VERSION ""

NS_ :

BS_:

BU_: PowertrainControlModule AtmosphericSensor SafetyRestraintSystem2 Aftertreatment_2_GasOutlet Aftertreatment_2_GasIntake DieselParticulateFilterControl Turbocharger SafetyRestraintSystem1 CabDisplay2 Aftertreatment_1_GasOutlet Aftertreatment_1_GasIntake OnBoardDataLogger OffBoardDiagnosticTool2 OffBoardDiagnosticTool1 FileServer ParkingBrakeController SeatController2 FanDriveController SteeringColumnUnit CommunicationUnitRadio CommunicationUnitSatellite CommunicationUnitCellular PropulsionBatteryCharger ChassisController2 ChassisController1 EngineValveControl AuxiliaryHeater2 AuxiliaryHeater1 ClutchUnit RampControl InformationSystem1 SuspensionSystemController2 OilSensor VehicleDynamicStability ExhaustEmissionController TransmissionDisplay2 TransmissionDisplay1 ClimateControl2 WaterPumpController RearAxleSteeringController LightingOperatorControl SeatController1 IgnitionController2 IgnitionController1 TirePressureController CabController2 CabController1 PneumaticSystemController SuspensionSystemController1 HydraulicPumpController EnduranceBrakingSystem RetarderExhaustEngine2 OnBoardDiagnosticUnit HeadwayController RetarderExhaustEngine1 CabDisplay1 ManagementComputer VirtualTerminal OffVehicleGateway PowerTakeOffFront HitchControl AuxiliaryValveControl BodyController TractorTrailerBridge1 StarterSystem ElectricalSystem VehicleSecurity VehicleNavigation AerodynamicControl ElectricalChargingSystem ClimateControl1 TripRecorder InstrumentCluster SuspensionDriveAxle2 SuspensionDriveAxle1 SuspensionSteerAxle SteeringController FuelSystem CruiseControl RetarderDriveline RetarderEngine BrakesDriveAxle2 BrakesDriveAxle1 BrakesSystemController BrakesSteerAxle AxleDrive2 AxleDrive1 AxleSteering PowerTakeOff ShiftConsoleSecondary ShiftConsolePrimary Transmission2 Transmission1 Engine2 Engine1

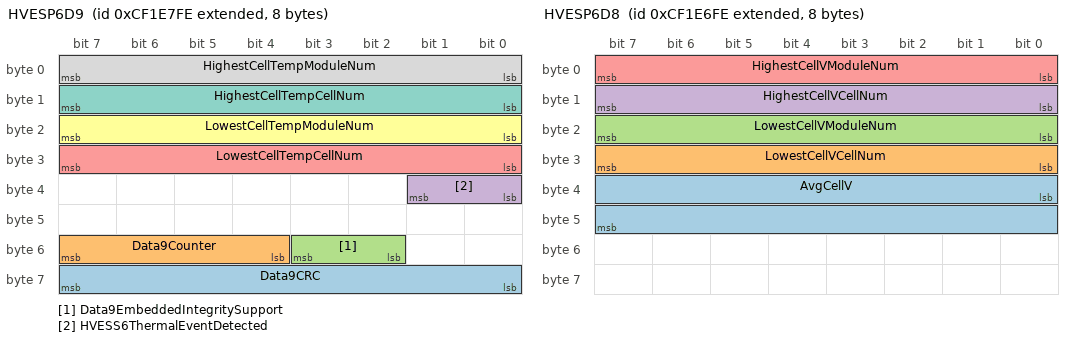
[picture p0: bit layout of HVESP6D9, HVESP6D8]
BO_ 2364663806 HVESP6D9: 8 Vector__XXX
 SG_ Data9CRC : 56|8@1+ (1,0) [0|255] "" Vector__XXX
 SG_ Data9Counter : 52|4@1+ (1,0) [0|15] "" Vector__XXX
 SG_ Data9EmbeddedIntegritySupport : 50|2@1+ (1,0) [0|3] "" Vector__XXX
 SG_ HVESS6ThermalEventDetected : 32|2@1+ (1,0) [0|3] "" Vector__XXX
 SG_ LowestCellTempCellNum : 24|8@1+ (1,0) [0|250] "" Vector__XXX
 SG_ LowestCellTempModuleNum : 16|8@1+ (1,0) [0|250] "" Vector__XXX
 SG_ HighestCellTempCellNum : 8|8@1+ (1,0) [0|250] "" Vector__XXX
 SG_ HighestCellTempModuleNum : 0|8@1+ (1,0) [0|250] "" Vector__XXX

BO_ 2364663550 HVESP6D8: 8 Vector__XXX
 SG_ AvgCellV : 32|16@1+ (0.001,0) [0|64.255] "V" Vector__XXX
 SG_ LowestCellVCellNum : 24|8@1+ (1,0) [0|250] "" Vector__XXX
 SG_ LowestCellVModuleNum : 16|8@1+ (1,0) [0|250] "" Vector__XXX
 SG_ HighestCellVCellNum : 8|8@1+ (1,0) [0|250] "" Vector__XXX
 SG_ HighestCellVModuleNum : 0|8@1+ (1,0) [0|250] "" Vector__XXX

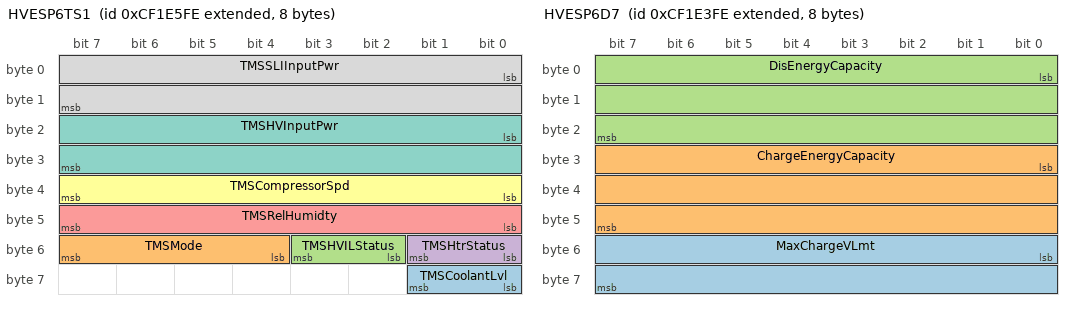
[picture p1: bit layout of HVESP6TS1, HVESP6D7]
BO_ 2364663294 HVESP6TS1: 8 Vector__XXX
 SG_ TMSCoolantLvl : 56|2@1+ (1,0) [0|3] "" Vector__XXX
 SG_ TMSMode : 52|4@1+ (1,0) [0|15] "" Vector__XXX
 SG_ TMSHVILStatus : 50|2@1+ (1,0) [0|3] "" Vector__XXX
 SG_ TMSHtrStatus : 48|2@1+ (1,0) [0|3] "" Vector__XXX
 SG_ TMSRelHumidty : 40|8@1+ (0.4,0) [0|100] "%" Vector__XXX
 SG_ TMSCompressorSpd : 32|8@1+ (32,0) [0|8000] "rpm" Vector__XXX
 SG_ TMSHVInputPwr : 16|16@1+ (0.5,0) [0|32127.5] "W" Vector__XXX
 SG_ TMSSLIInputPwr : 0|16@1+ (0.5,0) [0|32127.5] "W" Vector__XXX

BO_ 2364663038 HVESP6MS1: 8 Vector__XXX
 SG_ Module32OperationalStatus : 62|2@1+ (1,0) [0|3] "" Vector__XXX
 SG_ Module31OperationalStatus : 60|2@1+ (1,0) [0|3] "" Vector__XXX
 SG_ Module30OperationalStatus : 58|2@1+ (1,0) [0|3] "" Vector__XXX
 SG_ Module29OperationalStatus : 56|2@1+ (1,0) [0|3] "" Vector__XXX
 SG_ Module28OperationalStatus : 54|2@1+ (1,0) [0|3] "" Vector__XXX
 SG_ Module27OperationalStatus : 52|2@1+ (1,0) [0|3] "" Vector__XXX
 SG_ Module26OperationalStatus : 50|2@1+ (1,0) [0|3] "" Vector__XXX
 SG_ Module25OperationalStatus : 48|2@1+ (1,0) [0|3] "" Vector__XXX
 SG_ Module24OperationalStatus : 46|2@1+ (1,0) [0|3] "" Vector__XXX
 SG_ Module23OperationalStatus : 44|2@1+ (1,0) [0|3] "" Vector__XXX
 SG_ Module22OperationalStatus : 42|2@1+ (1,0) [0|3] "" Vector__XXX
 SG_ Module21OperationalStatus : 40|2@1+ (1,0) [0|3] "" Vector__XXX
 SG_ Module20OperationalStatus : 38|2@1+ (1,0) [0|3] "" Vector__XXX
 SG_ Module19OperationalStatus : 36|2@1+ (1,0) [0|3] "" Vector__XXX
 SG_ Module18OperationalStatus : 34|2@1+ (1,0) [0|3] "" Vector__XXX
 SG_ Module17OperationalStatus : 32|2@1+ (1,0) [0|3] "" Vector__XXX
 SG_ Module16OperationalStatus : 30|2@1+ (1,0) [0|3] "" Vector__XXX
 SG_ Module15OperationalStatus : 28|2@1+ (1,0) [0|3] "" Vector__XXX
 SG_ Module14OperationalStatus : 26|2@1+ (1,0) [0|3] "" Vector__XXX
 SG_ Module13OperationalStatus : 24|2@1+ (1,0) [0|3] "" Vector__XXX
 SG_ Module12OperationalStatus : 22|2@1+ (1,0) [0|3] "" Vector__XXX
 SG_ Module11OperationalStatus : 20|2@1+ (1,0) [0|3] "" Vector__XXX
 SG_ Module10OperationalStatus : 18|2@1+ (1,0) [0|3] "" Vector__XXX
 SG_ Module9OperationalStatus : 16|2@1+ (1,0) [0|3] "" Vector__XXX
 SG_ Module8OperationalStatus : 14|2@1+ (1,0) [0|3] "" Vector__XXX
 SG_ Module7OperationalStatus : 12|2@1+ (1,0) [0|3] "" Vector__XXX
 SG_ Module6OperationalStatus : 10|2@1+ (1,0) [0|3] "" Vector__XXX
 SG_ Module5OperationalStatus : 8|2@1+ (1,0) [0|3] "" Vector__XXX
 SG_ Module4OperationalStatus : 6|2@1+ (1,0) [0|3] "" Vector__XXX
 SG_ Module3OperationalStatus : 4|2@1+ (1,0) [0|3] "" Vector__XXX
 SG_ Module2OperationalStatus : 2|2@1+ (1,0) [0|3] "" Vector__XXX
 SG_ Module1OperationalStatus : 0|2@1+ (1,0) [0|3] "" Vector__XXX

BO_ 2364662782 HVESP6D7: 8 Vector__XXX
 SG_ MaxChargeVLmt : 48|16@1+ (0.05,0) [0|3212.75] "V" Vector__XXX
 SG_ ChargeEnergyCapacity : 24|24@1+ (0.001,0) [0|16449.535] "kWh" Vector__XXX
 SG_ DisEnergyCapacity : 0|24@1+ (0.001,0) [0|16449.535] "kWh" Vector__XXX

BO_ 2364662526 HVESP6S1: 8 Vector__XXX
 SG_ Status1CRC : 56|8@1+ (1,0) [0|255] "" Vector__XXX
 SG_ Status1Counter : 52|4@1+ (1,0) [0|15] "" Vector__XXX
 SG_ OperationalStatus : 44|4@1+ (1,0) [0|15] "" Vector__XXX
 SG_ HVBusConnectionStatus : 40|4@1+ (1,0) [0|15] "" Vector__XXX
 SG_ InternalChargerStatus : 32|2@1+ (1,0) [0|3] "" Vector__XXX
 SG_ CellBalancingActive : 30|2@1+ (1,0) [0|3] "" Vector__XXX
 SG_ CellBalanceStatus : 28|2@1+ (1,0) [0|3] "" Vector__XXX
 SG_ StOfChargeStatus : 24|4@1+ (1,0) [0|15] "" Vector__XXX
 SG_ InertiaSwStatus : 22|2@1+ (1,0) [0|3] "" Vector__XXX
 SG_ HVILStatus : 20|2@1+ (1,0) [0|3] "" Vector__XXX
 SG_ HVBusPassiveIsolTestStatus : 16|4@1+ (1,0) [0|15] "" Vector__XXX
 SG_ HVBusActiveIsolTestStatus : 12|4@1+ (1,0) [0|15] "" Vector__XXX
 SG_ CenterOfPackContactorSt : 10|2@1+ (1,0) [0|3] "" Vector__XXX
 SG_ HVBusPreChargeRelaySt : 8|2@1+ (1,0) [0|3] "" Vector__XXX
 SG_ HVBusDisconnectForewarning : 4|4@1+ (1,0) [0|15] "" Vector__XXX
 SG_ HVBusContactorSt11656 : 2|2@1+ (1,0) [0|3] "" Vector__XXX
 SG_ HVBusContactorSt : 0|2@1+ (1,0) [0|3] "" Vector__XXX

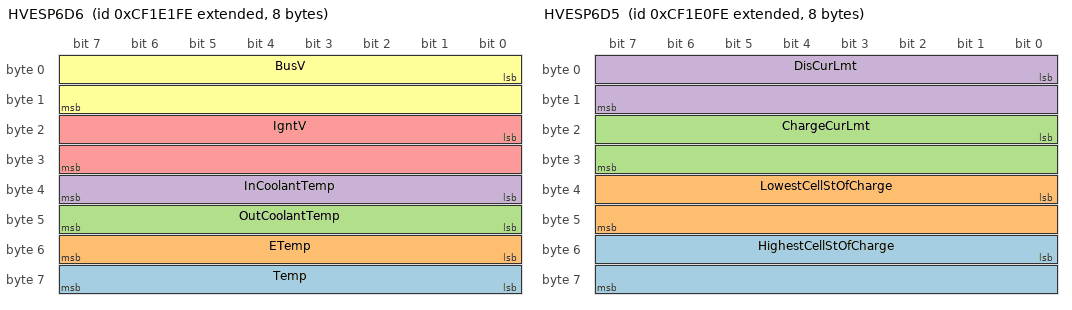
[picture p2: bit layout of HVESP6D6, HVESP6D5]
BO_ 2364662270 HVESP6D6: 8 Vector__XXX
 SG_ Temp : 56|8@1+ (1,-40) [-40|210] "°C" Vector__XXX
 SG_ ETemp : 48|8@1+ (1,-40) [-40|210] "°C" Vector__XXX
 SG_ OutCoolantTemp : 40|8@1+ (1,-40) [-40|210] "°C" Vector__XXX
 SG_ InCoolantTemp : 32|8@1+ (1,-40) [-40|210] "°C" Vector__XXX
 SG_ IgntV : 16|16@1+ (0.01,0) [0|642.55] "V" Vector__XXX
 SG_ BusV : 0|16@1+ (0.05,0) [0|3212.75] "V" Vector__XXX

BO_ 2364662014 HVESP6D5: 8 Vector__XXX
 SG_ HighestCellStOfCharge : 48|16@1+ (0.0015625,0) [0|100.3984375] "%" Vector__XXX
 SG_ LowestCellStOfCharge : 32|16@1+ (0.0015625,0) [0|100.3984375] "%" Vector__XXX
 SG_ ChargeCurLmt : 16|16@1+ (0.05,-1600) [0|1612.75] "A" Vector__XXX
 SG_ DisCurLmt : 0|16@1+ (0.05,-1600) [-1600|0] "A" Vector__XXX

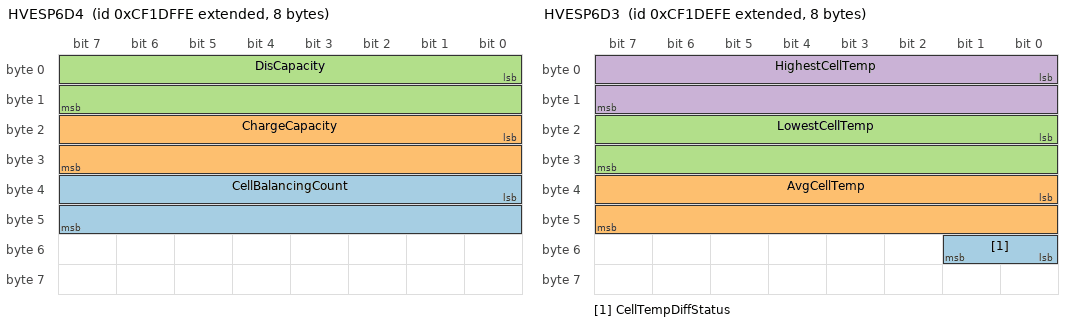
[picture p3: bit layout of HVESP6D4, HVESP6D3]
BO_ 2364661758 HVESP6D4: 8 Vector__XXX
 SG_ CellBalancingCount : 32|16@1+ (1,0) [0|64255] "" Vector__XXX
 SG_ ChargeCapacity : 16|16@1+ (0.01,0) [0|642.55] "Ah" Vector__XXX
 SG_ DisCapacity : 0|16@1+ (0.01,0) [0|642.55] "Ah" Vector__XXX

BO_ 2364661502 HVESP6D3: 8 Vector__XXX
 SG_ CellTempDiffStatus : 48|2@1+ (1,0) [0|3] "" Vector__XXX
 SG_ AvgCellTemp : 32|16@1+ (0.03125,-273) [-273|1734.96875] "°C" Vector__XXX
 SG_ LowestCellTemp : 16|16@1+ (0.03125,-273) [-273|1734.96875] "°C" Vector__XXX
 SG_ HighestCellTemp : 0|16@1+ (0.03125,-273) [-273|1734.96875] "°C" Vector__XXX

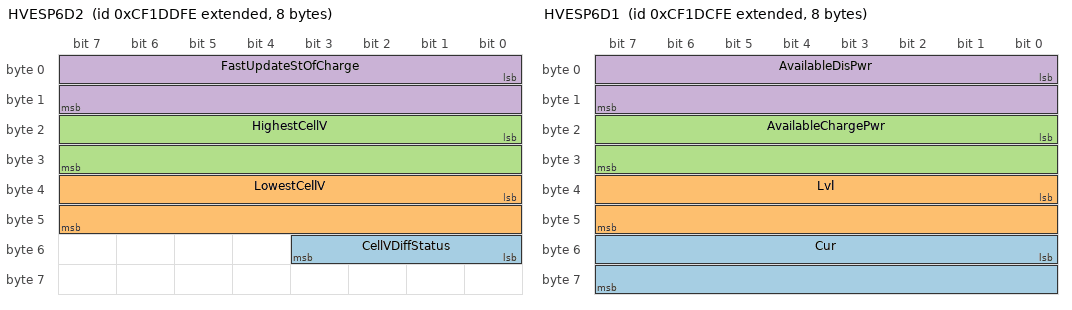
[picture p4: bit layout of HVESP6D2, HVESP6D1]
BO_ 2364661246 HVESP6D2: 8 Vector__XXX
 SG_ CellVDiffStatus : 48|4@1+ (1,0) [0|15] "" Vector__XXX
 SG_ LowestCellV : 32|16@1+ (0.001,0) [0|64.255] "V" Vector__XXX
 SG_ HighestCellV : 16|16@1+ (0.001,0) [0|64.255] "V" Vector__XXX
 SG_ FastUpdateStOfCharge : 0|16@1+ (0.0015625,0) [0|100.3984375] "%" Vector__XXX

BO_ 2364660990 HVESP6D1: 8 Vector__XXX
 SG_ Cur : 48|16@1+ (0.05,-1600) [-1600|1612.75] "A" Vector__XXX
 SG_ Lvl : 32|16@1+ (0.05,0) [0|3212.75] "V" Vector__XXX
 SG_ AvailableChargePwr : 16|16@1+ (0.05,0) [0|3212.75] "kW" Vector__XXX
 SG_ AvailableDisPwr : 0|16@1+ (0.05,0) [0|3212.75] "kW" Vector__XXX

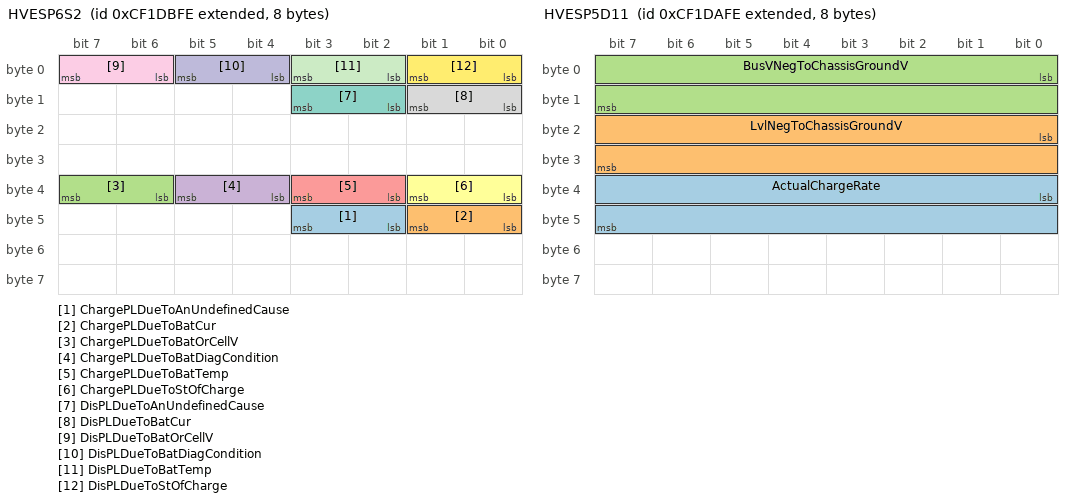
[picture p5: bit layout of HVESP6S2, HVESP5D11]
BO_ 2364660734 HVESP6S2: 8 Vector__XXX
 SG_ ChargePLDueToAnUndefinedCause : 42|2@1+ (1,0) [0|3] "" Vector__XXX
 SG_ ChargePLDueToBatCur : 40|2@1+ (1,0) [0|3] "" Vector__XXX
 SG_ ChargePLDueToBatOrCellV : 38|2@1+ (1,0) [0|3] "" Vector__XXX
 SG_ ChargePLDueToBatDiagCondition : 36|2@1+ (1,0) [0|3] "" Vector__XXX
 SG_ ChargePLDueToBatTemp : 34|2@1+ (1,0) [0|3] "" Vector__XXX
 SG_ ChargePLDueToStOfCharge : 32|2@1+ (1,0) [0|3] "" Vector__XXX
 SG_ DisPLDueToAnUndefinedCause : 10|2@1+ (1,0) [0|3] "" Vector__XXX
 SG_ DisPLDueToBatCur : 8|2@1+ (1,0) [0|3] "" Vector__XXX
 SG_ DisPLDueToBatOrCellV : 6|2@1+ (1,0) [0|3] "" Vector__XXX
 SG_ DisPLDueToBatDiagCondition : 4|2@1+ (1,0) [0|3] "" Vector__XXX
 SG_ DisPLDueToBatTemp : 2|2@1+ (1,0) [0|3] "" Vector__XXX
 SG_ DisPLDueToStOfCharge : 0|2@1+ (1,0) [0|3] "" Vector__XXX

BO_ 2364660478 HVESP5D11: 8 Vector__XXX
 SG_ ActualChargeRate : 32|16@1+ (0.05,0) [0|3212.75] "kW" Vector__XXX
 SG_ LvlNegToChassisGroundV : 16|16@1+ (0.05,0) [0|3212.75] "V" Vector__XXX
 SG_ BusVNegToChassisGroundV : 0|16@1+ (0.05,0) [0|3212.75] "V" Vector__XXX

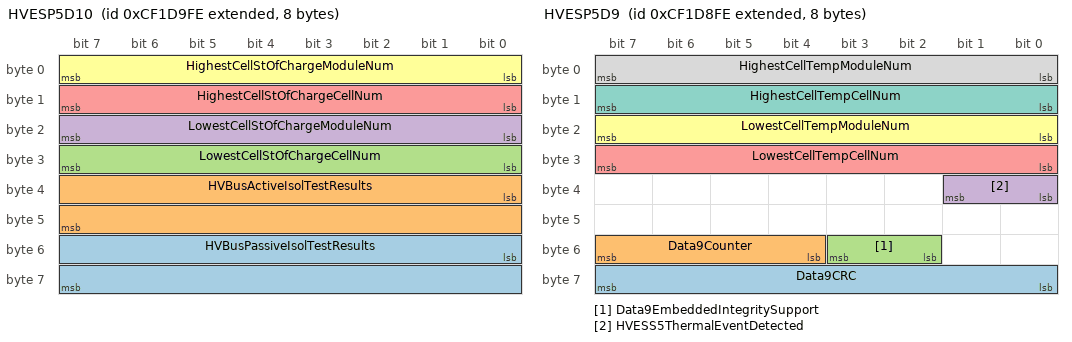
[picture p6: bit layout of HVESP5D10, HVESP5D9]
BO_ 2364660222 HVESP5D10: 8 Vector__XXX
 SG_ HVBusPassiveIsolTestResults : 48|16@1+ (0.1,0) [0|6425.5] "Ohm/V" Vector__XXX
 SG_ HVBusActiveIsolTestResults : 32|16@1+ (0.1,0) [0|6425.5] "Ohm/V" Vector__XXX
 SG_ LowestCellStOfChargeCellNum : 24|8@1+ (1,0) [0|250] "" Vector__XXX
 SG_ LowestCellStOfChargeModuleNum : 16|8@1+ (1,0) [0|250] "" Vector__XXX
 SG_ HighestCellStOfChargeCellNum : 8|8@1+ (1,0) [0|250] "" Vector__XXX
 SG_ HighestCellStOfChargeModuleNum : 0|8@1+ (1,0) [0|250] "" Vector__XXX

BO_ 2364659966 HVESP5D9: 8 Vector__XXX
 SG_ Data9CRC : 56|8@1+ (1,0) [0|255] "" Vector__XXX
 SG_ Data9Counter : 52|4@1+ (1,0) [0|15] "" Vector__XXX
 SG_ Data9EmbeddedIntegritySupport : 50|2@1+ (1,0) [0|3] "" Vector__XXX
 SG_ HVESS5ThermalEventDetected : 32|2@1+ (1,0) [0|3] "" Vector__XXX
 SG_ LowestCellTempCellNum : 24|8@1+ (1,0) [0|250] "" Vector__XXX
 SG_ LowestCellTempModuleNum : 16|8@1+ (1,0) [0|250] "" Vector__XXX
 SG_ HighestCellTempCellNum : 8|8@1+ (1,0) [0|250] "" Vector__XXX
 SG_ HighestCellTempModuleNum : 0|8@1+ (1,0) [0|250] "" Vector__XXX

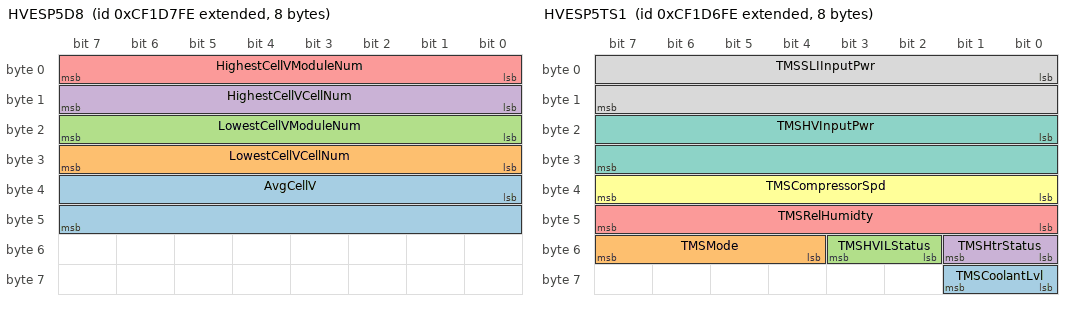
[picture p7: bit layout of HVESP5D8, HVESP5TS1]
BO_ 2364659710 HVESP5D8: 8 Vector__XXX
 SG_ AvgCellV : 32|16@1+ (0.001,0) [0|64.255] "V" Vector__XXX
 SG_ LowestCellVCellNum : 24|8@1+ (1,0) [0|250] "" Vector__XXX
 SG_ LowestCellVModuleNum : 16|8@1+ (1,0) [0|250] "" Vector__XXX
 SG_ HighestCellVCellNum : 8|8@1+ (1,0) [0|250] "" Vector__XXX
 SG_ HighestCellVModuleNum : 0|8@1+ (1,0) [0|250] "" Vector__XXX

BO_ 2364659454 HVESP5TS1: 8 Vector__XXX
 SG_ TMSCoolantLvl : 56|2@1+ (1,0) [0|3] "" Vector__XXX
 SG_ TMSMode : 52|4@1+ (1,0) [0|15] "" Vector__XXX
 SG_ TMSHVILStatus : 50|2@1+ (1,0) [0|3] "" Vector__XXX
 SG_ TMSHtrStatus : 48|2@1+ (1,0) [0|3] "" Vector__XXX
 SG_ TMSRelHumidty : 40|8@1+ (0.4,0) [0|100] "%" Vector__XXX
 SG_ TMSCompressorSpd : 32|8@1+ (32,0) [0|8000] "rpm" Vector__XXX
 SG_ TMSHVInputPwr : 16|16@1+ (0.5,0) [0|32127.5] "W" Vector__XXX
 SG_ TMSSLIInputPwr : 0|16@1+ (0.5,0) [0|32127.5] "W" Vector__XXX

BO_ 2364659198 HVESP5MS1: 8 Vector__XXX
 SG_ Module32OperationalStatus : 62|2@1+ (1,0) [0|3] "" Vector__XXX
 SG_ Module31OperationalStatus : 60|2@1+ (1,0) [0|3] "" Vector__XXX
 SG_ Module30OperationalStatus : 58|2@1+ (1,0) [0|3] "" Vector__XXX
 SG_ Module29OperationalStatus : 56|2@1+ (1,0) [0|3] "" Vector__XXX
 SG_ Module28OperationalStatus : 54|2@1+ (1,0) [0|3] "" Vector__XXX
 SG_ Module27OperationalStatus : 52|2@1+ (1,0) [0|3] "" Vector__XXX
 SG_ Module26OperationalStatus : 50|2@1+ (1,0) [0|3] "" Vector__XXX
 SG_ Module25OperationalStatus : 48|2@1+ (1,0) [0|3] "" Vector__XXX
 SG_ Module24OperationalStatus : 46|2@1+ (1,0) [0|3] "" Vector__XXX
 SG_ Module23OperationalStatus : 44|2@1+ (1,0) [0|3] "" Vector__XXX
 SG_ Module22OperationalStatus : 42|2@1+ (1,0) [0|3] "" Vector__XXX
 SG_ Module21OperationalStatus : 40|2@1+ (1,0) [0|3] "" Vector__XXX
 SG_ Module20OperationalStatus : 38|2@1+ (1,0) [0|3] "" Vector__XXX
 SG_ Module19OperationalStatus : 36|2@1+ (1,0) [0|3] "" Vector__XXX
 SG_ Module18OperationalStatus : 34|2@1+ (1,0) [0|3] "" Vector__XXX
 SG_ Module17OperationalStatus : 32|2@1+ (1,0) [0|3] "" Vector__XXX
 SG_ Module16OperationalStatus : 30|2@1+ (1,0) [0|3] "" Vector__XXX
 SG_ Module15OperationalStatus : 28|2@1+ (1,0) [0|3] "" Vector__XXX
 SG_ Module14OperationalStatus : 26|2@1+ (1,0) [0|3] "" Vector__XXX
 SG_ Module13OperationalStatus : 24|2@1+ (1,0) [0|3] "" Vector__XXX
 SG_ Module12OperationalStatus : 22|2@1+ (1,0) [0|3] "" Vector__XXX
 SG_ Module11OperationalStatus : 20|2@1+ (1,0) [0|3] "" Vector__XXX
 SG_ Module10OperationalStatus : 18|2@1+ (1,0) [0|3] "" Vector__XXX
 SG_ Module9OperationalStatus : 16|2@1+ (1,0) [0|3] "" Vector__XXX
 SG_ Module8OperationalStatus : 14|2@1+ (1,0) [0|3] "" Vector__XXX
 SG_ Module7OperationalStatus : 12|2@1+ (1,0) [0|3] "" Vector__XXX
 SG_ Module6OperationalStatus : 10|2@1+ (1,0) [0|3] "" Vector__XXX
 SG_ Module5OperationalStatus : 8|2@1+ (1,0) [0|3] "" Vector__XXX
 SG_ Module4OperationalStatus : 6|2@1+ (1,0) [0|3] "" Vector__XXX
 SG_ Module3OperationalStatus : 4|2@1+ (1,0) [0|3] "" Vector__XXX
 SG_ Module2OperationalStatus : 2|2@1+ (1,0) [0|3] "" Vector__XXX
 SG_ Module1OperationalStatus : 0|2@1+ (1,0) [0|3] "" Vector__XXX

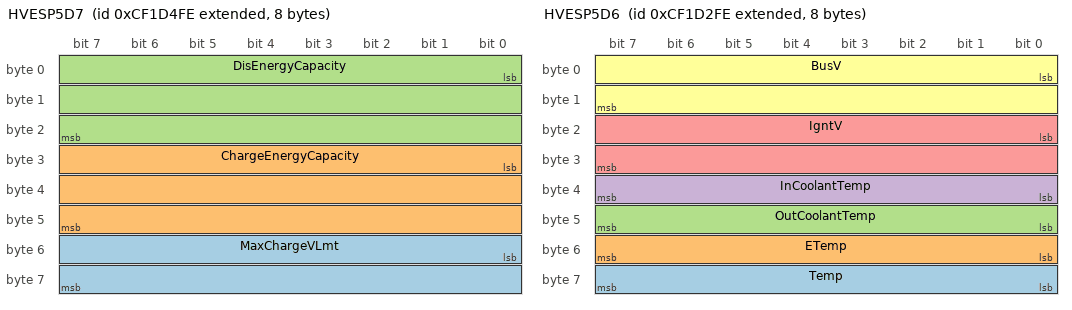
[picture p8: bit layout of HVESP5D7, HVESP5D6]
BO_ 2364658942 HVESP5D7: 8 Vector__XXX
 SG_ MaxChargeVLmt : 48|16@1+ (0.05,0) [0|3212.75] "V" Vector__XXX
 SG_ ChargeEnergyCapacity : 24|24@1+ (0.001,0) [0|16449.535] "kWh" Vector__XXX
 SG_ DisEnergyCapacity : 0|24@1+ (0.001,0) [0|16449.535] "kWh" Vector__XXX

BO_ 2364658686 HVESP5S1: 8 Vector__XXX
 SG_ Status1CRC : 56|8@1+ (1,0) [0|255] "" Vector__XXX
 SG_ Status1Counter : 52|4@1+ (1,0) [0|15] "" Vector__XXX
 SG_ OperationalStatus : 44|4@1+ (1,0) [0|15] "" Vector__XXX
 SG_ HVBusConnectionStatus : 40|4@1+ (1,0) [0|15] "" Vector__XXX
 SG_ InternalChargerStatus : 32|2@1+ (1,0) [0|3] "" Vector__XXX
 SG_ CellBalancingActive : 30|2@1+ (1,0) [0|3] "" Vector__XXX
 SG_ CellBalanceStatus : 28|2@1+ (1,0) [0|3] "" Vector__XXX
 SG_ StOfChargeStatus : 24|4@1+ (1,0) [0|15] "" Vector__XXX
 SG_ InertiaSwStatus : 22|2@1+ (1,0) [0|3] "" Vector__XXX
 SG_ HVILStatus : 20|2@1+ (1,0) [0|3] "" Vector__XXX
 SG_ HVBusPassiveIsolTestStatus : 16|4@1+ (1,0) [0|15] "" Vector__XXX
 SG_ HVBusActiveIsolTestStatus : 12|4@1+ (1,0) [0|15] "" Vector__XXX
 SG_ CenterOfPackContactorSt : 10|2@1+ (1,0) [0|3] "" Vector__XXX
 SG_ HVBusPreChargeRelaySt : 8|2@1+ (1,0) [0|3] "" Vector__XXX
 SG_ HVBusDisconnectForewarning : 4|4@1+ (1,0) [0|15] "" Vector__XXX
 SG_ HVBusContactorSt11540 : 2|2@1+ (1,0) [0|3] "" Vector__XXX
 SG_ HVBusContactorSt : 0|2@1+ (1,0) [0|3] "" Vector__XXX

BO_ 2364658430 HVESP5D6: 8 Vector__XXX
 SG_ Temp : 56|8@1+ (1,-40) [-40|210] "°C" Vector__XXX
 SG_ ETemp : 48|8@1+ (1,-40) [-40|210] "°C" Vector__XXX
 SG_ OutCoolantTemp : 40|8@1+ (1,-40) [-40|210] "°C" Vector__XXX
 SG_ InCoolantTemp : 32|8@1+ (1,-40) [-40|210] "°C" Vector__XXX
 SG_ IgntV : 16|16@1+ (0.01,0) [0|642.55] "V" Vector__XXX
 SG_ BusV : 0|16@1+ (0.05,0) [0|3212.75] "V" Vector__XXX

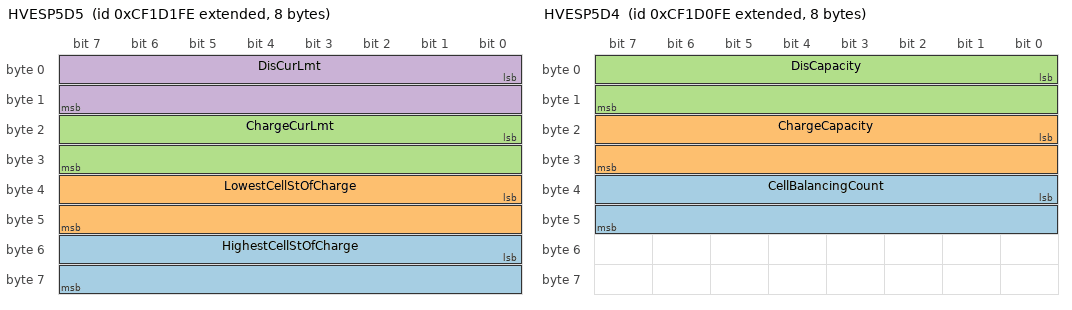
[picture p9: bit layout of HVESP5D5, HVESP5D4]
BO_ 2364658174 HVESP5D5: 8 Vector__XXX
 SG_ HighestCellStOfCharge : 48|16@1+ (0.0015625,0) [0|100.3984375] "%" Vector__XXX
 SG_ LowestCellStOfCharge : 32|16@1+ (0.0015625,0) [0|100.3984375] "%" Vector__XXX
 SG_ ChargeCurLmt : 16|16@1+ (0.05,-1600) [0|1612.75] "A" Vector__XXX
 SG_ DisCurLmt : 0|16@1+ (0.05,-1600) [-1600|0] "A" Vector__XXX

BO_ 2364657918 HVESP5D4: 8 Vector__XXX
 SG_ CellBalancingCount : 32|16@1+ (1,0) [0|64255] "" Vector__XXX
 SG_ ChargeCapacity : 16|16@1+ (0.01,0) [0|642.55] "Ah" Vector__XXX
 SG_ DisCapacity : 0|16@1+ (0.01,0) [0|642.55] "Ah" Vector__XXX

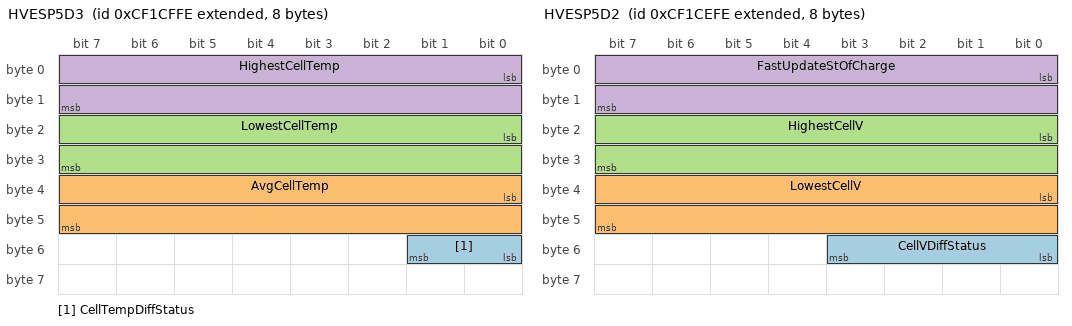
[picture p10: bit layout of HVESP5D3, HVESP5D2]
BO_ 2364657662 HVESP5D3: 8 Vector__XXX
 SG_ CellTempDiffStatus : 48|2@1+ (1,0) [0|3] "" Vector__XXX
 SG_ AvgCellTemp : 32|16@1+ (0.03125,-273) [-273|1734.96875] "°C" Vector__XXX
 SG_ LowestCellTemp : 16|16@1+ (0.03125,-273) [-273|1734.96875] "°C" Vector__XXX
 SG_ HighestCellTemp : 0|16@1+ (0.03125,-273) [-273|1734.96875] "°C" Vector__XXX

BO_ 2364657406 HVESP5D2: 8 Vector__XXX
 SG_ CellVDiffStatus : 48|4@1+ (1,0) [0|15] "" Vector__XXX
 SG_ LowestCellV : 32|16@1+ (0.001,0) [0|64.255] "V" Vector__XXX
 SG_ HighestCellV : 16|16@1+ (0.001,0) [0|64.255] "V" Vector__XXX
 SG_ FastUpdateStOfCharge : 0|16@1+ (0.0015625,0) [0|100.3984375] "%" Vector__XXX

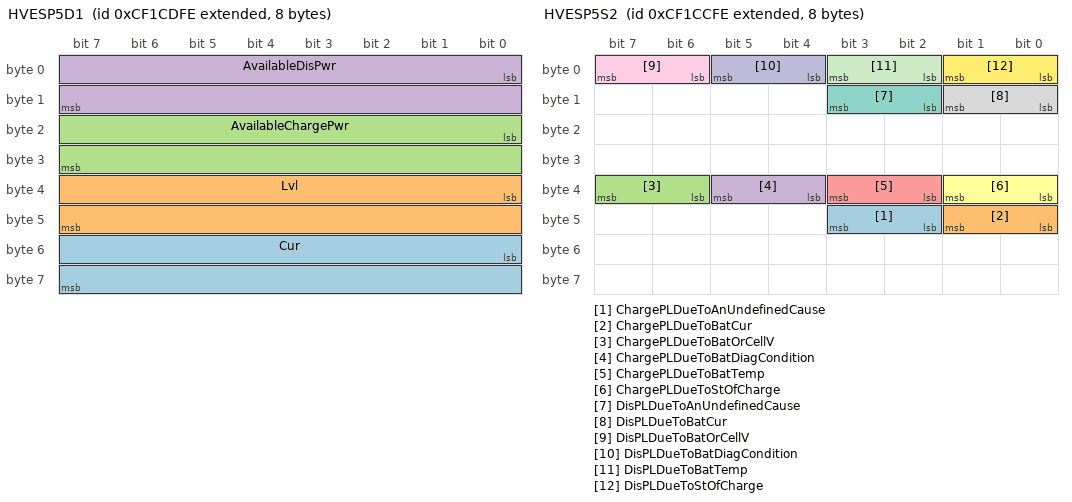
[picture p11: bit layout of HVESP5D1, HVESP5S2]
BO_ 2364657150 HVESP5D1: 8 Vector__XXX
 SG_ Cur : 48|16@1+ (0.05,-1600) [-1600|1612.75] "A" Vector__XXX
 SG_ Lvl : 32|16@1+ (0.05,0) [0|3212.75] "V" Vector__XXX
 SG_ AvailableChargePwr : 16|16@1+ (0.05,0) [0|3212.75] "kW" Vector__XXX
 SG_ AvailableDisPwr : 0|16@1+ (0.05,0) [0|3212.75] "kW" Vector__XXX

BO_ 2364656894 HVESP5S2: 8 Vector__XXX
 SG_ ChargePLDueToAnUndefinedCause : 42|2@1+ (1,0) [0|3] "" Vector__XXX
 SG_ ChargePLDueToBatCur : 40|2@1+ (1,0) [0|3] "" Vector__XXX
 SG_ ChargePLDueToBatOrCellV : 38|2@1+ (1,0) [0|3] "" Vector__XXX
 SG_ ChargePLDueToBatDiagCondition : 36|2@1+ (1,0) [0|3] "" Vector__XXX
 SG_ ChargePLDueToBatTemp : 34|2@1+ (1,0) [0|3] "" Vector__XXX
 SG_ ChargePLDueToStOfCharge : 32|2@1+ (1,0) [0|3] "" Vector__XXX
 SG_ DisPLDueToAnUndefinedCause : 10|2@1+ (1,0) [0|3] "" Vector__XXX
 SG_ DisPLDueToBatCur : 8|2@1+ (1,0) [0|3] "" Vector__XXX
 SG_ DisPLDueToBatOrCellV : 6|2@1+ (1,0) [0|3] "" Vector__XXX
 SG_ DisPLDueToBatDiagCondition : 4|2@1+ (1,0) [0|3] "" Vector__XXX
 SG_ DisPLDueToBatTemp : 2|2@1+ (1,0) [0|3] "" Vector__XXX
 SG_ DisPLDueToStOfCharge : 0|2@1+ (1,0) [0|3] "" Vector__XXX

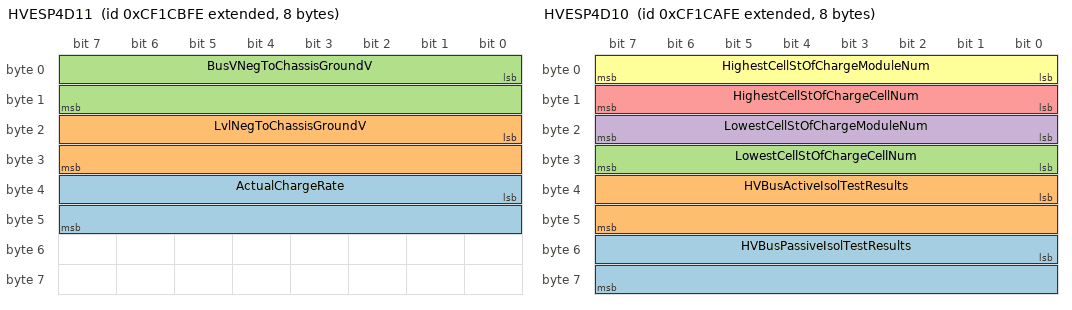
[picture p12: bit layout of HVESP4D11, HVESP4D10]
BO_ 2364656638 HVESP4D11: 8 Vector__XXX
 SG_ ActualChargeRate : 32|16@1+ (0.05,0) [0|3212.75] "kW" Vector__XXX
 SG_ LvlNegToChassisGroundV : 16|16@1+ (0.05,0) [0|3212.75] "V" Vector__XXX
 SG_ BusVNegToChassisGroundV : 0|16@1+ (0.05,0) [0|3212.75] "V" Vector__XXX

BO_ 2364656382 HVESP4D10: 8 Vector__XXX
 SG_ HVBusPassiveIsolTestResults : 48|16@1+ (0.1,0) [0|6425.5] "Ohm/V" Vector__XXX
 SG_ HVBusActiveIsolTestResults : 32|16@1+ (0.1,0) [0|6425.5] "Ohm/V" Vector__XXX
 SG_ LowestCellStOfChargeCellNum : 24|8@1+ (1,0) [0|250] "" Vector__XXX
 SG_ LowestCellStOfChargeModuleNum : 16|8@1+ (1,0) [0|250] "" Vector__XXX
 SG_ HighestCellStOfChargeCellNum : 8|8@1+ (1,0) [0|250] "" Vector__XXX
 SG_ HighestCellStOfChargeModuleNum : 0|8@1+ (1,0) [0|250] "" Vector__XXX

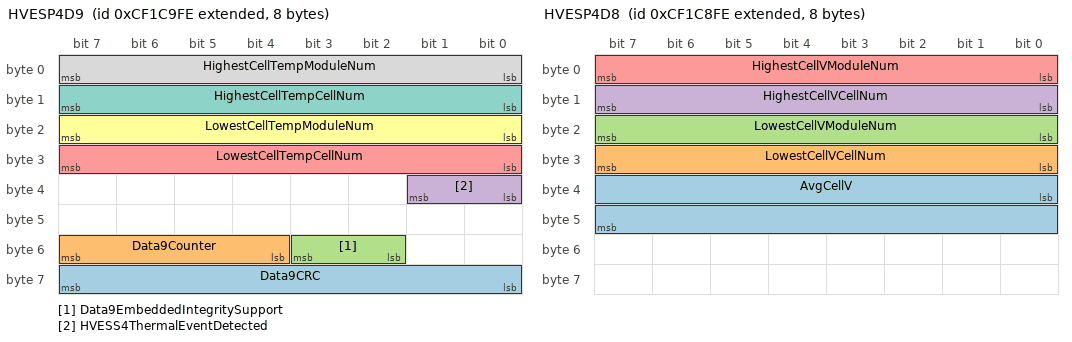
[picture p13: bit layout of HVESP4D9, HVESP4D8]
BO_ 2364656126 HVESP4D9: 8 Vector__XXX
 SG_ Data9CRC : 56|8@1+ (1,0) [0|255] "" Vector__XXX
 SG_ Data9Counter : 52|4@1+ (1,0) [0|15] "" Vector__XXX
 SG_ Data9EmbeddedIntegritySupport : 50|2@1+ (1,0) [0|3] "" Vector__XXX
 SG_ HVESS4ThermalEventDetected : 32|2@1+ (1,0) [0|3] "" Vector__XXX
 SG_ LowestCellTempCellNum : 24|8@1+ (1,0) [0|250] "" Vector__XXX
 SG_ LowestCellTempModuleNum : 16|8@1+ (1,0) [0|250] "" Vector__XXX
 SG_ HighestCellTempCellNum : 8|8@1+ (1,0) [0|250] "" Vector__XXX
 SG_ HighestCellTempModuleNum : 0|8@1+ (1,0) [0|250] "" Vector__XXX

BO_ 2364655870 HVESP4D8: 8 Vector__XXX
 SG_ AvgCellV : 32|16@1+ (0.001,0) [0|64.255] "V" Vector__XXX
 SG_ LowestCellVCellNum : 24|8@1+ (1,0) [0|250] "" Vector__XXX
 SG_ LowestCellVModuleNum : 16|8@1+ (1,0) [0|250] "" Vector__XXX
 SG_ HighestCellVCellNum : 8|8@1+ (1,0) [0|250] "" Vector__XXX
 SG_ HighestCellVModuleNum : 0|8@1+ (1,0) [0|250] "" Vector__XXX

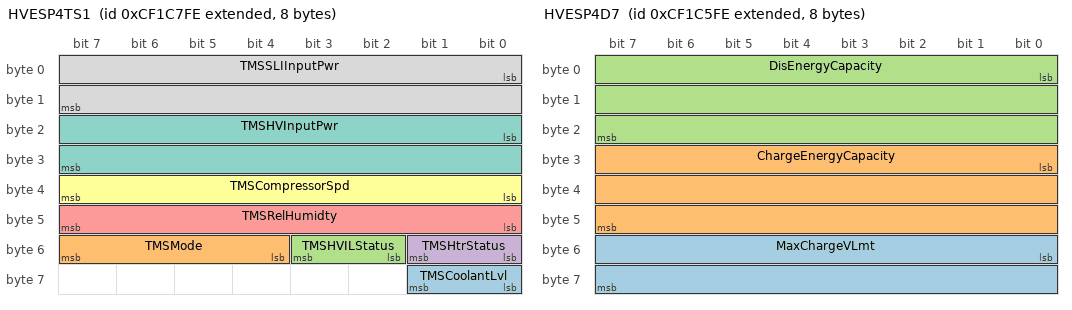
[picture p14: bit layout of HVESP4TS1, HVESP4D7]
BO_ 2364655614 HVESP4TS1: 8 Vector__XXX
 SG_ TMSCoolantLvl : 56|2@1+ (1,0) [0|3] "" Vector__XXX
 SG_ TMSMode : 52|4@1+ (1,0) [0|15] "" Vector__XXX
 SG_ TMSHVILStatus : 50|2@1+ (1,0) [0|3] "" Vector__XXX
 SG_ TMSHtrStatus : 48|2@1+ (1,0) [0|3] "" Vector__XXX
 SG_ TMSRelHumidty : 40|8@1+ (0.4,0) [0|100] "%" Vector__XXX
 SG_ TMSCompressorSpd : 32|8@1+ (32,0) [0|8000] "rpm" Vector__XXX
 SG_ TMSHVInputPwr : 16|16@1+ (0.5,0) [0|32127.5] "W" Vector__XXX
 SG_ TMSSLIInputPwr : 0|16@1+ (0.5,0) [0|32127.5] "W" Vector__XXX

BO_ 2364655358 HVESP4MS1: 8 Vector__XXX
 SG_ Module32OperationalStatus : 62|2@1+ (1,0) [0|3] "" Vector__XXX
 SG_ Module31OperationalStatus : 60|2@1+ (1,0) [0|3] "" Vector__XXX
 SG_ Module30OperationalStatus : 58|2@1+ (1,0) [0|3] "" Vector__XXX
 SG_ Module29OperationalStatus : 56|2@1+ (1,0) [0|3] "" Vector__XXX
 SG_ Module28OperationalStatus : 54|2@1+ (1,0) [0|3] "" Vector__XXX
 SG_ Module27OperationalStatus : 52|2@1+ (1,0) [0|3] "" Vector__XXX
 SG_ Module26OperationalStatus : 50|2@1+ (1,0) [0|3] "" Vector__XXX
 SG_ Module25OperationalStatus : 48|2@1+ (1,0) [0|3] "" Vector__XXX
 SG_ Module24OperationalStatus : 46|2@1+ (1,0) [0|3] "" Vector__XXX
 SG_ Module23OperationalStatus : 44|2@1+ (1,0) [0|3] "" Vector__XXX
 SG_ Module22OperationalStatus : 42|2@1+ (1,0) [0|3] "" Vector__XXX
 SG_ Module21OperationalStatus : 40|2@1+ (1,0) [0|3] "" Vector__XXX
 SG_ Module20OperationalStatus : 38|2@1+ (1,0) [0|3] "" Vector__XXX
 SG_ Module19OperationalStatus : 36|2@1+ (1,0) [0|3] "" Vector__XXX
 SG_ Module18OperationalStatus : 34|2@1+ (1,0) [0|3] "" Vector__XXX
 SG_ Module17OperationalStatus : 32|2@1+ (1,0) [0|3] "" Vector__XXX
 SG_ Module16OperationalStatus : 30|2@1+ (1,0) [0|3] "" Vector__XXX
 SG_ Module15OperationalStatus : 28|2@1+ (1,0) [0|3] "" Vector__XXX
 SG_ Module14OperationalStatus : 26|2@1+ (1,0) [0|3] "" Vector__XXX
 SG_ Module13OperationalStatus : 24|2@1+ (1,0) [0|3] "" Vector__XXX
 SG_ Module12OperationalStatus : 22|2@1+ (1,0) [0|3] "" Vector__XXX
 SG_ Module11OperationalStatus : 20|2@1+ (1,0) [0|3] "" Vector__XXX
 SG_ Module10OperationalStatus : 18|2@1+ (1,0) [0|3] "" Vector__XXX
 SG_ Module9OperationalStatus : 16|2@1+ (1,0) [0|3] "" Vector__XXX
 SG_ Module8OperationalStatus : 14|2@1+ (1,0) [0|3] "" Vector__XXX
 SG_ Module7OperationalStatus : 12|2@1+ (1,0) [0|3] "" Vector__XXX
 SG_ Module6OperationalStatus : 10|2@1+ (1,0) [0|3] "" Vector__XXX
 SG_ Module5OperationalStatus : 8|2@1+ (1,0) [0|3] "" Vector__XXX
 SG_ Module4OperationalStatus : 6|2@1+ (1,0) [0|3] "" Vector__XXX
 SG_ Module3OperationalStatus : 4|2@1+ (1,0) [0|3] "" Vector__XXX
 SG_ Module2OperationalStatus : 2|2@1+ (1,0) [0|3] "" Vector__XXX
 SG_ Module1OperationalStatus : 0|2@1+ (1,0) [0|3] "" Vector__XXX

BO_ 2364655102 HVESP4D7: 8 Vector__XXX
 SG_ MaxChargeVLmt : 48|16@1+ (0.05,0) [0|3212.75] "V" Vector__XXX
 SG_ ChargeEnergyCapacity : 24|24@1+ (0.001,0) [0|16449.535] "kWh" Vector__XXX
 SG_ DisEnergyCapacity : 0|24@1+ (0.001,0) [0|16449.535] "kWh" Vector__XXX

BO_ 2364654846 HVESP4S1: 8 Vector__XXX
 SG_ Status1CRC : 56|8@1+ (1,0) [0|255] "" Vector__XXX
 SG_ Status1Counter : 52|4@1+ (1,0) [0|15] "" Vector__XXX
 SG_ OperationalStatus : 44|4@1+ (1,0) [0|15] "" Vector__XXX
 SG_ HVBusConnectionStatus : 40|4@1+ (1,0) [0|15] "" Vector__XXX
 SG_ InternalChargerStatus : 32|2@1+ (1,0) [0|3] "" Vector__XXX
 SG_ CellBalancingActive : 30|2@1+ (1,0) [0|3] "" Vector__XXX
 SG_ CellBalanceStatus : 28|2@1+ (1,0) [0|3] "" Vector__XXX
 SG_ StOfChargeStatus : 24|4@1+ (1,0) [0|15] "" Vector__XXX
 SG_ InertiaSwStatus : 22|2@1+ (1,0) [0|3] "" Vector__XXX
 SG_ HVILStatus : 20|2@1+ (1,0) [0|3] "" Vector__XXX
 SG_ HVBusPassiveIsolTestStatus : 16|4@1+ (1,0) [0|15] "" Vector__XXX
 SG_ HVBusActiveIsolTestStatus : 12|4@1+ (1,0) [0|15] "" Vector__XXX
 SG_ CenterOfPackContactorSt : 10|2@1+ (1,0) [0|3] "" Vector__XXX
 SG_ HVBusPreChargeRelaySt : 8|2@1+ (1,0) [0|3] "" Vector__XXX
 SG_ HVBusDisconnectForewarning : 4|4@1+ (1,0) [0|15] "" Vector__XXX
 SG_ HVBusContactorSt11424 : 2|2@1+ (1,0) [0|3] "" Vector__XXX
 SG_ HVBusContactorSt : 0|2@1+ (1,0) [0|3] "" Vector__XXX

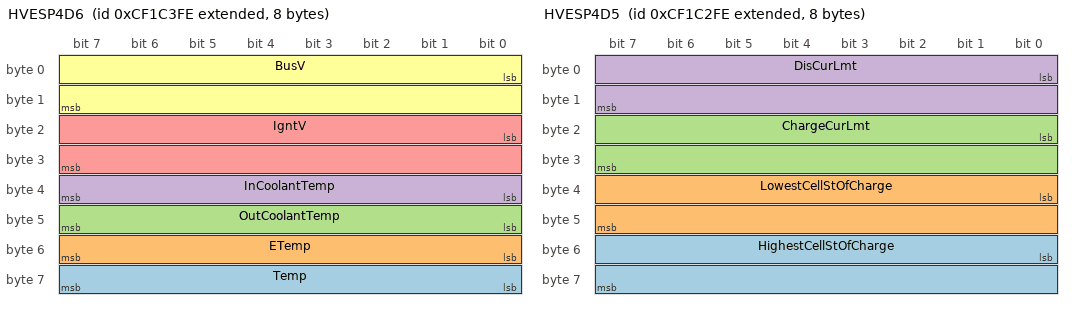
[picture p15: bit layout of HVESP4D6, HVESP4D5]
BO_ 2364654590 HVESP4D6: 8 Vector__XXX
 SG_ Temp : 56|8@1+ (1,-40) [-40|210] "°C" Vector__XXX
 SG_ ETemp : 48|8@1+ (1,-40) [-40|210] "°C" Vector__XXX
 SG_ OutCoolantTemp : 40|8@1+ (1,-40) [-40|210] "°C" Vector__XXX
 SG_ InCoolantTemp : 32|8@1+ (1,-40) [-40|210] "°C" Vector__XXX
 SG_ IgntV : 16|16@1+ (0.01,0) [0|642.55] "V" Vector__XXX
 SG_ BusV : 0|16@1+ (0.05,0) [0|3212.75] "V" Vector__XXX

BO_ 2364654334 HVESP4D5: 8 Vector__XXX
 SG_ HighestCellStOfCharge : 48|16@1+ (0.0015625,0) [0|100.3984375] "%" Vector__XXX
 SG_ LowestCellStOfCharge : 32|16@1+ (0.0015625,0) [0|100.3984375] "%" Vector__XXX
 SG_ ChargeCurLmt : 16|16@1+ (0.05,-1600) [0|1612.75] "A" Vector__XXX
 SG_ DisCurLmt : 0|16@1+ (0.05,-1600) [-1600|0] "A" Vector__XXX

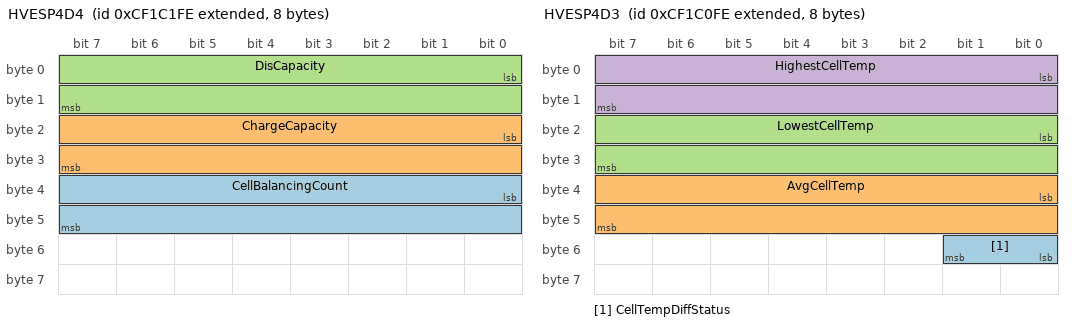
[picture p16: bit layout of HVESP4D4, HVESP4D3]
BO_ 2364654078 HVESP4D4: 8 Vector__XXX
 SG_ CellBalancingCount : 32|16@1+ (1,0) [0|64255] "" Vector__XXX
 SG_ ChargeCapacity : 16|16@1+ (0.01,0) [0|642.55] "Ah" Vector__XXX
 SG_ DisCapacity : 0|16@1+ (0.01,0) [0|642.55] "Ah" Vector__XXX

BO_ 2364653822 HVESP4D3: 8 Vector__XXX
 SG_ CellTempDiffStatus : 48|2@1+ (1,0) [0|3] "" Vector__XXX
 SG_ AvgCellTemp : 32|16@1+ (0.03125,-273) [-273|1734.96875] "°C" Vector__XXX
 SG_ LowestCellTemp : 16|16@1+ (0.03125,-273) [-273|1734.96875] "°C" Vector__XXX
 SG_ HighestCellTemp : 0|16@1+ (0.03125,-273) [-273|1734.96875] "°C" Vector__XXX

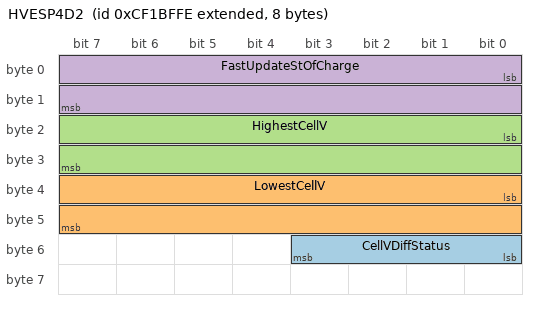
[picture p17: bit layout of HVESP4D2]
BO_ 2364653566 HVESP4D2: 8 Vector__XXX
 SG_ CellVDiffStatus : 48|4@1+ (1,0) [0|15] "" Vector__XXX
 SG_ LowestCellV : 32|16@1+ (0.001,0) [0|64.255] "V" Vector__XXX
 SG_ HighestCellV : 16|16@1+ (0.001,0) [0|64.255] "V" Vector__XXX
 SG_ FastUpdateStOfCharge : 0|16@1+ (0.0015625,0) [0|100.3984375] "%" Vector__XXX

CM_ BO_ 2364663806 "High Voltage Energy Storage Pack 6 Data 9
Data set 9 (thermal) for High Voltage Energy Storage Pack 6.";
CM_ SG_ 2364663806 Data9CRC "The CRC is defined as follows:
• Length: 8 bits
• Polynomial: x^8+x^5+x^3+x^2+x+1
• Initial Value: FFh
• Input Data Reflection: Not reflected
• Result Data Reflection: Not reflected
• XOR value: FFh
SAE makes no claim of the functional safety ...";
CM_ SG_ 2364663806 Data9Counter "The message counter is used to detect situations where the transmitting ECU malfunction repeats the same frame all the time. The receiver of the information may use the counter parameter to detect this situation. The transmitting device will ...";
CM_ SG_ 2364663806 Data9EmbeddedIntegritySupport "Indicates SPN 22991 (HVESP6 Data 9 CRC) and SPN 22990 (HVESP6 Data 9 Counter) are supported by the sender.
00b = Embedded CRC and Counter are supported by the sender
01b = Protection is supported using J1939-76 SHM
10b = Reserved
11b = CRC and ...";
CM_ SG_ 2364663806 HVESS6ThermalEventDetected "A sensor has detected the presence of a thermal event at or near High Voltage Energy Storage Pack instance.
00b = No Thermal Event Detected
01b = Thermal Event Detected
10b = Error
11b = Not available
This parameter is for one of multiple packs ...";
CM_ SG_ 2364663806 LowestCellTempCellNum "Identifies the location of SPN 11639 (HVESP6 Lowest Cell Temperature) within SPN 11702 (HVESP6 Lowest Cell Temperature Module Number).
This parameter is for one of multiple packs in an HVESS.  If there is only one pack in the system, the HVESS ...";
CM_ SG_ 2364663806 LowestCellTempModuleNum "Identifies the location of the module containing SPN 11639 (HVESP6 Lowest Cell Temperature).
This parameter is for one of multiple packs in an HVESS.  If there is only one pack in the system, the HVESS parameters should be used. If there are ...";
CM_ SG_ 2364663806 HighestCellTempCellNum "Identifies the location of SPN 11638 (HVESP6 Highest Cell Temperature) within SPN 11700 (HVESP6 Highest Cell Temperature Module Number).
This parameter is for one of multiple packs in an HVESS.  If there is only one pack in the system, the HVESS ...";
CM_ SG_ 2364663806 HighestCellTempModuleNum "Identifies the location of the module containing SPN 11638 (HVESP6 Highest Cell Temperature).
This parameter is for one of multiple packs in an HVESS.  If there is only one pack in the system, the HVESS parameters should be used. If there are ...";
CM_ BO_ 2364663550 "High Voltage Energy Storage Pack 6 Data 8
Data set 8 (electrical data) for High Voltage Energy Storage Pack 6.";
CM_ SG_ 2364663550 AvgCellV "The average cell voltage in this High Voltage Energy Storage Pack instance.
This parameter is for one of multiple packs in an HVESS.  If there is only one pack in the system, the HVESS parameters should be used. If there are multiple packs in the ...";
CM_ SG_ 2364663550 LowestCellVCellNum "Identifies the location of SPN 11636 (HVESP6 Lowest Cell Voltage) within SPN 11697 (HVESP6 Lowest Cell Voltage Module Number).
This parameter is for one of multiple packs in an HVESS.  If there is only one pack in the system, the HVESS parameters ...";
CM_ SG_ 2364663550 LowestCellVModuleNum "Identifies the location of the module containing SPN 11636 (HVESP6 Lowest Cell Voltage).
This parameter is for one of multiple packs in an HVESS.  If there is only one pack in the system, the HVESS parameters should be used. If there are multiple ...";
CM_ SG_ 2364663550 HighestCellVCellNum "Identifies the location of SPN 11635 (HVESP6 Highest Cell Voltage) within SPN 11695 (HVESP6 Highest Cell Voltage Module Number).
This parameter is for one of multiple packs in an HVESS.  If there is only one pack in the system, the HVESS parameters ...";
CM_ SG_ 2364663550 HighestCellVModuleNum "Identifies the location of the module containing SPN 11635 (HVESP6 Highest Cell Voltage).
This parameter is for one of multiple packs in an HVESS.  If there is only one pack in the system, the HVESS parameters should be used. If there are multiple ...";
CM_ BO_ 2364663294 "High Voltage Energy Storage Pack 6 Thermal Management System Status 1
Collection of data the High Voltage Energy Storage Pack 6 Thermal Management System sends to the Hybrid Controller.";
CM_ SG_ 2364663294 TMSCoolantLvl "Indicates the coolant level in this HVES Thermal Management System (TMS).
This parameter is for one of multiple packs in an HVESS.  If there is only one pack in the system, the HVESS parameters should be used. If there are multiple packs in the ...";
CM_ SG_ 2364663294 TMSMode "Indicates the operating mode of the Thermal Management System.  The heat transfer medium may be (e.g. liquid or air).  The cooling system may be fans, liquid coolant, or a combination of mediums.  The system may include an air and/or liquid ...";
CM_ SG_ 2364663294 TMSHVILStatus "In multiple HVES configurations, this is the status of the High Voltage Interlock Loop from the viewpoint of this Thermal Management System.
00b = HVIL Closed
01b = HVIL Open
10b = Error
11b = Not Available
This parameter is for one of multiple ...";
CM_ SG_ 2364663294 TMSHtrStatus "The state of this High Voltage Energy Storage Pack heater
This parameter is for one of multiple packs in an HVESS.  If there is only one pack in the system, the HVESS parameters should be used. If there are multiple packs in the system, then both ...";
CM_ SG_ 2364663294 TMSRelHumidty "When this High Voltage Energy Storage Pack Thermal Management System is equipped with a relative humidity sensor, this is the  measured Relative Humidity.
This parameter is for one of multiple packs in an HVESS.  If there is only one pack in the ...";
CM_ SG_ 2364663294 TMSCompressorSpd "When this High Voltage Energy Storage Pack Thermal Management System is equipped with an active cooling system (e.g. air conditioner), this is the Compressor Speed.
This parameter is for one of multiple packs in an HVESS.  If there is only one pack ...";
CM_ SG_ 2364663294 TMSHVInputPwr "This is the high-voltage power consumed by this HVES Thermal Management System (TMS).
This parameter is for one of multiple packs in an HVESS.  If there is only one pack in the system, the HVESS parameters should be used. If there are multiple ...";
CM_ SG_ 2364663294 TMSSLIInputPwr "This is the low-voltage power consumed by this HVES Thermal Management System (TMS).
This parameter is for one of multiple packs in an HVESS.  If there is only one pack in the system, the HVESS parameters should be used.  If there are multiple ...";
CM_ BO_ 2364663038 "High Voltage Energy Storage Pack 6 Module Status 1
Module Status message 1 for High Voltage Energy Storage Pack 6.";
CM_ SG_ 2364663038 Module32OperationalStatus "Operational Status of Module 32 in this High Voltage Energy Storage System (or Pack 1 in systems with only one pack).  Not Operational is used when the module is initializing or not able to function (e.g. internal module level monitors have failed) ...";
CM_ SG_ 2364663038 Module31OperationalStatus "Operational Status of Module 31 in this High Voltage Energy Storage System (or Pack 1 in systems with only one pack).  Not Operational is used when the module is initializing or not able to function (e.g. internal module level monitors have failed) ...";
CM_ SG_ 2364663038 Module30OperationalStatus "Operational Status of Module 30 in this High Voltage Energy Storage System (or Pack 1 in systems with only one pack).  Not Operational is used when the module is initializing or not able to function (e.g. internal module level monitors have failed) ...";
CM_ SG_ 2364663038 Module29OperationalStatus "Operational Status of Module 29 in this High Voltage Energy Storage System (or Pack 1 in systems with only one pack).  Not Operational is used when the module is initializing or not able to function (e.g. internal module level monitors have failed) ...";
CM_ SG_ 2364663038 Module28OperationalStatus "Operational Status of Module 28 in this High Voltage Energy Storage System (or Pack 1 in systems with only one pack).  Not Operational is used when the module is initializing or not able to function (e.g. internal module level monitors have failed) ...";
CM_ SG_ 2364663038 Module27OperationalStatus "Operational Status of Module 27 in this High Voltage Energy Storage System (or Pack 1 in systems with only one pack).  Not Operational is used when the module is initializing or not able to function (e.g. internal module level monitors have failed) ...";
CM_ SG_ 2364663038 Module26OperationalStatus "Operational Status of Module 26 in this High Voltage Energy Storage System (or Pack 1 in systems with only one pack).  Not Operational is used when the module is initializing or not able to function (e.g. internal module level monitors have failed) ...";
CM_ SG_ 2364663038 Module25OperationalStatus "Operational Status of Module 25 in this High Voltage Energy Storage System (or Pack 1 in systems with only one pack).  Not Operational is used when the module is initializing or not able to function (e.g. internal module level monitors have failed) ...";
CM_ SG_ 2364663038 Module24OperationalStatus "Operational Status of Module 24 in this High Voltage Energy Storage System (or Pack 1 in systems with only one pack).  Not Operational is used when the module is initializing or not able to function (e.g. internal module level monitors have failed) ...";
CM_ SG_ 2364663038 Module23OperationalStatus "Operational Status of Module 23 in this High Voltage Energy Storage System (or Pack 1 in systems with only one pack).  Not Operational is used when the module is initializing or not able to function (e.g. internal module level monitors have failed) ...";
CM_ SG_ 2364663038 Module22OperationalStatus "Operational Status of Module 22 in this High Voltage Energy Storage System (or Pack 1 in systems with only one pack).  Not Operational is used when the module is initializing or not able to function (e.g. internal module level monitors have failed) ...";
CM_ SG_ 2364663038 Module21OperationalStatus "Operational Status of Module 21 in this High Voltage Energy Storage System (or Pack 1 in systems with only one pack).  Not Operational is used when the module is initializing or not able to function (e.g. internal module level monitors have failed) ...";
CM_ SG_ 2364663038 Module20OperationalStatus "Operational Status of Module 20 in this High Voltage Energy Storage System (or Pack 1 in systems with only one pack).  Not Operational is used when the module is initializing or not able to function (e.g. internal module level monitors have failed) ...";
CM_ SG_ 2364663038 Module19OperationalStatus "Operational Status of Module 19 in this High Voltage Energy Storage System (or Pack 1 in systems with only one pack).  Not Operational is used when the module is initializing or not able to function (e.g. internal module level monitors have failed) ...";
CM_ SG_ 2364663038 Module18OperationalStatus "Operational Status of Module 18 in this High Voltage Energy Storage System (or Pack 1 in systems with only one pack).  Not Operational is used when the module is initializing or not able to function (e.g. internal module level monitors have failed) ...";
CM_ SG_ 2364663038 Module17OperationalStatus "Operational Status of Module 17 in this High Voltage Energy Storage System (or Pack 1 in systems with only one pack).  Not Operational is used when the module is initializing or not able to function (e.g. internal module level monitors have failed) ...";
CM_ SG_ 2364663038 Module16OperationalStatus "Operational Status of Module 16 in this High Voltage Energy Storage Pack Instance.  Not Operational is used when the module is initializing or not able to function (e.g. internal module level monitors have failed).  Operational indicates that the ...";
CM_ SG_ 2364663038 Module15OperationalStatus "Operational Status of Module 15 in this High Voltage Energy Storage Pack Instance.  Not Operational is used when the module is initializing or not able to function (e.g. internal module level monitors have failed).  Operational indicates that the ...";
CM_ SG_ 2364663038 Module14OperationalStatus "Operational Status of Module 14 in this High Voltage Energy Storage Pack Instance.  Not Operational is used when the module is initializing or not able to function (e.g. internal module level monitors have failed).  Operational indicates that the ...";
CM_ SG_ 2364663038 Module13OperationalStatus "Operational Status of Module 13 in this High Voltage Energy Storage Pack Instance.  Not Operational is used when the module is initializing or not able to function (e.g. internal module level monitors have failed).  Operational indicates that the ...";
CM_ SG_ 2364663038 Module12OperationalStatus "Operational Status of Module 12 in this High Voltage Energy Storage Pack Instance.  Not Operational is used when the module is initializing or not able to function (e.g. internal module level monitors have failed).  Operational indicates that the ...";
CM_ SG_ 2364663038 Module11OperationalStatus "Operational Status of Module 11 in this High Voltage Energy Storage Pack Instance.  Not Operational is used when the module is initializing or not able to function (e.g. internal module level monitors have failed).  Operational indicates that the ...";
CM_ SG_ 2364663038 Module10OperationalStatus "Operational Status of Module 10 in this High Voltage Energy Storage Pack Instance.  Not Operational is used when the module is initializing or not able to function (e.g. internal module level monitors have failed).  Operational indicates that the ...";
CM_ SG_ 2364663038 Module9OperationalStatus "Operational Status of Module 9 in this High Voltage Energy Storage Pack Instance.  Not Operational is used when the module is initializing or not able to function (e.g. internal module level monitors have failed).  Operational indicates that the ...";
CM_ SG_ 2364663038 Module8OperationalStatus "Operational Status of Module 8 in this High Voltage Energy Storage Pack Instance.  Not Operational is used when the module is initializing or not able to function (e.g. internal module level monitors have failed).  Operational indicates that the ...";
CM_ SG_ 2364663038 Module7OperationalStatus "Operational Status of Module 7 in this High Voltage Energy Storage Pack Instance.  Not Operational is used when the module is initializing or not able to function (e.g. internal module level monitors have failed).  Operational indicates that the ...";
CM_ SG_ 2364663038 Module6OperationalStatus "Operational Status of Module 6 in this High Voltage Energy Storage Pack Instance.  Not Operational is used when the module is initializing or not able to function (e.g. internal module level monitors have failed).  Operational indicates that the ...";
CM_ SG_ 2364663038 Module5OperationalStatus "Operational Status of Module 5 in this High Voltage Energy Storage Pack Instance.  Not Operational is used when the module is initializing or not able to function (e.g. internal module level monitors have failed).  Operational indicates that the ...";
CM_ SG_ 2364663038 Module4OperationalStatus "Operational Status of Module 4 in this High Voltage Energy Storage Pack Instance.  Not Operational is used when the module is initializing or not able to function (e.g. internal module level monitors have failed).  Operational indicates that the ...";
CM_ SG_ 2364663038 Module3OperationalStatus "Operational Status of Module 3 in this High Voltage Energy Storage Pack Instance.  Not Operational is used when the module is initializing or not able to function (e.g. internal module level monitors have failed).  Operational indicates that the ...";
CM_ SG_ 2364663038 Module2OperationalStatus "Operational Status of Module 2 in this High Voltage Energy Storage Pack Instance.  Not Operational is used when the module is initializing or not able to function (e.g. internal module level monitors have failed).  Operational indicates that the ...";
CM_ SG_ 2364663038 Module1OperationalStatus "Operational Status of Module 1 in this High Voltage Energy Storage Pack Instance.  Not Operational is used when the module is initializing or not able to function (e.g. internal module level monitors have failed).  Operational indicates that the ...";
CM_ BO_ 2364662782 "High Voltage Energy Storage Pack 6 Data 7
Data set 7 (electrical) for High Voltage Energy Storage Pack 6.";
CM_ SG_ 2364662782 MaxChargeVLmt "The maximum voltage level not to be exceeded while charging this High Voltage Energy Storage Pack instance.  If this parameter is not supported, the maximum charge voltage should be limited to SPN 11714 (HVESP6 Recommended Maximum Operating ...";
CM_ SG_ 2364662782 ChargeEnergyCapacity "The amount of unused electrical energy storage available to be filled by charging this High Voltage Energy Storage Pack instance, i.e. “how much empty space is remaining in the tank”.  See SPN 11643 (HVESP6 Charge Capacity) for Ampere-hours (Ah).
 ...";
CM_ SG_ 2364662782 DisEnergyCapacity "The amount of stored electrical energy in this High Voltage Energy Storage Pack instance that is available for use by the hybrid system, i.e. “how full is the tank”.  See SPN 11642 (HVESP6 Discharge Capacity) for Ampere-hours (Ah).
This parameter ...";
CM_ BO_ 2364662526 "High Voltage Energy Storage Pack 6 Status 1
Status data set 1 for High Voltage Energy Storage Pack 6.";
CM_ SG_ 2364662526 Status1CRC "The CRC is defined as follows:
• Length: 8 bits
• Polynomial: x^8+x^5+x^3+x^2+x+1
• Initial Value: FFh
• Input Data Reflection: Not reflected
• Result Data Reflection: Not reflected
• XOR value: FFh
SAE makes no claim of the functional safety ...";
CM_ SG_ 2364662526 Status1Counter "The message counter is used to detect situations where the transmitting ECU malfunction repeats the same frame all the time. The receiver of the information may use the counter parameter to detect this situation. The transmitting device will ...";
CM_ SG_ 2364662526 OperationalStatus "Provides feedback on where this High Voltage Energy Storage Pack instance is in its operating spectrum, and includes feedback in response to the Operation Consent [i.e. SPN 11615 (HVESP6 Operation Consent)] and Power Down Command [i.e. SPN 11610 ...";
CM_ SG_ 2364662526 HVBusConnectionStatus "This parameter provides high level feedback on this High Voltage Energy Storage Pack instance high voltage bus connection.  For specific contactor information, see SPN 11655 (HVESP6 High-Voltage Bus (Positive) Contactor State), SPN 11656 (HVESP6 ...";
CM_ SG_ 2364662526 InternalChargerStatus "Indicates that the charger in this HVES instance is on.  External chargers may use the External Energy Source Connection Status (SPN 7898) and related SPs.
This parameter is for one of multiple packs in an HVESS. If there is only one pack in the ...";
CM_ SG_ 2364662526 CellBalancingActive "Indicates whether or not the cells in this High Voltage Energy Storage Pack instance are currently being balanced.
This parameter is for one of multiple packs in an HVESS.  If there is only one pack in the system, the HVESS parameters should be ...";
CM_ SG_ 2364662526 CellBalanceStatus "Indicates whether or not the cells in this High Voltage Energy Storage Pack instance are balanced.
This parameter is for one of multiple packs in an HVESS.  If there is only one pack in the system, the HVESS parameters should be used. If there are ...";
CM_ SG_ 2364662526 StOfChargeStatus "Status of this High Voltage Energy Storage Pack instance State of Charge (SOC).  Note:  A given HVES controller may not support all of the states.
This parameter is for one of multiple packs in an HVESS.  If there is only one pack in the system, ...";
CM_ SG_ 2364662526 InertiaSwStatus "Switch indicating that an impact has been sensed by this High Voltage Energy Storage Pack instance. The impact indication may require action by another controller, or by this HVES instance itself.  For example, a controller may elect to take this ...";
CM_ SG_ 2364662526 HVILStatus "Status of the High Voltage Interlock Loop from the viewpoint of this High Voltage Energy Storage Pack instance.
This parameter is for one of multiple packs in an HVESS. If there is only one pack in the system, the HVESS parameters should be used ...";
CM_ SG_ 2364662526 HVBusPassiveIsolTestStatus "Status of the high-voltage bus electrical passive isolation test as performed by this High Voltage Energy Storage Pack instance.
This parameter is for one of multiple packs in an HVESS. If there is only one pack in the system, the HVESS parameters ...";
CM_ SG_ 2364662526 HVBusActiveIsolTestStatus "Status of the high-voltage bus electrical active isolation test as performed by this High Voltage Energy Storage Pack instance.
This parameter is for one of multiple packs in an HVESS. If there is only one pack in the system, the HVESS parameters ...";
CM_ SG_ 2364662526 CenterOfPackContactorSt "Position of the center high-voltage contactor.  When this contactor is closed, the positive half of this High Voltage Energy Storage Pack instance is connected to the negative half.  If a system controls the positive, negative, and center contactors ...";
CM_ SG_ 2364662526 HVBusPreChargeRelaySt "Position of the high-voltage bus contactor pre-charge relay.  When this relay is closed, this High Voltage Energy Storage Pack instance is bringing the high-voltage bus up to its operating level.
This parameter is for one of multiple packs in an ...";
CM_ SG_ 2364662526 HVBusDisconnectForewarning "Indicates that this High Voltage Energy Storage Pack instance is about to disconnect from the high voltage bus due to unacceptable conditions.
This parameter is for one of multiple packs in an HVESS. If there is only one pack in the system, the ...";
CM_ SG_ 2364662526 HVBusContactorSt11656 "Position of this High Voltage Energy Storage Pack instance negative side bus contactor.  When this contactor is closed, the negative side of this HVES instance is connected to the negative side of the high-voltage bus.  If a system controls the ...";
CM_ SG_ 2364662526 HVBusContactorSt "Position of this High Voltage Energy Storage Pack instance positive side bus contactor.  When this contactor is closed, the positive side of this HVES instance is connected to the positive side of the high-voltage bus.  In systems where all ...";
CM_ BO_ 2364662270 "High Voltage Energy Storage Pack 6 Data 6
Data set 6 (external or interface data) for High Voltage Energy Storage Pack 6.";
CM_ SG_ 2364662270 Temp "The temperature of this High Voltage Energy Storage Pack instance. The value may be determined from a unique sensor specifically for this purpose, or by aggregating various temperature sensor readings within the pack.
This parameter is for one of ...";
CM_ SG_ 2364662270 ETemp "The temperature of the electronics or control modules in this High Voltage Energy Storage Pack instance.  If there are multiple temperature sensors then this parameter would be set to the maximum sensor reading.
This parameter is for one of ...";
CM_ SG_ 2364662270 OutCoolantTemp "The temperature of liquid coolant as it exits this High Voltage Energy Storage Pack instance.
This parameter is for one of multiple packs in an HVESS.  If there is only one pack in the system, the HVESS parameters should be used. If there are ...";
CM_ SG_ 2364662270 InCoolantTemp "The temperature of liquid coolant as it enters this High Voltage Energy Storage Pack instance.
This parameter is for one of multiple packs in an HVESS.  If there is only one pack in the system, the HVESS parameters should be used. If there are ...";
CM_ SG_ 2364662270 IgntV "The voltage level at the ignition input of this High Voltage Energy Storage Pack controller.
This parameter is for one of multiple packs in an HVESS.  If there is only one pack in the system, the HVESS parameters should be used.  If there are ...";
CM_ SG_ 2364662270 BusV "The voltage level of the high voltage bus, as measured by this High Voltage Energy Storage Pack instance on the bus side (not the battery side) of its contactors.
This parameter is for one of multiple packs in an HVESS.  If there is only one pack ...";
CM_ BO_ 2364662014 "High Voltage Energy Storage Pack 6 Data 5
Data set 5 (electrical data) for High Voltage Energy Storage Pack 6.";
CM_ SG_ 2364662014 HighestCellStOfCharge "Indicates the state of charge of the highest-charged cell in this High Voltage Energy Storage Pack instance.  0% means no charge remaining, 100% means the cell is fully charged.  If a single state of charge value covers more than one cell, the value ...";
CM_ SG_ 2364662014 LowestCellStOfCharge "Indicates the state of charge of the lowest-charged cell in this High Voltage Energy Storage Pack instance.  0% means no charge remaining, 100% means the cell is fully charged.   If a single state of charge value covers more than one cell, the value ...";
CM_ SG_ 2364662014 ChargeCurLmt "The maximum instantaneous current flow limit into this High Voltage Energy Storage Pack instance. This parameter is defined from the high voltage energy storage pack's point of view and should reflect the instantaneous capability of the pack.  The ...";
CM_ SG_ 2364662014 DisCurLmt "The maximum instantaneous current flow limit out of this High Voltage Energy Storage Pack instance. This parameter is defined from the high voltage energy storage pack's point of view and should reflect the instantaneous capability of the pack.  The ...";
CM_ BO_ 2364661758 "High Voltage Energy Storage Pack 6 Data 4
Data set 4 (electrical data) for High Voltage Energy Storage Pack 6.";
CM_ SG_ 2364661758 CellBalancingCount "The number of cells that are currently being balanced in this High Voltage Energy Storage Pack instance.
This parameter is for one of multiple packs in an HVESS.  If there is only one pack in the system, the HVESS parameters should be used.  If ...";
CM_ SG_ 2364661758 ChargeCapacity "The amount of unused electrical charge storage in this High Voltage Energy Storage Pack instance that is available to be filled by charging, i.e. “how much empty space is remaining in the tank”.  See SPN 11671 (HVESP6 Charge Energy Capacity) for ...";
CM_ SG_ 2364661758 DisCapacity "The amount of stored electrical charge in this High Voltage Energy Storage Pack instance that is available for use by the hybrid system, i.e. “how full is the tank”.  See SPN 11670 (HVESP6 Discharge Energy Capacity) for kilowatt-hours (kWh).
This ...";
CM_ BO_ 2364661502 "High Voltage Energy Storage Pack 6 Data 3
Data set 3 (thermal data) for High Voltage Energy Storage Pack 6.";
CM_ SG_ 2364661502 CellTempDiffStatus "Indicates whether or not the differential between the highest and lowest cell temperatures are within acceptable limits per this High Voltage Energy Storage Pack instance.  The actual temperature differential can be calculated by subtracting SPN ...";
CM_ SG_ 2364661502 AvgCellTemp "The average temperature level of all cells in this High Voltage Energy Storage Pack instance.
This parameter is for one of multiple packs in an HVESS.  If there is only one pack in the system, the HVESS parameters should be used.  If there are ...";
CM_ SG_ 2364661502 LowestCellTemp "The lowest temperature level reported by any cell in this High Voltage Energy Storage Pack instance.  If a single temperature sensor covers more than one cell, the value in this parameter is for the smallest group of cells measured.  See SPN 11702 ...";
CM_ SG_ 2364661502 HighestCellTemp "The highest temperature level reported by any cell in this High Voltage Energy Storage Pack instance.  If a single temperature sensor covers more than one cell, the value in this parameter is for the smallest group of cells measured.   See SPN 11700 ...";
CM_ BO_ 2364661246 "High Voltage Energy Storage Pack 6 Data 2
Data set 2 (electrical data) for High Voltage Energy Storage Pack 6.";
CM_ SG_ 2364661246 CellVDiffStatus "Indicates whether or not the differential between the highest and lowest cell voltages are within acceptable limits, according to this High Voltage Energy Storage Pack instance. The actual voltage differential can be calculated by subtracting SPN ...";
CM_ SG_ 2364661246 LowestCellV "The lowest voltage level reported by any cell in this High Voltage Energy Storage Pack instance. If a single voltage sensor covers more than one cell, the value in this parameter is for the smallest group of cells measured.  See SPN 11697 (HVESP6 ...";
CM_ SG_ 2364661246 HighestCellV "The highest voltage level reported by any cell in this High Voltage Energy Storage Pack instance. If a single voltage sensor covers more than one cell, the value in this parameter is for the smallest group of cells measured. See SPN 11695 (HVESP6 ...";
CM_ SG_ 2364661246 FastUpdateStOfCharge "Indicates this High Voltage Energy Storage Pack instance state of charge.  0% means no charge remaining, 100% means the system is fully charged in terms of physical limits of this energy storage pack instance.  Acceptable state of charge upper and ...";
CM_ BO_ 2364660990 "High Voltage Energy Storage Pack 6 Data 1
Data set 1 (electrical data) for High Voltage Energy Storage Pack 6.";
CM_ SG_ 2364660990 Cur "The current in or out of this High Voltage Energy Storage Pack instance. This parameter should be synchronized with SPN 11632 (HVESP6 Voltage Level) such that a realized power value can be calculated.  This parameter is defined from the high voltage ...";
CM_ SG_ 2364660990 Lvl "The voltage level of this High Voltage Energy Storage Pack instance. This parameter should be synchronized with SPN 11633 (HVESP6 Current) such that a realized power value can be calculated.  If the HVES component physically contains the contactors ...";
CM_ SG_ 2364660990 AvailableChargePwr "The rate at which this High Voltage Energy Storage Pack instance can currently receive energy from a regenerative or recharging system.
This parameter is for one of multiple packs in an HVESS.  If there is only one pack in the system, the HVESS ...";
CM_ SG_ 2364660990 AvailableDisPwr "The rate at which this High Voltage Energy Storage Pack instance can currently provide energy for propulsion or other uses.
This parameter is for one of multiple packs in an HVESS.  If there is only one pack in the system, the HVESS parameters ...";
CM_ BO_ 2364660734 "High Voltage Energy Storage Pack 6 Status 2
Status data set 2 for High Voltage Energy Storage Pack 6.";
CM_ SG_ 2364660734 ChargePLDueToAnUndefinedCause "Indicates whether or not charge power of this HVES instance is being limited due to an undefined cause.
This parameter is for one of multiple packs in an HVESS.  If there is only one pack in the system, the HVESS parameters should be used. If there ...";
CM_ SG_ 2364660734 ChargePLDueToBatCur "Indicates whether or not charge power of this HVES instance is being limited due to battery current.
This parameter is for one of multiple packs in an HVESS.  If there is only one pack in the system, the HVESS parameters should be used. If there ...";
CM_ SG_ 2364660734 ChargePLDueToBatOrCellV "Indicates whether or not charge power of this HVES instance is being limited due to a battery or cell voltage level.
This parameter is for one of multiple packs in an HVESS.  If there is only one pack in the system, the HVESS parameters should be ...";
CM_ SG_ 2364660734 ChargePLDueToBatDiagCondition "Indicates whether or not charge power of this HVES instance is being limited due to a battery diagnostic condition.
This parameter is for one of multiple packs in an HVESS.  If there is only one pack in the system, the HVESS parameters should be ...";
CM_ SG_ 2364660734 ChargePLDueToBatTemp "Indicates whether or not charge power of this HVES instance is being limited due to battery temperature.
This parameter is for one of multiple packs in an HVESS.  If there is only one pack in the system, the HVESS parameters should be used. If ...";
CM_ SG_ 2364660734 ChargePLDueToStOfCharge "Indicates whether or not charge power of this HVES instance is being limited due to state of charge.
This parameter is for one of multiple packs in an HVESS.  If there is only one pack in the system, the HVESS parameters should be used. If there ...";
CM_ SG_ 2364660734 DisPLDueToAnUndefinedCause "Indicates whether or not discharge power of this HVES instance is being limited due to an undefined cause.
This parameter is for one of multiple packs in an HVESS.  If there is only one pack in the system, the HVESS parameters should be used. If ...";
CM_ SG_ 2364660734 DisPLDueToBatCur "Indicates whether or not discharge power of this HVES instance is being limited due to battery current.
This parameter is for one of multiple packs in an HVESS.  If there is only one pack in the system, the HVESS parameters should be used. If there ...";
CM_ SG_ 2364660734 DisPLDueToBatOrCellV "Indicates whether or not discharge power of this HVES instance is being limited due to a battery or cell voltage level.
This parameter is for one of multiple packs in an HVESS.  If there is only one pack in the system, the HVESS parameters should ...";
CM_ SG_ 2364660734 DisPLDueToBatDiagCondition "Indicates whether or not discharge power of this HVES instance is being limited due to a battery diagnostic condition.
This parameter is for one of multiple packs in an HVESS.  If there is only one pack in the system, the HVESS parameters should be ...";
CM_ SG_ 2364660734 DisPLDueToBatTemp "Indicates whether or not discharge power of this HVES instance is being limited due to battery temperature.
This parameter is for one of multiple packs in an HVESS.  If there is only one pack in the system, the HVESS parameters should be used. If ...";
CM_ SG_ 2364660734 DisPLDueToStOfCharge "Indicates whether or not discharge power of this HVES instance is being limited due to state of charge.
This parameter is for one of multiple packs in an HVESS.  If there is only one pack in the system, the HVESS parameters should be used. If there ...";
CM_ BO_ 2364660478 "High Voltage Energy Storage Pack 5 Data 11
Data set 11 (electrical data) for High Voltage Energy Storage Pack 5.";
CM_ SG_ 2364660478 ActualChargeRate "This signal represents the actual present charge rate of this High Voltage Energy Storage Pack instance.
This parameter is for one of multiple packs in an HVESS. If there is only one pack in the system, the HVESS parameters should be used. If there ...";
CM_ SG_ 2364660478 LvlNegToChassisGroundV "Voltage difference between the most negative terminal of the HVES battery and chassis measured at the battery side of any HVES contained output contactor.  This voltage may be used for system level monitoring of battery shorts to chassis within the ...";
CM_ SG_ 2364660478 BusVNegToChassisGroundV "Voltage difference between the most negative terminal of the HVES battery and chassis measured on the hybrid system bus side (not the battery side) of any HVES contained output contactor.  This voltage may be used for system level monitoring of ...";
CM_ BO_ 2364660222 "High Voltage Energy Storage Pack 5 Data 10
Data set 10 (electrical) for High Voltage Energy Storage Pack 5.";
CM_ SG_ 2364660222 HVBusPassiveIsolTestResults "The isolation resistance expressed in Ohms per Volt that resulted from the High-Voltage Bus Passive Isolation Test.
See SPN 11545 (HVESP5 High-Voltage Bus Passive Isolation Test Status) for test status and SPN 11496 (HVESP5 High-Voltage Bus Passive ...";
CM_ SG_ 2364660222 HVBusActiveIsolTestResults "The isolation resistance expressed in Ohms per Volt that resulted from the High-Voltage Bus Active Isolation Test.
See SPN 11544 (HVESP5 High-Voltage Bus Active Isolation Test Status) for test status and SPN 11495 (HVESP5 High-Voltage Bus Active ...";
CM_ SG_ 2364660222 LowestCellStOfChargeCellNum "Identifies the location of SPN 11531 (HVESP5 Lowest Cell State of Charge) within SPN 11590 (HVESP5 Lowest Cell State of Charge Module Number).
This parameter is for one of multiple packs in an HVESS.  If there is only one pack in the system, the ...";
CM_ SG_ 2364660222 LowestCellStOfChargeModuleNum "Identifies the location of the module containing SPN 11531 (HVESP5 Lowest Cell State of Charge).
This parameter is for one of multiple packs in an HVESS.  If there is only one pack in the system, the HVESS parameters should be used. If there are ...";
CM_ SG_ 2364660222 HighestCellStOfChargeCellNum "Identifies the location of SPN 11532 (HVESP5 Highest Cell State of Charge) within SPN 11588 (HVESP5 Highest Cell State of Charge Module Number).
This parameter is for one of multiple packs in an HVESS.  If there is only one pack in the system, the ...";
CM_ SG_ 2364660222 HighestCellStOfChargeModuleNum "Identifies the location of the module containing SPN 11532 (HVESP5 Highest Cell State of Charge).
This parameter is for one of multiple packs in an HVESS.  If there is only one pack in the system, the HVESS parameters should be used. If there are ...";
CM_ BO_ 2364659966 "High Voltage Energy Storage Pack 5 Data 9
Data set 9 (thermal) for High Voltage Energy Storage Pack 5.";
CM_ SG_ 2364659966 Data9CRC "The CRC is defined as follows:
• Length: 8 bits
• Polynomial: x^8+x^5+x^3+x^2+x+1
• Initial Value: FFh
• Input Data Reflection: Not reflected
• Result Data Reflection: Not reflected
• XOR value: FFh
SAE makes no claim of the functional safety ...";
CM_ SG_ 2364659966 Data9Counter "The message counter is used to detect situations where the transmitting ECU malfunction repeats the same frame all the time. The receiver of the information may use the counter parameter to detect this situation. The transmitting device will ...";
CM_ SG_ 2364659966 Data9EmbeddedIntegritySupport "Indicates SPN 22988 (HVESP5 Data 9 CRC) and SPN 22987 (HVESP5 Data 9 Counter) are supported by the sender.
00b = Embedded CRC and Counter are supported by the sender
01b = Protection is supported using J1939-76 SHM
10b = Reserved
11b = CRC and ...";
CM_ SG_ 2364659966 HVESS5ThermalEventDetected "A sensor has detected the presence of a thermal event at or near High Voltage Energy Storage Pack instance.
00b = No Thermal Event Detected
01b = Thermal Event Detected
10b = Error
11b = Not available
This parameter is for one of multiple packs ...";
CM_ SG_ 2364659966 LowestCellTempCellNum "Identifies the location of SPN 11523 (HVESP5 Lowest Cell Temperature) within SPN 11586 (HVESP5 Lowest Cell Temperature Module Number).
This parameter is for one of multiple packs in an HVESS.  If there is only one pack in the system, the HVESS ...";
CM_ SG_ 2364659966 LowestCellTempModuleNum "Identifies the location of the module containing SPN 11523 (HVESP5 Lowest Cell Temperature).
This parameter is for one of multiple packs in an HVESS.  If there is only one pack in the system, the HVESS parameters should be used. If there are ...";
CM_ SG_ 2364659966 HighestCellTempCellNum "Identifies the location of SPN 11522 (HVESP5 Highest Cell Temperature) within SPN 11584 (HVESP5 Highest Cell Temperature Module Number).
This parameter is for one of multiple packs in an HVESS.  If there is only one pack in the system, the HVESS ...";
CM_ SG_ 2364659966 HighestCellTempModuleNum "Identifies the location of the module containing SPN 11522 (HVESP5 Highest Cell Temperature).
This parameter is for one of multiple packs in an HVESS.  If there is only one pack in the system, the HVESS parameters should be used. If there are ...";
CM_ BO_ 2364659710 "High Voltage Energy Storage Pack 5 Data 8
Data set 8 (electrical data) for High Voltage Energy Storage Pack 5.";
CM_ SG_ 2364659710 AvgCellV "The average cell voltage in this High Voltage Energy Storage Pack instance.
This parameter is for one of multiple packs in an HVESS.  If there is only one pack in the system, the HVESS parameters should be used. If there are multiple packs in the ...";
CM_ SG_ 2364659710 LowestCellVCellNum "Identifies the location of SPN 11520 (HVESP5 Lowest Cell Voltage) within SPN 11581 (HVESP5 Lowest Cell Voltage Module Number).
This parameter is for one of multiple packs in an HVESS.  If there is only one pack in the system, the HVESS parameters ...";
CM_ SG_ 2364659710 LowestCellVModuleNum "Identifies the location of the module containing SPN 11520 (HVESP5 Lowest Cell Voltage).
This parameter is for one of multiple packs in an HVESS.  If there is only one pack in the system, the HVESS parameters should be used. If there are multiple ...";
CM_ SG_ 2364659710 HighestCellVCellNum "Identifies the location of SPN 11519 (HVESP5 Highest Cell Voltage) within SPN 11579 (HVESP5 Highest Cell Voltage Module Number).
This parameter is for one of multiple packs in an HVESS.  If there is only one pack in the system, the HVESS parameters ...";
CM_ SG_ 2364659710 HighestCellVModuleNum "Identifies the location of the module containing SPN 11519 (HVESP5 Highest Cell Voltage).
This parameter is for one of multiple packs in an HVESS.  If there is only one pack in the system, the HVESS parameters should be used. If there are multiple ...";
CM_ BO_ 2364659454 "High Voltage Energy Storage Pack 5 Thermal Management System Status 1
Collection of data the High Voltage Energy Storage Pack 5 Thermal Management System sends to the Hybrid Controller.";
CM_ SG_ 2364659454 TMSCoolantLvl "Indicates the coolant level in this HVES Thermal Management System (TMS).
This parameter is for one of multiple packs in an HVESS.  If there is only one pack in the system, the HVESS parameters should be used. If there are multiple packs in the ...";
CM_ SG_ 2364659454 TMSMode "Indicates the operating mode of the Thermal Management System.  The heat transfer medium may be (e.g. liquid or air).  The cooling system may be fans, liquid coolant, or a combination of mediums.  The system may include an air and/or liquid ...";
CM_ SG_ 2364659454 TMSHVILStatus "In multiple HVES configurations, this is the status of the High Voltage Interlock Loop from the viewpoint of this Thermal Management System.
00b = HVIL Closed
01b = HVIL Open
10b = Error
11b = Not Available
This parameter is for one of multiple ...";
CM_ SG_ 2364659454 TMSHtrStatus "The state of this High Voltage Energy Storage Pack heater
This parameter is for one of multiple packs in an HVESS.  If there is only one pack in the system, the HVESS parameters should be used. If there are multiple packs in the system, then both ...";
CM_ SG_ 2364659454 TMSRelHumidty "When this High Voltage Energy Storage Pack Thermal Management System is equipped with a relative humidity sensor, this is the  measured Relative Humidity.
This parameter is for one of multiple packs in an HVESS.  If there is only one pack in the ...";
CM_ SG_ 2364659454 TMSCompressorSpd "When this High Voltage Energy Storage Pack Thermal Management System is equipped with an active cooling system (e.g. air conditioner), this is the Compressor Speed.
This parameter is for one of multiple packs in an HVESS.  If there is only one pack ...";
CM_ SG_ 2364659454 TMSHVInputPwr "This is the high-voltage power consumed by this HVES Thermal Management System (TMS).
This parameter is for one of multiple packs in an HVESS.  If there is only one pack in the system, the HVESS parameters should be used. If there are multiple ...";
CM_ SG_ 2364659454 TMSSLIInputPwr "This is the low-voltage power consumed by this HVES Thermal Management System (TMS).
This parameter is for one of multiple packs in an HVESS.  If there is only one pack in the system, the HVESS parameters should be used.  If there are multiple ...";
CM_ BO_ 2364659198 "High Voltage Energy Storage Pack 5 Module Status 1
Module Status message 1 for High Voltage Energy Storage Pack 5.";
CM_ SG_ 2364659198 Module32OperationalStatus "Operational Status of Module 32 in this High Voltage Energy Storage System (or Pack 1 in systems with only one pack).  Not Operational is used when the module is initializing or not able to function (e.g. internal module level monitors have failed) ...";
CM_ SG_ 2364659198 Module31OperationalStatus "Operational Status of Module 31 in this High Voltage Energy Storage System (or Pack 1 in systems with only one pack).  Not Operational is used when the module is initializing or not able to function (e.g. internal module level monitors have failed) ...";
CM_ SG_ 2364659198 Module30OperationalStatus "Operational Status of Module 30 in this High Voltage Energy Storage System (or Pack 1 in systems with only one pack).  Not Operational is used when the module is initializing or not able to function (e.g. internal module level monitors have failed) ...";
CM_ SG_ 2364659198 Module29OperationalStatus "Operational Status of Module 29 in this High Voltage Energy Storage System (or Pack 1 in systems with only one pack).  Not Operational is used when the module is initializing or not able to function (e.g. internal module level monitors have failed) ...";
CM_ SG_ 2364659198 Module28OperationalStatus "Operational Status of Module 28 in this High Voltage Energy Storage System (or Pack 1 in systems with only one pack).  Not Operational is used when the module is initializing or not able to function (e.g. internal module level monitors have failed) ...";
CM_ SG_ 2364659198 Module27OperationalStatus "Operational Status of Module 27 in this High Voltage Energy Storage System (or Pack 1 in systems with only one pack).  Not Operational is used when the module is initializing or not able to function (e.g. internal module level monitors have failed) ...";
CM_ SG_ 2364659198 Module26OperationalStatus "Operational Status of Module 26 in this High Voltage Energy Storage System (or Pack 1 in systems with only one pack).  Not Operational is used when the module is initializing or not able to function (e.g. internal module level monitors have failed) ...";
CM_ SG_ 2364659198 Module25OperationalStatus "Operational Status of Module 25 in this High Voltage Energy Storage System (or Pack 1 in systems with only one pack).  Not Operational is used when the module is initializing or not able to function (e.g. internal module level monitors have failed) ...";
CM_ SG_ 2364659198 Module24OperationalStatus "Operational Status of Module 24 in this High Voltage Energy Storage System (or Pack 1 in systems with only one pack).  Not Operational is used when the module is initializing or not able to function (e.g. internal module level monitors have failed) ...";
CM_ SG_ 2364659198 Module23OperationalStatus "Operational Status of Module 23 in this High Voltage Energy Storage System (or Pack 1 in systems with only one pack).  Not Operational is used when the module is initializing or not able to function (e.g. internal module level monitors have failed) ...";
CM_ SG_ 2364659198 Module22OperationalStatus "Operational Status of Module 22 in this High Voltage Energy Storage System (or Pack 1 in systems with only one pack).  Not Operational is used when the module is initializing or not able to function (e.g. internal module level monitors have failed) ...";
CM_ SG_ 2364659198 Module21OperationalStatus "Operational Status of Module 21 in this High Voltage Energy Storage System (or Pack 1 in systems with only one pack).  Not Operational is used when the module is initializing or not able to function (e.g. internal module level monitors have failed) ...";
CM_ SG_ 2364659198 Module20OperationalStatus "Operational Status of Module 20 in this High Voltage Energy Storage System (or Pack 1 in systems with only one pack).  Not Operational is used when the module is initializing or not able to function (e.g. internal module level monitors have failed) ...";
CM_ SG_ 2364659198 Module19OperationalStatus "Operational Status of Module 19 in this High Voltage Energy Storage System (or Pack 1 in systems with only one pack).  Not Operational is used when the module is initializing or not able to function (e.g. internal module level monitors have failed) ...";
CM_ SG_ 2364659198 Module18OperationalStatus "Operational Status of Module 18 in this High Voltage Energy Storage System (or Pack 1 in systems with only one pack).  Not Operational is used when the module is initializing or not able to function (e.g. internal module level monitors have failed) ...";
CM_ SG_ 2364659198 Module17OperationalStatus "Operational Status of Module 17 in this High Voltage Energy Storage System (or Pack 1 in systems with only one pack).  Not Operational is used when the module is initializing or not able to function (e.g. internal module level monitors have failed) ...";
CM_ SG_ 2364659198 Module16OperationalStatus "Operational Status of Module 16 in this High Voltage Energy Storage Pack Instance.  Not Operational is used when the module is initializing or not able to function (e.g. internal module level monitors have failed).  Operational indicates that the ...";
CM_ SG_ 2364659198 Module15OperationalStatus "Operational Status of Module 15 in this High Voltage Energy Storage Pack Instance.  Not Operational is used when the module is initializing or not able to function (e.g. internal module level monitors have failed).  Operational indicates that the ...";
CM_ SG_ 2364659198 Module14OperationalStatus "Operational Status of Module 14 in this High Voltage Energy Storage Pack Instance.  Not Operational is used when the module is initializing or not able to function (e.g. internal module level monitors have failed).  Operational indicates that the ...";
CM_ SG_ 2364659198 Module13OperationalStatus "Operational Status of Module 13 in this High Voltage Energy Storage Pack Instance.  Not Operational is used when the module is initializing or not able to function (e.g. internal module level monitors have failed).  Operational indicates that the ...";
CM_ SG_ 2364659198 Module12OperationalStatus "Operational Status of Module 12 in this High Voltage Energy Storage Pack Instance.  Not Operational is used when the module is initializing or not able to function (e.g. internal module level monitors have failed).  Operational indicates that the ...";
CM_ SG_ 2364659198 Module11OperationalStatus "Operational Status of Module 11 in this High Voltage Energy Storage Pack Instance.  Not Operational is used when the module is initializing or not able to function (e.g. internal module level monitors have failed).  Operational indicates that the ...";
CM_ SG_ 2364659198 Module10OperationalStatus "Operational Status of Module 10 in this High Voltage Energy Storage Pack Instance.  Not Operational is used when the module is initializing or not able to function (e.g. internal module level monitors have failed).  Operational indicates that the ...";
CM_ SG_ 2364659198 Module9OperationalStatus "Operational Status of Module 9 in this High Voltage Energy Storage Pack Instance.  Not Operational is used when the module is initializing or not able to function (e.g. internal module level monitors have failed).  Operational indicates that the ...";
CM_ SG_ 2364659198 Module8OperationalStatus "Operational Status of Module 8 in this High Voltage Energy Storage Pack Instance.  Not Operational is used when the module is initializing or not able to function (e.g. internal module level monitors have failed).  Operational indicates that the ...";
CM_ SG_ 2364659198 Module7OperationalStatus "Operational Status of Module 7 in this High Voltage Energy Storage Pack Instance.  Not Operational is used when the module is initializing or not able to function (e.g. internal module level monitors have failed).  Operational indicates that the ...";
CM_ SG_ 2364659198 Module6OperationalStatus "Operational Status of Module 6 in this High Voltage Energy Storage Pack Instance.  Not Operational is used when the module is initializing or not able to function (e.g. internal module level monitors have failed).  Operational indicates that the ...";
CM_ SG_ 2364659198 Module5OperationalStatus "Operational Status of Module 5 in this High Voltage Energy Storage Pack Instance.  Not Operational is used when the module is initializing or not able to function (e.g. internal module level monitors have failed).  Operational indicates that the ...";
CM_ SG_ 2364659198 Module4OperationalStatus "Operational Status of Module 4 in this High Voltage Energy Storage Pack Instance.  Not Operational is used when the module is initializing or not able to function (e.g. internal module level monitors have failed).  Operational indicates that the ...";
CM_ SG_ 2364659198 Module3OperationalStatus "Operational Status of Module 3 in this High Voltage Energy Storage Pack Instance.  Not Operational is used when the module is initializing or not able to function (e.g. internal module level monitors have failed).  Operational indicates that the ...";
CM_ SG_ 2364659198 Module2OperationalStatus "Operational Status of Module 2 in this High Voltage Energy Storage Pack Instance.  Not Operational is used when the module is initializing or not able to function (e.g. internal module level monitors have failed).  Operational indicates that the ...";
CM_ SG_ 2364659198 Module1OperationalStatus "Operational Status of Module 1 in this High Voltage Energy Storage Pack Instance.  Not Operational is used when the module is initializing or not able to function (e.g. internal module level monitors have failed).  Operational indicates that the ...";
CM_ BO_ 2364658942 "High Voltage Energy Storage Pack 5 Data 7
Data set 7 (electrical) for High Voltage Energy Storage Pack 5.";
CM_ SG_ 2364658942 MaxChargeVLmt "The maximum voltage level not to be exceeded while charging this High Voltage Energy Storage Pack instance.  If this parameter is not supported, the maximum charge voltage should be limited to SPN 11598 (HVESP5 Recommended Maximum Operating ...";
CM_ SG_ 2364658942 ChargeEnergyCapacity "The amount of unused electrical energy storage available to be filled by charging this High Voltage Energy Storage Pack instance, i.e. “how much empty space is remaining in the tank”.  See SPN 11527 (HVESP5 Charge Capacity) for Ampere-hours (Ah).
 ...";
CM_ SG_ 2364658942 DisEnergyCapacity "The amount of stored electrical energy in this High Voltage Energy Storage Pack instance that is available for use by the hybrid system, i.e. “how full is the tank”.  See SPN 11526 (HVESP5 Discharge Capacity) for Ampere-hours (Ah).
This parameter ...";
CM_ BO_ 2364658686 "High Voltage Energy Storage Pack 5 Status 1
Status data set 1 for High Voltage Energy Storage Pack 5.";
CM_ SG_ 2364658686 Status1CRC "The CRC is defined as follows:
• Length: 8 bits
• Polynomial: x^8+x^5+x^3+x^2+x+1
• Initial Value: FFh
• Input Data Reflection: Not reflected
• Result Data Reflection: Not reflected
• XOR value: FFh
SAE makes no claim of the functional safety ...";
CM_ SG_ 2364658686 Status1Counter "The message counter is used to detect situations where the transmitting ECU malfunction repeats the same frame all the time. The receiver of the information may use the counter parameter to detect this situation. The transmitting device will ...";
CM_ SG_ 2364658686 OperationalStatus "Provides feedback on where this High Voltage Energy Storage Pack instance is in its operating spectrum, and includes feedback in response to the Operation Consent [i.e. SPN 11499 (HVESP5 Operation Consent)] and Power Down Command [i.e. SPN 11494 ...";
CM_ SG_ 2364658686 HVBusConnectionStatus "This parameter provides high level feedback on this High Voltage Energy Storage Pack instance high voltage bus connection.  For specific contactor information, see SPN 11539 (HVESP5 High-Voltage Bus (Positive) Contactor State), SPN 11540 (HVESP5 ...";
CM_ SG_ 2364658686 InternalChargerStatus "Indicates that the charger in this HVES instance is on.  External chargers may use the External Energy Source Connection Status (SPN 7898) and related SPs.
This parameter is for one of multiple packs in an HVESS. If there is only one pack in the ...";
CM_ SG_ 2364658686 CellBalancingActive "Indicates whether or not the cells in this High Voltage Energy Storage Pack instance are currently being balanced.
This parameter is for one of multiple packs in an HVESS.  If there is only one pack in the system, the HVESS parameters should be ...";
CM_ SG_ 2364658686 CellBalanceStatus "Indicates whether or not the cells in this High Voltage Energy Storage Pack instance are balanced.
This parameter is for one of multiple packs in an HVESS.  If there is only one pack in the system, the HVESS parameters should be used. If there are ...";
CM_ SG_ 2364658686 StOfChargeStatus "Status of this High Voltage Energy Storage Pack instance State of Charge (SOC).  Note:  A given HVES controller may not support all of the states.
This parameter is for one of multiple packs in an HVESS.  If there is only one pack in the system, ...";
CM_ SG_ 2364658686 InertiaSwStatus "Switch indicating that an impact has been sensed by this High Voltage Energy Storage Pack instance. The impact indication may require action by another controller, or by this HVES instance itself.  For example, a controller may elect to take this ...";
CM_ SG_ 2364658686 HVILStatus "Status of the High Voltage Interlock Loop from the viewpoint of this High Voltage Energy Storage Pack instance.
This parameter is for one of multiple packs in an HVESS. If there is only one pack in the system, the HVESS parameters should be used ...";
CM_ SG_ 2364658686 HVBusPassiveIsolTestStatus "Status of the high-voltage bus electrical passive isolation test as performed by this High Voltage Energy Storage Pack instance.
This parameter is for one of multiple packs in an HVESS. If there is only one pack in the system, the HVESS parameters ...";
CM_ SG_ 2364658686 HVBusActiveIsolTestStatus "Status of the high-voltage bus electrical active isolation test as performed by this High Voltage Energy Storage Pack instance.
This parameter is for one of multiple packs in an HVESS. If there is only one pack in the system, the HVESS parameters ...";
CM_ SG_ 2364658686 CenterOfPackContactorSt "Position of the center high-voltage contactor.  When this contactor is closed, the positive half of this High Voltage Energy Storage Pack instance is connected to the negative half.  If a system controls the positive, negative, and center contactors ...";
CM_ SG_ 2364658686 HVBusPreChargeRelaySt "Position of the high-voltage bus contactor pre-charge relay.  When this relay is closed, this High Voltage Energy Storage Pack instance is bringing the high-voltage bus up to its operating level.
This parameter is for one of multiple packs in an ...";
CM_ SG_ 2364658686 HVBusDisconnectForewarning "Indicates that this High Voltage Energy Storage Pack instance is about to disconnect from the high voltage bus due to unacceptable conditions.
This parameter is for one of multiple packs in an HVESS. If there is only one pack in the system, the ...";
CM_ SG_ 2364658686 HVBusContactorSt11540 "Position of this High Voltage Energy Storage Pack instance negative side bus contactor.  When this contactor is closed, the negative side of this HVES instance is connected to the negative side of the high-voltage bus.  If a system controls the ...";
CM_ SG_ 2364658686 HVBusContactorSt "Position of this High Voltage Energy Storage Pack instance positive side bus contactor.  When this contactor is closed, the positive side of this HVES instance is connected to the positive side of the high-voltage bus.  In systems where all ...";
CM_ BO_ 2364658430 "High Voltage Energy Storage Pack 5 Data 6
Data set 6 (external or interface data) for High Voltage Energy Storage Pack 5.";
CM_ SG_ 2364658430 Temp "The temperature of this High Voltage Energy Storage Pack instance. The value may be determined from a unique sensor specifically for this purpose, or by aggregating various temperature sensor readings within the pack.
This parameter is for one of ...";
CM_ SG_ 2364658430 ETemp "The temperature of the electronics or control modules in this High Voltage Energy Storage Pack instance.  If there are multiple temperature sensors then this parameter would be set to the maximum sensor reading.
This parameter is for one of ...";
CM_ SG_ 2364658430 OutCoolantTemp "The temperature of liquid coolant as it exits this High Voltage Energy Storage Pack instance.
This parameter is for one of multiple packs in an HVESS.  If there is only one pack in the system, the HVESS parameters should be used. If there are ...";
CM_ SG_ 2364658430 InCoolantTemp "The temperature of liquid coolant as it enters this High Voltage Energy Storage Pack instance.
This parameter is for one of multiple packs in an HVESS.  If there is only one pack in the system, the HVESS parameters should be used. If there are ...";
CM_ SG_ 2364658430 IgntV "The voltage level at the ignition input of this High Voltage Energy Storage Pack controller.
This parameter is for one of multiple packs in an HVESS.  If there is only one pack in the system, the HVESS parameters should be used.  If there are ...";
CM_ SG_ 2364658430 BusV "The voltage level of the high voltage bus, as measured by this High Voltage Energy Storage Pack instance on the bus side (not the battery side) of its contactors.
This parameter is for one of multiple packs in an HVESS.  If there is only one pack ...";
CM_ BO_ 2364658174 "High Voltage Energy Storage Pack 5 Data 5
Data set 5 (electrical data) for High Voltage Energy Storage Pack 5.";
CM_ SG_ 2364658174 HighestCellStOfCharge "Indicates the state of charge of the highest-charged cell in this High Voltage Energy Storage Pack instance.  0% means no charge remaining, 100% means the cell is fully charged.  If a single state of charge value covers more than one cell, the value ...";
CM_ SG_ 2364658174 LowestCellStOfCharge "Indicates the state of charge of the lowest-charged cell in this High Voltage Energy Storage Pack instance.  0% means no charge remaining, 100% means the cell is fully charged.   If a single state of charge value covers more than one cell, the value ...";
CM_ SG_ 2364658174 ChargeCurLmt "The maximum instantaneous current flow limit into this High Voltage Energy Storage Pack instance. This parameter is defined from the high voltage energy storage pack's point of view and should reflect the instantaneous capability of the pack.  The ...";
CM_ SG_ 2364658174 DisCurLmt "The maximum instantaneous current flow limit out of this High Voltage Energy Storage Pack instance. This parameter is defined from the high voltage energy storage pack's point of view and should reflect the instantaneous capability of the pack.  The ...";
CM_ BO_ 2364657918 "High Voltage Energy Storage Pack 5 Data 4
Data set 4 (electrical data) for High Voltage Energy Storage Pack 5.";
CM_ SG_ 2364657918 CellBalancingCount "The number of cells that are currently being balanced in this High Voltage Energy Storage Pack instance.
This parameter is for one of multiple packs in an HVESS.  If there is only one pack in the system, the HVESS parameters should be used.  If ...";
CM_ SG_ 2364657918 ChargeCapacity "The amount of unused electrical charge storage in this High Voltage Energy Storage Pack instance that is available to be filled by charging, i.e. “how much empty space is remaining in the tank”.  See SPN 11555 (HVESP5 Charge Energy Capacity) for ...";
CM_ SG_ 2364657918 DisCapacity "The amount of stored electrical charge in this High Voltage Energy Storage Pack instance that is available for use by the hybrid system, i.e. “how full is the tank”.  See SPN 11554 (HVESP5 Discharge Energy Capacity) for kilowatt-hours (kWh).
This ...";
CM_ BO_ 2364657662 "High Voltage Energy Storage Pack 5 Data 3
Data set 3 (thermal data) for High Voltage Energy Storage Pack 5.";
CM_ SG_ 2364657662 CellTempDiffStatus "Indicates whether or not the differential between the highest and lowest cell temperatures are within acceptable limits per this High Voltage Energy Storage Pack instance.  The actual temperature differential can be calculated by subtracting SPN ...";
CM_ SG_ 2364657662 AvgCellTemp "The average temperature level of all cells in this High Voltage Energy Storage Pack instance.
This parameter is for one of multiple packs in an HVESS.  If there is only one pack in the system, the HVESS parameters should be used.  If there are ...";
CM_ SG_ 2364657662 LowestCellTemp "The lowest temperature level reported by any cell in this High Voltage Energy Storage Pack instance.  If a single temperature sensor covers more than one cell, the value in this parameter is for the smallest group of cells measured.  See SPN 11586 ...";
CM_ SG_ 2364657662 HighestCellTemp "The highest temperature level reported by any cell in this High Voltage Energy Storage Pack instance.  If a single temperature sensor covers more than one cell, the value in this parameter is for the smallest group of cells measured.   See SPN 11584 ...";
CM_ BO_ 2364657406 "High Voltage Energy Storage Pack 5 Data 2
Data set 2 (electrical data) for High Voltage Energy Storage Pack 5.";
CM_ SG_ 2364657406 CellVDiffStatus "Indicates whether or not the differential between the highest and lowest cell voltages are within acceptable limits, according to this High Voltage Energy Storage Pack instance. The actual voltage differential can be calculated by subtracting SPN ...";
CM_ SG_ 2364657406 LowestCellV "The lowest voltage level reported by any cell in this High Voltage Energy Storage Pack instance. If a single voltage sensor covers more than one cell, the value in this parameter is for the smallest group of cells measured.  See SPN 11581 (HVESP5 ...";
CM_ SG_ 2364657406 HighestCellV "The highest voltage level reported by any cell in this High Voltage Energy Storage Pack instance. If a single voltage sensor covers more than one cell, the value in this parameter is for the smallest group of cells measured. See SPN 11579 (HVESP5 ...";
CM_ SG_ 2364657406 FastUpdateStOfCharge "Indicates this High Voltage Energy Storage Pack instance state of charge.  0% means no charge remaining, 100% means the system is fully charged in terms of physical limits of this energy storage pack instance.  Acceptable state of charge upper and ...";
CM_ BO_ 2364657150 "High Voltage Energy Storage Pack 5 Data 1
Data set 1 (electrical data) for High Voltage Energy Storage Pack 5.";
CM_ SG_ 2364657150 Cur "The current in or out of this High Voltage Energy Storage Pack instance. This parameter should be synchronized with SPN 11516 (HVESP5 Voltage Level) such that a realized power value can be calculated.  This parameter is defined from the high voltage ...";
CM_ SG_ 2364657150 Lvl "The voltage level of this High Voltage Energy Storage Pack instance. This parameter should be synchronized with SPN 11517 (HVESP5 Current) such that a realized power value can be calculated.  If the HVES component physically contains the contactors ...";
CM_ SG_ 2364657150 AvailableChargePwr "The rate at which this High Voltage Energy Storage Pack instance can currently receive energy from a regenerative or recharging system.
This parameter is for one of multiple packs in an HVESS.  If there is only one pack in the system, the HVESS ...";
CM_ SG_ 2364657150 AvailableDisPwr "The rate at which this High Voltage Energy Storage Pack instance can currently provide energy for propulsion or other uses.
This parameter is for one of multiple packs in an HVESS.  If there is only one pack in the system, the HVESS parameters ...";
CM_ BO_ 2364656894 "High Voltage Energy Storage Pack 5 Status 2
Status data set 2 for High Voltage Energy Storage Pack 5.";
CM_ SG_ 2364656894 ChargePLDueToAnUndefinedCause "Indicates whether or not charge power of this HVES instance is being limited due to an undefined cause.
This parameter is for one of multiple packs in an HVESS.  If there is only one pack in the system, the HVESS parameters should be used. If there ...";
CM_ SG_ 2364656894 ChargePLDueToBatCur "Indicates whether or not charge power of this HVES instance is being limited due to battery current.
This parameter is for one of multiple packs in an HVESS.  If there is only one pack in the system, the HVESS parameters should be used. If there ...";
CM_ SG_ 2364656894 ChargePLDueToBatOrCellV "Indicates whether or not charge power of this HVES instance is being limited due to a battery or cell voltage level.
This parameter is for one of multiple packs in an HVESS.  If there is only one pack in the system, the HVESS parameters should be ...";
CM_ SG_ 2364656894 ChargePLDueToBatDiagCondition "Indicates whether or not charge power of this HVES instance is being limited due to a battery diagnostic condition.
This parameter is for one of multiple packs in an HVESS.  If there is only one pack in the system, the HVESS parameters should be ...";
CM_ SG_ 2364656894 ChargePLDueToBatTemp "Indicates whether or not charge power of this HVES instance is being limited due to battery temperature.
This parameter is for one of multiple packs in an HVESS.  If there is only one pack in the system, the HVESS parameters should be used. If ...";
CM_ SG_ 2364656894 ChargePLDueToStOfCharge "Indicates whether or not charge power of this HVES instance is being limited due to state of charge.
This parameter is for one of multiple packs in an HVESS.  If there is only one pack in the system, the HVESS parameters should be used. If there ...";
CM_ SG_ 2364656894 DisPLDueToAnUndefinedCause "Indicates whether or not discharge power of this HVES instance is being limited due to an undefined cause.
This parameter is for one of multiple packs in an HVESS.  If there is only one pack in the system, the HVESS parameters should be used. If ...";
CM_ SG_ 2364656894 DisPLDueToBatCur "Indicates whether or not discharge power of this HVES instance is being limited due to battery current.
This parameter is for one of multiple packs in an HVESS.  If there is only one pack in the system, the HVESS parameters should be used. If there ...";
CM_ SG_ 2364656894 DisPLDueToBatOrCellV "Indicates whether or not discharge power of this HVES instance is being limited due to a battery or cell voltage level.
This parameter is for one of multiple packs in an HVESS.  If there is only one pack in the system, the HVESS parameters should ...";
CM_ SG_ 2364656894 DisPLDueToBatDiagCondition "Indicates whether or not discharge power of this HVES instance is being limited due to a battery diagnostic condition.
This parameter is for one of multiple packs in an HVESS.  If there is only one pack in the system, the HVESS parameters should be ...";
CM_ SG_ 2364656894 DisPLDueToBatTemp "Indicates whether or not discharge power of this HVES instance is being limited due to battery temperature.
This parameter is for one of multiple packs in an HVESS.  If there is only one pack in the system, the HVESS parameters should be used. If ...";
CM_ SG_ 2364656894 DisPLDueToStOfCharge "Indicates whether or not discharge power of this HVES instance is being limited due to state of charge.
This parameter is for one of multiple packs in an HVESS.  If there is only one pack in the system, the HVESS parameters should be used. If there ...";
CM_ BO_ 2364656638 "High Voltage Energy Storage Pack 4 Data 11
Data set 11 (electrical data) for High Voltage Energy Storage Pack 4.";
CM_ SG_ 2364656638 ActualChargeRate "This signal represents the actual present charge rate of this High Voltage Energy Storage Pack instance.
This parameter is for one of multiple packs in an HVESS. If there is only one pack in the system, the HVESS parameters should be used. If there ...";
CM_ SG_ 2364656638 LvlNegToChassisGroundV "Voltage difference between the most negative terminal of the HVES battery and chassis measured at the battery side of any HVES contained output contactor.  This voltage may be used for system level monitoring of battery shorts to chassis within the ...";
CM_ SG_ 2364656638 BusVNegToChassisGroundV "Voltage difference between the most negative terminal of the HVES battery and chassis measured on the hybrid system bus side (not the battery side) of any HVES contained output contactor.  This voltage may be used for system level monitoring of ...";
CM_ BO_ 2364656382 "High Voltage Energy Storage Pack 4 Data 10
Data set 10 (electrical) for High Voltage Energy Storage Pack 4.";
CM_ SG_ 2364656382 HVBusPassiveIsolTestResults "The isolation resistance expressed in Ohms per Volt that resulted from the High-Voltage Bus Passive Isolation Test.
See SPN 11429 (HVESP4 High-Voltage Bus Passive Isolation Test Status) for test status and SPN 11380 (HVESP4 High-Voltage Bus Passive ...";
CM_ SG_ 2364656382 HVBusActiveIsolTestResults "The isolation resistance expressed in Ohms per Volt that resulted from the High-Voltage Bus Active Isolation Test.
See SPN 11428 (HVESP4 High-Voltage Bus Active Isolation Test Status) for test status and SPN 11379 (HVESP4 High-Voltage Bus Active ...";
CM_ SG_ 2364656382 LowestCellStOfChargeCellNum "Identifies the location of SPN 11415 (HVESP4 Lowest Cell State of Charge) within SPN 11474 (HVESP4 Lowest Cell State of Charge Module Number).
This parameter is for one of multiple packs in an HVESS.  If there is only one pack in the system, the ...";
CM_ SG_ 2364656382 LowestCellStOfChargeModuleNum "Identifies the location of the module containing SPN 11415 (HVESP4 Lowest Cell State of Charge).
This parameter is for one of multiple packs in an HVESS.  If there is only one pack in the system, the HVESS parameters should be used. If there are ...";
CM_ SG_ 2364656382 HighestCellStOfChargeCellNum "Identifies the location of SPN 11416 (HVESP4 Highest Cell State of Charge) within SPN 11472 (HVESP4 Highest Cell State of Charge Module Number).
This parameter is for one of multiple packs in an HVESS.  If there is only one pack in the system, the ...";
CM_ SG_ 2364656382 HighestCellStOfChargeModuleNum "Identifies the location of the module containing SPN 11416 (HVESP4 Highest Cell State of Charge).
This parameter is for one of multiple packs in an HVESS.  If there is only one pack in the system, the HVESS parameters should be used. If there are ...";
CM_ BO_ 2364656126 "High Voltage Energy Storage Pack 4 Data 9
Data set 9 (thermal) for High Voltage Energy Storage Pack 4.";
CM_ SG_ 2364656126 Data9CRC "The CRC is defined as follows:
• Length: 8 bits
• Polynomial: x^8+x^5+x^3+x^2+x+1
• Initial Value: FFh
• Input Data Reflection: Not reflected
• Result Data Reflection: Not reflected
• XOR value: FFh
SAE makes no claim of the functional safety ...";
CM_ SG_ 2364656126 Data9Counter "The message counter is used to detect situations where the transmitting ECU malfunction repeats the same frame all the time. The receiver of the information may use the counter parameter to detect this situation. The transmitting device will ...";
CM_ SG_ 2364656126 Data9EmbeddedIntegritySupport "Indicates SPN 22985 (HVESP4 Data 9 CRC) and SPN 22984 (HVESP4 Data 9 Counter) are supported by the sender.
00b = Embedded CRC and Counter are supported by the sender
01b = Protection is supported using J1939-76 SHM
10b = Reserved
11b = CRC and ...";
CM_ SG_ 2364656126 HVESS4ThermalEventDetected "A sensor has detected the presence of a thermal event at or near High Voltage Energy Storage Pack instance.
00b = No Thermal Event Detected
01b = Thermal Event Detected
10b = Error
11b = Not available
This parameter is for one of multiple packs ...";
CM_ SG_ 2364656126 LowestCellTempCellNum "Identifies the location of SPN 11407 (HVESP4 Lowest Cell Temperature) within SPN 11470 (HVESP4 Lowest Cell Temperature Module Number).
This parameter is for one of multiple packs in an HVESS.  If there is only one pack in the system, the HVESS ...";
CM_ SG_ 2364656126 LowestCellTempModuleNum "Identifies the location of the module containing SPN 11407 (HVESP4 Lowest Cell Temperature).
This parameter is for one of multiple packs in an HVESS.  If there is only one pack in the system, the HVESS parameters should be used. If there are ...";
CM_ SG_ 2364656126 HighestCellTempCellNum "Identifies the location of SPN 11406 (HVESP4 Highest Cell Temperature) within SPN 11468 (HVESP4 Highest Cell Temperature Module Number).
This parameter is for one of multiple packs in an HVESS.  If there is only one pack in the system, the HVESS ...";
CM_ SG_ 2364656126 HighestCellTempModuleNum "Identifies the location of the module containing SPN 11406 (HVESP4 Highest Cell Temperature).
This parameter is for one of multiple packs in an HVESS.  If there is only one pack in the system, the HVESS parameters should be used. If there are ...";
CM_ BO_ 2364655870 "High Voltage Energy Storage Pack 4 Data 8
Data set 8 (electrical data) for High Voltage Energy Storage Pack 4.";
CM_ SG_ 2364655870 AvgCellV "The average cell voltage in this High Voltage Energy Storage Pack instance.
This parameter is for one of multiple packs in an HVESS.  If there is only one pack in the system, the HVESS parameters should be used. If there are multiple packs in the ...";
CM_ SG_ 2364655870 LowestCellVCellNum "Identifies the location of SPN 11404 (HVESP4 Lowest Cell Voltage) within SPN 11465 (HVESP4 Lowest Cell Voltage Module Number).
This parameter is for one of multiple packs in an HVESS.  If there is only one pack in the system, the HVESS parameters ...";
CM_ SG_ 2364655870 LowestCellVModuleNum "Identifies the location of the module containing SPN 11404 (HVESP4 Lowest Cell Voltage).
This parameter is for one of multiple packs in an HVESS.  If there is only one pack in the system, the HVESS parameters should be used. If there are multiple ...";
CM_ SG_ 2364655870 HighestCellVCellNum "Identifies the location of SPN 11403 (HVESP4 Highest Cell Voltage) within SPN 11463 (HVESP4 Highest Cell Voltage Module Number).
This parameter is for one of multiple packs in an HVESS.  If there is only one pack in the system, the HVESS parameters ...";
CM_ SG_ 2364655870 HighestCellVModuleNum "Identifies the location of the module containing SPN 11403 (HVESP4 Highest Cell Voltage).
This parameter is for one of multiple packs in an HVESS.  If there is only one pack in the system, the HVESS parameters should be used. If there are multiple ...";
CM_ BO_ 2364655614 "High Voltage Energy Storage Pack 4 Thermal Management System Status 1
Collection of data the High Voltage Energy Storage Pack 4 Thermal Management System sends to the Hybrid Controller.";
CM_ SG_ 2364655614 TMSCoolantLvl "Indicates the coolant level in this HVES Thermal Management System (TMS).
This parameter is for one of multiple packs in an HVESS.  If there is only one pack in the system, the HVESS parameters should be used. If there are multiple packs in the ...";
CM_ SG_ 2364655614 TMSMode "Indicates the operating mode of the Thermal Management System.  The heat transfer medium may be (e.g. liquid or air).  The cooling system may be fans, liquid coolant, or a combination of mediums.  The system may include an air and/or liquid ...";
CM_ SG_ 2364655614 TMSHVILStatus "In multiple HVES configurations, this is the status of the High Voltage Interlock Loop from the viewpoint of this Thermal Management System.
00b = HVIL Closed
01b = HVIL Open
10b = Error
11b = Not Available
This parameter is for one of multiple ...";
CM_ SG_ 2364655614 TMSHtrStatus "The state of this High Voltage Energy Storage Pack heater
This parameter is for one of multiple packs in an HVESS.  If there is only one pack in the system, the HVESS parameters should be used. If there are multiple packs in the system, then both ...";
CM_ SG_ 2364655614 TMSRelHumidty "When this High Voltage Energy Storage Pack Thermal Management System is equipped with a relative humidity sensor, this is the  measured Relative Humidity.
This parameter is for one of multiple packs in an HVESS.  If there is only one pack in the ...";
CM_ SG_ 2364655614 TMSCompressorSpd "When this High Voltage Energy Storage Pack Thermal Management System is equipped with an active cooling system (e.g. air conditioner), this is the Compressor Speed.
This parameter is for one of multiple packs in an HVESS.  If there is only one pack ...";
CM_ SG_ 2364655614 TMSHVInputPwr "This is the high-voltage power consumed by this HVES Thermal Management System (TMS).
This parameter is for one of multiple packs in an HVESS.  If there is only one pack in the system, the HVESS parameters should be used. If there are multiple ...";
CM_ SG_ 2364655614 TMSSLIInputPwr "This is the low-voltage power consumed by this HVES Thermal Management System (TMS).
This parameter is for one of multiple packs in an HVESS.  If there is only one pack in the system, the HVESS parameters should be used.  If there are multiple ...";
CM_ BO_ 2364655358 "High Voltage Energy Storage Pack 4 Module Status 1
Module Status message 1 for High Voltage Energy Storage Pack 4.";
CM_ SG_ 2364655358 Module32OperationalStatus "Operational Status of Module 32 in this High Voltage Energy Storage System (or Pack 1 in systems with only one pack).  Not Operational is used when the module is initializing or not able to function (e.g. internal module level monitors have failed) ...";
CM_ SG_ 2364655358 Module31OperationalStatus "Operational Status of Module 31 in this High Voltage Energy Storage System (or Pack 1 in systems with only one pack).  Not Operational is used when the module is initializing or not able to function (e.g. internal module level monitors have failed) ...";
CM_ SG_ 2364655358 Module30OperationalStatus "Operational Status of Module 30 in this High Voltage Energy Storage System (or Pack 1 in systems with only one pack).  Not Operational is used when the module is initializing or not able to function (e.g. internal module level monitors have failed) ...";
CM_ SG_ 2364655358 Module29OperationalStatus "Operational Status of Module 29 in this High Voltage Energy Storage System (or Pack 1 in systems with only one pack).  Not Operational is used when the module is initializing or not able to function (e.g. internal module level monitors have failed) ...";
CM_ SG_ 2364655358 Module28OperationalStatus "Operational Status of Module 28 in this High Voltage Energy Storage System (or Pack 1 in systems with only one pack).  Not Operational is used when the module is initializing or not able to function (e.g. internal module level monitors have failed) ...";
CM_ SG_ 2364655358 Module27OperationalStatus "Operational Status of Module 27 in this High Voltage Energy Storage System (or Pack 1 in systems with only one pack).  Not Operational is used when the module is initializing or not able to function (e.g. internal module level monitors have failed) ...";
CM_ SG_ 2364655358 Module26OperationalStatus "Operational Status of Module 26 in this High Voltage Energy Storage System (or Pack 1 in systems with only one pack).  Not Operational is used when the module is initializing or not able to function (e.g. internal module level monitors have failed) ...";
CM_ SG_ 2364655358 Module25OperationalStatus "Operational Status of Module 25 in this High Voltage Energy Storage System (or Pack 1 in systems with only one pack).  Not Operational is used when the module is initializing or not able to function (e.g. internal module level monitors have failed) ...";
CM_ SG_ 2364655358 Module24OperationalStatus "Operational Status of Module 24 in this High Voltage Energy Storage System (or Pack 1 in systems with only one pack).  Not Operational is used when the module is initializing or not able to function (e.g. internal module level monitors have failed) ...";
CM_ SG_ 2364655358 Module23OperationalStatus "Operational Status of Module 23 in this High Voltage Energy Storage System (or Pack 1 in systems with only one pack).  Not Operational is used when the module is initializing or not able to function (e.g. internal module level monitors have failed) ...";
CM_ SG_ 2364655358 Module22OperationalStatus "Operational Status of Module 22 in this High Voltage Energy Storage System (or Pack 1 in systems with only one pack).  Not Operational is used when the module is initializing or not able to function (e.g. internal module level monitors have failed) ...";
CM_ SG_ 2364655358 Module21OperationalStatus "Operational Status of Module 21 in this High Voltage Energy Storage System (or Pack 1 in systems with only one pack).  Not Operational is used when the module is initializing or not able to function (e.g. internal module level monitors have failed) ...";
CM_ SG_ 2364655358 Module20OperationalStatus "Operational Status of Module 20 in this High Voltage Energy Storage System (or Pack 1 in systems with only one pack).  Not Operational is used when the module is initializing or not able to function (e.g. internal module level monitors have failed) ...";
CM_ SG_ 2364655358 Module19OperationalStatus "Operational Status of Module 19 in this High Voltage Energy Storage System (or Pack 1 in systems with only one pack).  Not Operational is used when the module is initializing or not able to function (e.g. internal module level monitors have failed) ...";
CM_ SG_ 2364655358 Module18OperationalStatus "Operational Status of Module 18 in this High Voltage Energy Storage System (or Pack 1 in systems with only one pack).  Not Operational is used when the module is initializing or not able to function (e.g. internal module level monitors have failed) ...";
CM_ SG_ 2364655358 Module17OperationalStatus "Operational Status of Module 17 in this High Voltage Energy Storage System (or Pack 1 in systems with only one pack).  Not Operational is used when the module is initializing or not able to function (e.g. internal module level monitors have failed) ...";
CM_ SG_ 2364655358 Module16OperationalStatus "Operational Status of Module 16 in this High Voltage Energy Storage Pack Instance.  Not Operational is used when the module is initializing or not able to function (e.g. internal module level monitors have failed).  Operational indicates that the ...";
CM_ SG_ 2364655358 Module15OperationalStatus "Operational Status of Module 15 in this High Voltage Energy Storage Pack Instance.  Not Operational is used when the module is initializing or not able to function (e.g. internal module level monitors have failed).  Operational indicates that the ...";
CM_ SG_ 2364655358 Module14OperationalStatus "Operational Status of Module 14 in this High Voltage Energy Storage Pack Instance.  Not Operational is used when the module is initializing or not able to function (e.g. internal module level monitors have failed).  Operational indicates that the ...";
CM_ SG_ 2364655358 Module13OperationalStatus "Operational Status of Module 13 in this High Voltage Energy Storage Pack Instance.  Not Operational is used when the module is initializing or not able to function (e.g. internal module level monitors have failed).  Operational indicates that the ...";
CM_ SG_ 2364655358 Module12OperationalStatus "Operational Status of Module 12 in this High Voltage Energy Storage Pack Instance.  Not Operational is used when the module is initializing or not able to function (e.g. internal module level monitors have failed).  Operational indicates that the ...";
CM_ SG_ 2364655358 Module11OperationalStatus "Operational Status of Module 11 in this High Voltage Energy Storage Pack Instance.  Not Operational is used when the module is initializing or not able to function (e.g. internal module level monitors have failed).  Operational indicates that the ...";
CM_ SG_ 2364655358 Module10OperationalStatus "Operational Status of Module 10 in this High Voltage Energy Storage Pack Instance.  Not Operational is used when the module is initializing or not able to function (e.g. internal module level monitors have failed).  Operational indicates that the ...";
CM_ SG_ 2364655358 Module9OperationalStatus "Operational Status of Module 9 in this High Voltage Energy Storage Pack Instance.  Not Operational is used when the module is initializing or not able to function (e.g. internal module level monitors have failed).  Operational indicates that the ...";
CM_ SG_ 2364655358 Module8OperationalStatus "Operational Status of Module 8 in this High Voltage Energy Storage Pack Instance.  Not Operational is used when the module is initializing or not able to function (e.g. internal module level monitors have failed).  Operational indicates that the ...";
CM_ SG_ 2364655358 Module7OperationalStatus "Operational Status of Module 7 in this High Voltage Energy Storage Pack Instance.  Not Operational is used when the module is initializing or not able to function (e.g. internal module level monitors have failed).  Operational indicates that the ...";
CM_ SG_ 2364655358 Module6OperationalStatus "Operational Status of Module 6 in this High Voltage Energy Storage Pack Instance.  Not Operational is used when the module is initializing or not able to function (e.g. internal module level monitors have failed).  Operational indicates that the ...";
CM_ SG_ 2364655358 Module5OperationalStatus "Operational Status of Module 5 in this High Voltage Energy Storage Pack Instance.  Not Operational is used when the module is initializing or not able to function (e.g. internal module level monitors have failed).  Operational indicates that the ...";
CM_ SG_ 2364655358 Module4OperationalStatus "Operational Status of Module 4 in this High Voltage Energy Storage Pack Instance.  Not Operational is used when the module is initializing or not able to function (e.g. internal module level monitors have failed).  Operational indicates that the ...";
CM_ SG_ 2364655358 Module3OperationalStatus "Operational Status of Module 3 in this High Voltage Energy Storage Pack Instance.  Not Operational is used when the module is initializing or not able to function (e.g. internal module level monitors have failed).  Operational indicates that the ...";
CM_ SG_ 2364655358 Module2OperationalStatus "Operational Status of Module 2 in this High Voltage Energy Storage Pack Instance.  Not Operational is used when the module is initializing or not able to function (e.g. internal module level monitors have failed).  Operational indicates that the ...";
CM_ SG_ 2364655358 Module1OperationalStatus "Operational Status of Module 1 in this High Voltage Energy Storage Pack Instance.  Not Operational is used when the module is initializing or not able to function (e.g. internal module level monitors have failed).  Operational indicates that the ...";
CM_ BO_ 2364655102 "High Voltage Energy Storage Pack 4 Data 7
Data set 7 (electrical) for High Voltage Energy Storage Pack 4.";
CM_ SG_ 2364655102 MaxChargeVLmt "The maximum voltage level not to be exceeded while charging this High Voltage Energy Storage Pack instance.  If this parameter is not supported, the maximum charge voltage should be limited to SPN 11482 (HVESP4 Recommended Maximum Operating ...";
CM_ SG_ 2364655102 ChargeEnergyCapacity "The amount of unused electrical energy storage available to be filled by charging this High Voltage Energy Storage Pack instance, i.e. “how much empty space is remaining in the tank”.  See SPN 11411 (HVESP4 Charge Capacity) for Ampere-hours (Ah).
 ...";
CM_ SG_ 2364655102 DisEnergyCapacity "The amount of stored electrical energy in this High Voltage Energy Storage Pack instance that is available for use by the hybrid system, i.e. “how full is the tank”.  See SPN 11410 (HVESP4 Discharge Capacity) for Ampere-hours (Ah).
This parameter ...";
CM_ BO_ 2364654846 "High Voltage Energy Storage Pack 4 Status 1
Status data set 1 for High Voltage Energy Storage Pack 4.";
CM_ SG_ 2364654846 Status1CRC "The CRC is defined as follows:
• Length: 8 bits
• Polynomial: x^8+x^5+x^3+x^2+x+1
• Initial Value: FFh
• Input Data Reflection: Not reflected
• Result Data Reflection: Not reflected
• XOR value: FFh
SAE makes no claim of the functional safety ...";
CM_ SG_ 2364654846 Status1Counter "The message counter is used to detect situations where the transmitting ECU malfunction repeats the same frame all the time. The receiver of the information may use the counter parameter to detect this situation. The transmitting device will ...";
CM_ SG_ 2364654846 OperationalStatus "Provides feedback on where this High Voltage Energy Storage Pack instance is in its operating spectrum, and includes feedback in response to the Operation Consent [i.e. SPN 11383 (HVESP4 Operation Consent)] and Power Down Command [i.e. SPN 11378 ...";
CM_ SG_ 2364654846 HVBusConnectionStatus "This parameter provides high level feedback on this High Voltage Energy Storage Pack instance high voltage bus connection.  For specific contactor information, see SPN 11423 (HVESP4 High-Voltage Bus (Positive) Contactor State), SPN 11424 (HVESP4 ...";
CM_ SG_ 2364654846 InternalChargerStatus "Indicates that the charger in this HVES instance is on.  External chargers may use the External Energy Source Connection Status (SPN 7898) and related SPs.
This parameter is for one of multiple packs in an HVESS. If there is only one pack in the ...";
CM_ SG_ 2364654846 CellBalancingActive "Indicates whether or not the cells in this High Voltage Energy Storage Pack instance are currently being balanced.
This parameter is for one of multiple packs in an HVESS.  If there is only one pack in the system, the HVESS parameters should be ...";
CM_ SG_ 2364654846 CellBalanceStatus "Indicates whether or not the cells in this High Voltage Energy Storage Pack instance are balanced.
This parameter is for one of multiple packs in an HVESS.  If there is only one pack in the system, the HVESS parameters should be used. If there are ...";
CM_ SG_ 2364654846 StOfChargeStatus "Status of this High Voltage Energy Storage Pack instance State of Charge (SOC).  Note:  A given HVES controller may not support all of the states.
This parameter is for one of multiple packs in an HVESS.  If there is only one pack in the system, ...";
CM_ SG_ 2364654846 InertiaSwStatus "Switch indicating that an impact has been sensed by this High Voltage Energy Storage Pack instance. The impact indication may require action by another controller, or by this HVES instance itself.  For example, a controller may elect to take this ...";
CM_ SG_ 2364654846 HVILStatus "Status of the High Voltage Interlock Loop from the viewpoint of this High Voltage Energy Storage Pack instance.
This parameter is for one of multiple packs in an HVESS. If there is only one pack in the system, the HVESS parameters should be used ...";
CM_ SG_ 2364654846 HVBusPassiveIsolTestStatus "Status of the high-voltage bus electrical passive isolation test as performed by this High Voltage Energy Storage Pack instance.
This parameter is for one of multiple packs in an HVESS. If there is only one pack in the system, the HVESS parameters ...";
CM_ SG_ 2364654846 HVBusActiveIsolTestStatus "Status of the high-voltage bus electrical active isolation test as performed by this High Voltage Energy Storage Pack instance.
This parameter is for one of multiple packs in an HVESS. If there is only one pack in the system, the HVESS parameters ...";
CM_ SG_ 2364654846 CenterOfPackContactorSt "Position of the center high-voltage contactor.  When this contactor is closed, the positive half of this High Voltage Energy Storage Pack instance is connected to the negative half.  If a system controls the positive, negative, and center contactors ...";
CM_ SG_ 2364654846 HVBusPreChargeRelaySt "Position of the high-voltage bus contactor pre-charge relay.  When this relay is closed, this High Voltage Energy Storage Pack instance is bringing the high-voltage bus up to its operating level.
This parameter is for one of multiple packs in an ...";
CM_ SG_ 2364654846 HVBusDisconnectForewarning "Indicates that this High Voltage Energy Storage Pack instance is about to disconnect from the high voltage bus due to unacceptable conditions.
This parameter is for one of multiple packs in an HVESS. If there is only one pack in the system, the ...";
CM_ SG_ 2364654846 HVBusContactorSt11424 "Position of this High Voltage Energy Storage Pack instance negative side bus contactor.  When this contactor is closed, the negative side of this HVES instance is connected to the negative side of the high-voltage bus.  If a system controls the ...";
CM_ SG_ 2364654846 HVBusContactorSt "Position of this High Voltage Energy Storage Pack instance positive side bus contactor.  When this contactor is closed, the positive side of this HVES instance is connected to the positive side of the high-voltage bus.  In systems where all ...";
CM_ BO_ 2364654590 "High Voltage Energy Storage Pack 4 Data 6
Data set 6 (external or interface data) for High Voltage Energy Storage Pack 4.";
CM_ SG_ 2364654590 Temp "The temperature of this High Voltage Energy Storage Pack instance. The value may be determined from a unique sensor specifically for this purpose, or by aggregating various temperature sensor readings within the pack.
This parameter is for one of ...";
CM_ SG_ 2364654590 ETemp "The temperature of the electronics or control modules in this High Voltage Energy Storage Pack instance.  If there are multiple temperature sensors then this parameter would be set to the maximum sensor reading.
This parameter is for one of ...";
CM_ SG_ 2364654590 OutCoolantTemp "The temperature of liquid coolant as it exits this High Voltage Energy Storage Pack instance.
This parameter is for one of multiple packs in an HVESS.  If there is only one pack in the system, the HVESS parameters should be used. If there are ...";
CM_ SG_ 2364654590 InCoolantTemp "The temperature of liquid coolant as it enters this High Voltage Energy Storage Pack instance.
This parameter is for one of multiple packs in an HVESS.  If there is only one pack in the system, the HVESS parameters should be used. If there are ...";
CM_ SG_ 2364654590 IgntV "The voltage level at the ignition input of this High Voltage Energy Storage Pack controller.
This parameter is for one of multiple packs in an HVESS.  If there is only one pack in the system, the HVESS parameters should be used.  If there are ...";
CM_ SG_ 2364654590 BusV "The voltage level of the high voltage bus, as measured by this High Voltage Energy Storage Pack instance on the bus side (not the battery side) of its contactors.
This parameter is for one of multiple packs in an HVESS.  If there is only one pack ...";
CM_ BO_ 2364654334 "High Voltage Energy Storage Pack 4 Data 5
Data set 5 (electrical data) for High Voltage Energy Storage Pack 4.";
CM_ SG_ 2364654334 HighestCellStOfCharge "Indicates the state of charge of the highest-charged cell in this High Voltage Energy Storage Pack instance.  0% means no charge remaining, 100% means the cell is fully charged.  If a single state of charge value covers more than one cell, the value ...";
CM_ SG_ 2364654334 LowestCellStOfCharge "Indicates the state of charge of the lowest-charged cell in this High Voltage Energy Storage Pack instance.  0% means no charge remaining, 100% means the cell is fully charged.   If a single state of charge value covers more than one cell, the value ...";
CM_ SG_ 2364654334 ChargeCurLmt "The maximum instantaneous current flow limit into this High Voltage Energy Storage Pack instance. This parameter is defined from the high voltage energy storage pack's point of view and should reflect the instantaneous capability of the pack.  The ...";
CM_ SG_ 2364654334 DisCurLmt "The maximum instantaneous current flow limit out of this High Voltage Energy Storage Pack instance. This parameter is defined from the high voltage energy storage pack's point of view and should reflect the instantaneous capability of the pack.  The ...";
CM_ BO_ 2364654078 "High Voltage Energy Storage Pack 4 Data 4
Data set 4 (electrical data) for High Voltage Energy Storage Pack 4.";
CM_ SG_ 2364654078 CellBalancingCount "The number of cells that are currently being balanced in this High Voltage Energy Storage Pack instance.
This parameter is for one of multiple packs in an HVESS.  If there is only one pack in the system, the HVESS parameters should be used.  If ...";
CM_ SG_ 2364654078 ChargeCapacity "The amount of unused electrical charge storage in this High Voltage Energy Storage Pack instance that is available to be filled by charging, i.e. “how much empty space is remaining in the tank”.  See SPN 11439 (HVESP4 Charge Energy Capacity) for ...";
CM_ SG_ 2364654078 DisCapacity "The amount of stored electrical charge in this High Voltage Energy Storage Pack instance that is available for use by the hybrid system, i.e. “how full is the tank”.  See SPN 11438 (HVESP4 Discharge Energy Capacity) for kilowatt-hours (kWh).
This ...";
CM_ BO_ 2364653822 "High Voltage Energy Storage Pack 4 Data 3
Data set 3 (thermal data) for High Voltage Energy Storage Pack 4.";
CM_ SG_ 2364653822 CellTempDiffStatus "Indicates whether or not the differential between the highest and lowest cell temperatures are within acceptable limits per this High Voltage Energy Storage Pack instance.  The actual temperature differential can be calculated by subtracting SPN ...";
CM_ SG_ 2364653822 AvgCellTemp "The average temperature level of all cells in this High Voltage Energy Storage Pack instance.
This parameter is for one of multiple packs in an HVESS.  If there is only one pack in the system, the HVESS parameters should be used.  If there are ...";
CM_ SG_ 2364653822 LowestCellTemp "The lowest temperature level reported by any cell in this High Voltage Energy Storage Pack instance.  If a single temperature sensor covers more than one cell, the value in this parameter is for the smallest group of cells measured.  See SPN 11470 ...";
CM_ SG_ 2364653822 HighestCellTemp "The highest temperature level reported by any cell in this High Voltage Energy Storage Pack instance.  If a single temperature sensor covers more than one cell, the value in this parameter is for the smallest group of cells measured.   See SPN 11468 ...";
CM_ BO_ 2364653566 "High Voltage Energy Storage Pack 4 Data 2
Data set 2 (electrical data) for High Voltage Energy Storage Pack 4.";
CM_ SG_ 2364653566 CellVDiffStatus "Indicates whether or not the differential between the highest and lowest cell voltages are within acceptable limits, according to this High Voltage Energy Storage Pack instance. The actual voltage differential can be calculated by subtracting SPN ...";
CM_ SG_ 2364653566 LowestCellV "The lowest voltage level reported by any cell in this High Voltage Energy Storage Pack instance. If a single voltage sensor covers more than one cell, the value in this parameter is for the smallest group of cells measured.  See SPN 11465 (HVESP4 ...";
CM_ SG_ 2364653566 HighestCellV "The highest voltage level reported by any cell in this High Voltage Energy Storage Pack instance. If a single voltage sensor covers more than one cell, the value in this parameter is for the smallest group of cells measured. See SPN 11463 (HVESP4 ...";
CM_ SG_ 2364653566 FastUpdateStOfCharge "Indicates this High Voltage Energy Storage Pack instance state of charge.  0% means no charge remaining, 100% means the system is fully charged in terms of physical limits of this energy storage pack instance.  Acceptable state of charge upper and ...";
BA_DEF_ SG_  "GenSigInactiveValue" INT 0 0;
BA_DEF_ SG_  "SigType" ENUM  "Default","Range","RangeSigned","ASCII","Discrete","Control","ReferencePGN","DTC","StringDelimiter","StringLength","StringLengthControl","MessageCounter","MessageChecksum";
BA_DEF_ SG_  "GenSigStartValue" INT 0 2147483647;
BA_DEF_ SG_  "GenSigSendType" ENUM  "Cyclic","OnWrite","OnWriteWithRepetition","OnChange","OnChangeWithRepetition","IfActive","IfActiveWithRepetition","NoSigSendType";
BA_DEF_ SG_  "GenSigILSupport" ENUM  "No","Yes";
BA_DEF_ SG_  "SPN" INT 0 524287;
BA_DEF_ BO_  "J1939CPgSendTimeout" INT -1 3600000;
BA_DEF_ BO_  "J1939CPgTOS" INT 0 7;
BA_DEF_ BO_  "J1939PgAppearanceOnBus" ENUM  "Default","CAN_Extended","CANFD_Extended";
BA_DEF_ BO_  "FsJ1939UseCrcAndCounter" STRING ;
BA_DEF_ BO_  "TpJ1939VarDlc" ENUM  "No","Yes";
BA_DEF_ BO_  "GenMsgNrOfRepetition" INT 0 1000000;
BA_DEF_ BO_  "GenMsgCycleTimeFast" INT 0 3600000;
BA_DEF_ BO_  "GenMsgFastOnStart" INT 0 100000;
BA_DEF_ BO_  "GenMsgStartDelayTime" INT 0 100000;
BA_DEF_ BO_  "GenMsgILSupport" ENUM  "No","Yes";
BA_DEF_ BO_  "GenMsgDelayTime" INT 0 1000;
BA_DEF_ BO_  "GenMsgRequestable" INT 0 1;
BA_DEF_ BO_  "GenMsgSendType" ENUM  "cyclic","NotUsed","NotUsed","NotUsed","NotUsed","NotUsed","NotUsed","IfActive","noMsgSendType";
BA_DEF_ BO_  "VFrameFormat" ENUM  "StandardCAN","ExtendedCAN","reserved","J1939PG","reserved","reserved","reserved","reserved","reserved","reserved","reserved","reserved","reserved","reserved","StandardCAN_FD","ExtendedCAN_FD";
BA_DEF_ BO_  "SingleFrame" INT 0 1;
BA_DEF_ BO_  "GenMsgCycleTime" INT 0 3600000;
BA_DEF_ SG_  "SystemSignalLongSymbol" STRING ;
BA_DEF_DEF_  "GenSigInactiveValue" 0;
BA_DEF_DEF_  "SigType" "Default";
BA_DEF_DEF_  "GenSigStartValue" 0;
BA_DEF_DEF_  "GenSigSendType" "NoSigSendType";
BA_DEF_DEF_  "GenSigILSupport" "Yes";
BA_DEF_DEF_  "SPN" 0;
BA_DEF_DEF_  "J1939CPgSendTimeout" -1;
BA_DEF_DEF_  "J1939CPgTOS" 2;
BA_DEF_DEF_  "J1939PgAppearanceOnBus" "Default";
BA_DEF_DEF_  "FsJ1939UseCrcAndCounter" "";
BA_DEF_DEF_  "TpJ1939VarDlc" "No";
BA_DEF_DEF_  "GenMsgNrOfRepetition" 0;
BA_DEF_DEF_  "GenMsgCycleTimeFast" 0;
BA_DEF_DEF_  "GenMsgFastOnStart" 0;
BA_DEF_DEF_  "GenMsgStartDelayTime" 0;
BA_DEF_DEF_  "GenMsgILSupport" "Yes";
BA_DEF_DEF_  "GenMsgDelayTime" 0;
BA_DEF_DEF_  "GenMsgRequestable" 1;
BA_DEF_DEF_  "GenMsgSendType" "noMsgSendType";
BA_DEF_DEF_  "VFrameFormat" "J1939PG";
BA_DEF_DEF_  "SingleFrame" 1;
BA_DEF_DEF_  "GenMsgCycleTime" 0;
BA_DEF_DEF_  "SystemSignalLongSymbol" "";
BA_ "FsJ1939UseCrcAndCounter" BO_ 2364663806 "Aa";
BA_ "GenMsgSendType" BO_ 2364663806 0;
BA_ "GenMsgCycleTime" BO_ 2364663806 100;
BA_ "GenMsgSendType" BO_ 2364663550 0;
BA_ "GenMsgCycleTime" BO_ 2364663550 100;
BA_ "GenMsgSendType" BO_ 2364663294 0;
BA_ "GenMsgCycleTime" BO_ 2364663294 100;
BA_ "GenMsgSendType" BO_ 2364663038 0;
BA_ "GenMsgCycleTime" BO_ 2364663038 100;
BA_ "GenMsgSendType" BO_ 2364662782 0;
BA_ "GenMsgCycleTime" BO_ 2364662782 100;
BA_ "FsJ1939UseCrcAndCounter" BO_ 2364662526 "Aa";
BA_ "GenMsgDelayTime" BO_ 2364662526 20;
BA_ "GenMsgSendType" BO_ 2364662526 0;
BA_ "GenMsgCycleTime" BO_ 2364662526 100;
BA_ "GenMsgSendType" BO_ 2364662270 0;
BA_ "GenMsgCycleTime" BO_ 2364662270 100;
BA_ "GenMsgSendType" BO_ 2364662014 0;
BA_ "GenMsgCycleTime" BO_ 2364662014 20;
BA_ "GenMsgSendType" BO_ 2364661758 0;
BA_ "GenMsgCycleTime" BO_ 2364661758 100;
BA_ "GenMsgSendType" BO_ 2364661502 0;
BA_ "GenMsgCycleTime" BO_ 2364661502 20;
BA_ "GenMsgSendType" BO_ 2364661246 0;
BA_ "GenMsgCycleTime" BO_ 2364661246 20;
BA_ "GenMsgSendType" BO_ 2364660990 0;
BA_ "GenMsgCycleTime" BO_ 2364660990 20;
BA_ "GenMsgSendType" BO_ 2364660734 0;
BA_ "GenMsgCycleTime" BO_ 2364660734 100;
BA_ "GenMsgSendType" BO_ 2364660478 0;
BA_ "GenMsgCycleTime" BO_ 2364660478 100;
BA_ "GenMsgSendType" BO_ 2364660222 0;
BA_ "GenMsgCycleTime" BO_ 2364660222 100;
BA_ "FsJ1939UseCrcAndCounter" BO_ 2364659966 "Aa";
BA_ "GenMsgSendType" BO_ 2364659966 0;
BA_ "GenMsgCycleTime" BO_ 2364659966 100;
BA_ "GenMsgSendType" BO_ 2364659710 0;
BA_ "GenMsgCycleTime" BO_ 2364659710 100;
BA_ "GenMsgSendType" BO_ 2364659454 0;
BA_ "GenMsgCycleTime" BO_ 2364659454 100;
BA_ "GenMsgSendType" BO_ 2364659198 0;
BA_ "GenMsgCycleTime" BO_ 2364659198 100;
BA_ "GenMsgSendType" BO_ 2364658942 0;
BA_ "GenMsgCycleTime" BO_ 2364658942 100;
BA_ "FsJ1939UseCrcAndCounter" BO_ 2364658686 "Aa";
BA_ "GenMsgDelayTime" BO_ 2364658686 20;
BA_ "GenMsgSendType" BO_ 2364658686 0;
BA_ "GenMsgCycleTime" BO_ 2364658686 100;
BA_ "GenMsgSendType" BO_ 2364658430 0;
BA_ "GenMsgCycleTime" BO_ 2364658430 100;
BA_ "GenMsgSendType" BO_ 2364658174 0;
BA_ "GenMsgCycleTime" BO_ 2364658174 20;
BA_ "GenMsgSendType" BO_ 2364657918 0;
BA_ "GenMsgCycleTime" BO_ 2364657918 100;
BA_ "GenMsgSendType" BO_ 2364657662 0;
BA_ "GenMsgCycleTime" BO_ 2364657662 20;
BA_ "GenMsgSendType" BO_ 2364657406 0;
BA_ "GenMsgCycleTime" BO_ 2364657406 20;
BA_ "GenMsgSendType" BO_ 2364657150 0;
BA_ "GenMsgCycleTime" BO_ 2364657150 20;
BA_ "GenMsgSendType" BO_ 2364656894 0;
BA_ "GenMsgCycleTime" BO_ 2364656894 100;
BA_ "GenMsgSendType" BO_ 2364656638 0;
BA_ "GenMsgCycleTime" BO_ 2364656638 100;
BA_ "GenMsgSendType" BO_ 2364656382 0;
BA_ "GenMsgCycleTime" BO_ 2364656382 100;
BA_ "FsJ1939UseCrcAndCounter" BO_ 2364656126 "Aa";
BA_ "GenMsgSendType" BO_ 2364656126 0;
BA_ "GenMsgCycleTime" BO_ 2364656126 100;
BA_ "GenMsgSendType" BO_ 2364655870 0;
BA_ "GenMsgCycleTime" BO_ 2364655870 100;
BA_ "GenMsgSendType" BO_ 2364655614 0;
BA_ "GenMsgCycleTime" BO_ 2364655614 100;
BA_ "GenMsgSendType" BO_ 2364655358 0;
BA_ "GenMsgCycleTime" BO_ 2364655358 100;
BA_ "GenMsgSendType" BO_ 2364655102 0;
BA_ "GenMsgCycleTime" BO_ 2364655102 100;
BA_ "FsJ1939UseCrcAndCounter" BO_ 2364654846 "Aa";
BA_ "GenMsgDelayTime" BO_ 2364654846 20;
BA_ "GenMsgSendType" BO_ 2364654846 0;
BA_ "GenMsgCycleTime" BO_ 2364654846 100;
BA_ "GenMsgSendType" BO_ 2364654590 0;
BA_ "GenMsgCycleTime" BO_ 2364654590 100;
BA_ "GenMsgSendType" BO_ 2364654334 0;
BA_ "GenMsgCycleTime" BO_ 2364654334 20;
BA_ "GenMsgSendType" BO_ 2364654078 0;
BA_ "GenMsgCycleTime" BO_ 2364654078 100;
BA_ "GenMsgSendType" BO_ 2364653822 0;
BA_ "GenMsgCycleTime" BO_ 2364653822 20;
BA_ "GenMsgSendType" BO_ 2364653566 0;
BA_ "GenMsgCycleTime" BO_ 2364653566 20;
BA_ "SigType" SG_ 2364663806 Data9CRC 12;
BA_ "SPN" SG_ 2364663806 Data9CRC 22991;
BA_ "SigType" SG_ 2364663806 Data9Counter 11;
BA_ "SPN" SG_ 2364663806 Data9Counter 22990;
BA_ "SigType" SG_ 2364663806 Data9EmbeddedIntegritySupport 5;
BA_ "SPN" SG_ 2364663806 Data9EmbeddedIntegritySupport 22989;
BA_ "SigType" SG_ 2364663806 HVESS6ThermalEventDetected 4;
BA_ "SPN" SG_ 2364663806 HVESS6ThermalEventDetected 21293;
BA_ "SigType" SG_ 2364663806 LowestCellTempCellNum 1;
BA_ "SPN" SG_ 2364663806 LowestCellTempCellNum 11703;
BA_ "SigType" SG_ 2364663806 LowestCellTempModuleNum 1;
BA_ "SPN" SG_ 2364663806 LowestCellTempModuleNum 11702;
BA_ "SigType" SG_ 2364663806 HighestCellTempCellNum 1;
BA_ "SPN" SG_ 2364663806 HighestCellTempCellNum 11701;
BA_ "SigType" SG_ 2364663806 HighestCellTempModuleNum 1;
BA_ "SPN" SG_ 2364663806 HighestCellTempModuleNum 11700;
BA_ "SigType" SG_ 2364663550 AvgCellV 1;
BA_ "SPN" SG_ 2364663550 AvgCellV 11699;
BA_ "SigType" SG_ 2364663550 LowestCellVCellNum 1;
BA_ "SPN" SG_ 2364663550 LowestCellVCellNum 11698;
BA_ "SigType" SG_ 2364663550 LowestCellVModuleNum 1;
BA_ "SPN" SG_ 2364663550 LowestCellVModuleNum 11697;
BA_ "SigType" SG_ 2364663550 HighestCellVCellNum 1;
BA_ "SPN" SG_ 2364663550 HighestCellVCellNum 11696;
BA_ "SigType" SG_ 2364663550 HighestCellVModuleNum 1;
BA_ "SPN" SG_ 2364663550 HighestCellVModuleNum 11695;
BA_ "SigType" SG_ 2364663294 TMSCoolantLvl 4;
BA_ "SPN" SG_ 2364663294 TMSCoolantLvl 12903;
BA_ "SPN" SG_ 2364663294 TMSMode 11694;
BA_ "SigType" SG_ 2364663294 TMSHVILStatus 4;
BA_ "SPN" SG_ 2364663294 TMSHVILStatus 12814;
BA_ "SigType" SG_ 2364663294 TMSHtrStatus 5;
BA_ "SPN" SG_ 2364663294 TMSHtrStatus 11693;
BA_ "SigType" SG_ 2364663294 TMSRelHumidty 1;
BA_ "SPN" SG_ 2364663294 TMSRelHumidty 11692;
BA_ "SigType" SG_ 2364663294 TMSCompressorSpd 1;
BA_ "SPN" SG_ 2364663294 TMSCompressorSpd 11691;
BA_ "SigType" SG_ 2364663294 TMSHVInputPwr 1;
BA_ "SPN" SG_ 2364663294 TMSHVInputPwr 11690;
BA_ "SigType" SG_ 2364663294 TMSSLIInputPwr 1;
BA_ "SPN" SG_ 2364663294 TMSSLIInputPwr 11689;
BA_ "SigType" SG_ 2364663038 Module32OperationalStatus 5;
BA_ "SPN" SG_ 2364663038 Module32OperationalStatus 14720;
BA_ "SigType" SG_ 2364663038 Module31OperationalStatus 5;
BA_ "SPN" SG_ 2364663038 Module31OperationalStatus 14719;
BA_ "SigType" SG_ 2364663038 Module30OperationalStatus 5;
BA_ "SPN" SG_ 2364663038 Module30OperationalStatus 14718;
BA_ "SigType" SG_ 2364663038 Module29OperationalStatus 5;
BA_ "SPN" SG_ 2364663038 Module29OperationalStatus 14717;
BA_ "SigType" SG_ 2364663038 Module28OperationalStatus 5;
BA_ "SPN" SG_ 2364663038 Module28OperationalStatus 14716;
BA_ "SigType" SG_ 2364663038 Module27OperationalStatus 5;
BA_ "SPN" SG_ 2364663038 Module27OperationalStatus 14715;
BA_ "SigType" SG_ 2364663038 Module26OperationalStatus 5;
BA_ "SPN" SG_ 2364663038 Module26OperationalStatus 14714;
BA_ "SigType" SG_ 2364663038 Module25OperationalStatus 5;
BA_ "SPN" SG_ 2364663038 Module25OperationalStatus 14713;
BA_ "SigType" SG_ 2364663038 Module24OperationalStatus 5;
BA_ "SPN" SG_ 2364663038 Module24OperationalStatus 14712;
BA_ "SigType" SG_ 2364663038 Module23OperationalStatus 5;
BA_ "SPN" SG_ 2364663038 Module23OperationalStatus 14711;
BA_ "SigType" SG_ 2364663038 Module22OperationalStatus 5;
BA_ "SPN" SG_ 2364663038 Module22OperationalStatus 14710;
BA_ "SigType" SG_ 2364663038 Module21OperationalStatus 5;
BA_ "SPN" SG_ 2364663038 Module21OperationalStatus 14709;
BA_ "SigType" SG_ 2364663038 Module20OperationalStatus 5;
BA_ "SPN" SG_ 2364663038 Module20OperationalStatus 14708;
BA_ "SigType" SG_ 2364663038 Module19OperationalStatus 5;
BA_ "SPN" SG_ 2364663038 Module19OperationalStatus 14707;
BA_ "SigType" SG_ 2364663038 Module18OperationalStatus 5;
BA_ "SPN" SG_ 2364663038 Module18OperationalStatus 14706;
BA_ "SigType" SG_ 2364663038 Module17OperationalStatus 5;
BA_ "SPN" SG_ 2364663038 Module17OperationalStatus 14705;
BA_ "SigType" SG_ 2364663038 Module16OperationalStatus 5;
BA_ "SPN" SG_ 2364663038 Module16OperationalStatus 11688;
BA_ "SigType" SG_ 2364663038 Module15OperationalStatus 5;
BA_ "SPN" SG_ 2364663038 Module15OperationalStatus 11687;
BA_ "SigType" SG_ 2364663038 Module14OperationalStatus 5;
BA_ "SPN" SG_ 2364663038 Module14OperationalStatus 11686;
BA_ "SigType" SG_ 2364663038 Module13OperationalStatus 5;
BA_ "SPN" SG_ 2364663038 Module13OperationalStatus 11685;
BA_ "SigType" SG_ 2364663038 Module12OperationalStatus 5;
BA_ "SPN" SG_ 2364663038 Module12OperationalStatus 11684;
BA_ "SigType" SG_ 2364663038 Module11OperationalStatus 5;
BA_ "SPN" SG_ 2364663038 Module11OperationalStatus 11683;
BA_ "SigType" SG_ 2364663038 Module10OperationalStatus 5;
BA_ "SPN" SG_ 2364663038 Module10OperationalStatus 11682;
BA_ "SigType" SG_ 2364663038 Module9OperationalStatus 5;
BA_ "SPN" SG_ 2364663038 Module9OperationalStatus 11681;
BA_ "SigType" SG_ 2364663038 Module8OperationalStatus 5;
BA_ "SPN" SG_ 2364663038 Module8OperationalStatus 11680;
BA_ "SigType" SG_ 2364663038 Module7OperationalStatus 5;
BA_ "SPN" SG_ 2364663038 Module7OperationalStatus 11679;
BA_ "SigType" SG_ 2364663038 Module6OperationalStatus 5;
BA_ "SPN" SG_ 2364663038 Module6OperationalStatus 11678;
BA_ "SigType" SG_ 2364663038 Module5OperationalStatus 5;
BA_ "SPN" SG_ 2364663038 Module5OperationalStatus 11677;
BA_ "SigType" SG_ 2364663038 Module4OperationalStatus 5;
BA_ "SPN" SG_ 2364663038 Module4OperationalStatus 11676;
BA_ "SigType" SG_ 2364663038 Module3OperationalStatus 5;
BA_ "SPN" SG_ 2364663038 Module3OperationalStatus 11675;
BA_ "SigType" SG_ 2364663038 Module2OperationalStatus 5;
BA_ "SPN" SG_ 2364663038 Module2OperationalStatus 11674;
BA_ "SigType" SG_ 2364663038 Module1OperationalStatus 5;
BA_ "SPN" SG_ 2364663038 Module1OperationalStatus 11673;
BA_ "SigType" SG_ 2364662782 MaxChargeVLmt 1;
BA_ "SPN" SG_ 2364662782 MaxChargeVLmt 11672;
BA_ "SPN" SG_ 2364662782 ChargeEnergyCapacity 11671;
BA_ "SPN" SG_ 2364662782 DisEnergyCapacity 11670;
BA_ "SigType" SG_ 2364662526 Status1CRC 12;
BA_ "SPN" SG_ 2364662526 Status1CRC 13026;
BA_ "SigType" SG_ 2364662526 Status1Counter 11;
BA_ "SPN" SG_ 2364662526 Status1Counter 13025;
BA_ "SPN" SG_ 2364662526 OperationalStatus 11669;
BA_ "SPN" SG_ 2364662526 HVBusConnectionStatus 11668;
BA_ "SigType" SG_ 2364662526 InternalChargerStatus 5;
BA_ "SPN" SG_ 2364662526 InternalChargerStatus 11667;
BA_ "SigType" SG_ 2364662526 CellBalancingActive 4;
BA_ "SPN" SG_ 2364662526 CellBalancingActive 11666;
BA_ "SigType" SG_ 2364662526 CellBalanceStatus 4;
BA_ "SPN" SG_ 2364662526 CellBalanceStatus 11665;
BA_ "SPN" SG_ 2364662526 StOfChargeStatus 11664;
BA_ "SigType" SG_ 2364662526 InertiaSwStatus 4;
BA_ "SPN" SG_ 2364662526 InertiaSwStatus 11663;
BA_ "SigType" SG_ 2364662526 HVILStatus 4;
BA_ "SPN" SG_ 2364662526 HVILStatus 11662;
BA_ "SPN" SG_ 2364662526 HVBusPassiveIsolTestStatus 11661;
BA_ "SPN" SG_ 2364662526 HVBusActiveIsolTestStatus 11660;
BA_ "SigType" SG_ 2364662526 CenterOfPackContactorSt 4;
BA_ "SPN" SG_ 2364662526 CenterOfPackContactorSt 11659;
BA_ "SigType" SG_ 2364662526 HVBusPreChargeRelaySt 4;
BA_ "SPN" SG_ 2364662526 HVBusPreChargeRelaySt 11658;
BA_ "SPN" SG_ 2364662526 HVBusDisconnectForewarning 11657;
BA_ "SigType" SG_ 2364662526 HVBusContactorSt11656 4;
BA_ "SPN" SG_ 2364662526 HVBusContactorSt11656 11656;
BA_ "SigType" SG_ 2364662526 HVBusContactorSt 4;
BA_ "SPN" SG_ 2364662526 HVBusContactorSt 11655;
BA_ "SigType" SG_ 2364662270 Temp 1;
BA_ "SPN" SG_ 2364662270 Temp 11654;
BA_ "SigType" SG_ 2364662270 ETemp 1;
BA_ "SPN" SG_ 2364662270 ETemp 11653;
BA_ "SigType" SG_ 2364662270 OutCoolantTemp 1;
BA_ "SPN" SG_ 2364662270 OutCoolantTemp 11652;
BA_ "SigType" SG_ 2364662270 InCoolantTemp 1;
BA_ "SPN" SG_ 2364662270 InCoolantTemp 11651;
BA_ "SigType" SG_ 2364662270 IgntV 1;
BA_ "SPN" SG_ 2364662270 IgntV 11650;
BA_ "SigType" SG_ 2364662270 BusV 1;
BA_ "SPN" SG_ 2364662270 BusV 11649;
BA_ "SigType" SG_ 2364662014 HighestCellStOfCharge 1;
BA_ "SPN" SG_ 2364662014 HighestCellStOfCharge 11648;
BA_ "SigType" SG_ 2364662014 LowestCellStOfCharge 1;
BA_ "SPN" SG_ 2364662014 LowestCellStOfCharge 11647;
BA_ "SigType" SG_ 2364662014 ChargeCurLmt 1;
BA_ "GenSigStartValue" SG_ 2364662014 ChargeCurLmt 32000;
BA_ "SPN" SG_ 2364662014 ChargeCurLmt 11646;
BA_ "SigType" SG_ 2364662014 DisCurLmt 1;
BA_ "SPN" SG_ 2364662014 DisCurLmt 11645;
BA_ "SigType" SG_ 2364661758 CellBalancingCount 1;
BA_ "SPN" SG_ 2364661758 CellBalancingCount 11644;
BA_ "SigType" SG_ 2364661758 ChargeCapacity 1;
BA_ "SPN" SG_ 2364661758 ChargeCapacity 11643;
BA_ "SigType" SG_ 2364661758 DisCapacity 1;
BA_ "SPN" SG_ 2364661758 DisCapacity 11642;
BA_ "SigType" SG_ 2364661502 CellTempDiffStatus 4;
BA_ "SPN" SG_ 2364661502 CellTempDiffStatus 11641;
BA_ "SigType" SG_ 2364661502 AvgCellTemp 1;
BA_ "SPN" SG_ 2364661502 AvgCellTemp 11640;
BA_ "SigType" SG_ 2364661502 LowestCellTemp 1;
BA_ "SPN" SG_ 2364661502 LowestCellTemp 11639;
BA_ "SigType" SG_ 2364661502 HighestCellTemp 1;
BA_ "SPN" SG_ 2364661502 HighestCellTemp 11638;
BA_ "SPN" SG_ 2364661246 CellVDiffStatus 11637;
BA_ "SigType" SG_ 2364661246 LowestCellV 1;
BA_ "SPN" SG_ 2364661246 LowestCellV 11636;
BA_ "SigType" SG_ 2364661246 HighestCellV 1;
BA_ "SPN" SG_ 2364661246 HighestCellV 11635;
BA_ "SigType" SG_ 2364661246 FastUpdateStOfCharge 1;
BA_ "SPN" SG_ 2364661246 FastUpdateStOfCharge 11634;
BA_ "SigType" SG_ 2364660990 Cur 1;
BA_ "SPN" SG_ 2364660990 Cur 11633;
BA_ "SigType" SG_ 2364660990 Lvl 1;
BA_ "SPN" SG_ 2364660990 Lvl 11632;
BA_ "SigType" SG_ 2364660990 AvailableChargePwr 1;
BA_ "SPN" SG_ 2364660990 AvailableChargePwr 11631;
BA_ "SigType" SG_ 2364660990 AvailableDisPwr 1;
BA_ "SPN" SG_ 2364660990 AvailableDisPwr 11630;
BA_ "SigType" SG_ 2364660734 ChargePLDueToAnUndefinedCause 4;
BA_ "SPN" SG_ 2364660734 ChargePLDueToAnUndefinedCause 11629;
BA_ "SigType" SG_ 2364660734 ChargePLDueToBatCur 4;
BA_ "SPN" SG_ 2364660734 ChargePLDueToBatCur 11628;
BA_ "SigType" SG_ 2364660734 ChargePLDueToBatOrCellV 4;
BA_ "SPN" SG_ 2364660734 ChargePLDueToBatOrCellV 11627;
BA_ "SigType" SG_ 2364660734 ChargePLDueToBatDiagCondition 4;
BA_ "SPN" SG_ 2364660734 ChargePLDueToBatDiagCondition 11626;
BA_ "SigType" SG_ 2364660734 ChargePLDueToBatTemp 4;
BA_ "SPN" SG_ 2364660734 ChargePLDueToBatTemp 11625;
BA_ "SigType" SG_ 2364660734 ChargePLDueToStOfCharge 4;
BA_ "SPN" SG_ 2364660734 ChargePLDueToStOfCharge 11624;
BA_ "SigType" SG_ 2364660734 DisPLDueToAnUndefinedCause 4;
BA_ "SPN" SG_ 2364660734 DisPLDueToAnUndefinedCause 11623;
BA_ "SigType" SG_ 2364660734 DisPLDueToBatCur 4;
BA_ "SPN" SG_ 2364660734 DisPLDueToBatCur 11622;
BA_ "SigType" SG_ 2364660734 DisPLDueToBatOrCellV 4;
BA_ "SPN" SG_ 2364660734 DisPLDueToBatOrCellV 11621;
BA_ "SigType" SG_ 2364660734 DisPLDueToBatDiagCondition 4;
BA_ "SPN" SG_ 2364660734 DisPLDueToBatDiagCondition 11620;
BA_ "SigType" SG_ 2364660734 DisPLDueToBatTemp 4;
BA_ "SPN" SG_ 2364660734 DisPLDueToBatTemp 11619;
BA_ "SigType" SG_ 2364660734 DisPLDueToStOfCharge 4;
BA_ "SPN" SG_ 2364660734 DisPLDueToStOfCharge 11618;
BA_ "SigType" SG_ 2364660478 ActualChargeRate 1;
BA_ "SPN" SG_ 2364660478 ActualChargeRate 13069;
BA_ "SigType" SG_ 2364660478 LvlNegToChassisGroundV 1;
BA_ "SPN" SG_ 2364660478 LvlNegToChassisGroundV 11595;
BA_ "SigType" SG_ 2364660478 BusVNegToChassisGroundV 1;
BA_ "SPN" SG_ 2364660478 BusVNegToChassisGroundV 11594;
BA_ "SigType" SG_ 2364660222 HVBusPassiveIsolTestResults 1;
BA_ "SPN" SG_ 2364660222 HVBusPassiveIsolTestResults 11593;
BA_ "SigType" SG_ 2364660222 HVBusActiveIsolTestResults 1;
BA_ "SPN" SG_ 2364660222 HVBusActiveIsolTestResults 11592;
BA_ "SigType" SG_ 2364660222 LowestCellStOfChargeCellNum 1;
BA_ "SPN" SG_ 2364660222 LowestCellStOfChargeCellNum 11591;
BA_ "SigType" SG_ 2364660222 LowestCellStOfChargeModuleNum 1;
BA_ "SPN" SG_ 2364660222 LowestCellStOfChargeModuleNum 11590;
BA_ "SigType" SG_ 2364660222 HighestCellStOfChargeCellNum 1;
BA_ "SPN" SG_ 2364660222 HighestCellStOfChargeCellNum 11589;
BA_ "SigType" SG_ 2364660222 HighestCellStOfChargeModuleNum 1;
BA_ "SPN" SG_ 2364660222 HighestCellStOfChargeModuleNum 11588;
BA_ "SigType" SG_ 2364659966 Data9CRC 12;
BA_ "SPN" SG_ 2364659966 Data9CRC 22988;
BA_ "SigType" SG_ 2364659966 Data9Counter 11;
BA_ "SPN" SG_ 2364659966 Data9Counter 22987;
BA_ "SigType" SG_ 2364659966 Data9EmbeddedIntegritySupport 5;
BA_ "SPN" SG_ 2364659966 Data9EmbeddedIntegritySupport 22986;
BA_ "SigType" SG_ 2364659966 HVESS5ThermalEventDetected 4;
BA_ "SPN" SG_ 2364659966 HVESS5ThermalEventDetected 21292;
BA_ "SigType" SG_ 2364659966 LowestCellTempCellNum 1;
BA_ "SPN" SG_ 2364659966 LowestCellTempCellNum 11587;
BA_ "SigType" SG_ 2364659966 LowestCellTempModuleNum 1;
BA_ "SPN" SG_ 2364659966 LowestCellTempModuleNum 11586;
BA_ "SigType" SG_ 2364659966 HighestCellTempCellNum 1;
BA_ "SPN" SG_ 2364659966 HighestCellTempCellNum 11585;
BA_ "SigType" SG_ 2364659966 HighestCellTempModuleNum 1;
BA_ "SPN" SG_ 2364659966 HighestCellTempModuleNum 11584;
BA_ "SigType" SG_ 2364659710 AvgCellV 1;
BA_ "SPN" SG_ 2364659710 AvgCellV 11583;
BA_ "SigType" SG_ 2364659710 LowestCellVCellNum 1;
BA_ "SPN" SG_ 2364659710 LowestCellVCellNum 11582;
BA_ "SigType" SG_ 2364659710 LowestCellVModuleNum 1;
BA_ "SPN" SG_ 2364659710 LowestCellVModuleNum 11581;
BA_ "SigType" SG_ 2364659710 HighestCellVCellNum 1;
BA_ "SPN" SG_ 2364659710 HighestCellVCellNum 11580;
BA_ "SigType" SG_ 2364659710 HighestCellVModuleNum 1;
BA_ "SPN" SG_ 2364659710 HighestCellVModuleNum 11579;
BA_ "SigType" SG_ 2364659454 TMSCoolantLvl 4;
BA_ "SPN" SG_ 2364659454 TMSCoolantLvl 12902;
BA_ "SPN" SG_ 2364659454 TMSMode 11578;
BA_ "SigType" SG_ 2364659454 TMSHVILStatus 4;
BA_ "SPN" SG_ 2364659454 TMSHVILStatus 12815;
BA_ "SigType" SG_ 2364659454 TMSHtrStatus 5;
BA_ "SPN" SG_ 2364659454 TMSHtrStatus 11577;
BA_ "SigType" SG_ 2364659454 TMSRelHumidty 1;
BA_ "SPN" SG_ 2364659454 TMSRelHumidty 11576;
BA_ "SigType" SG_ 2364659454 TMSCompressorSpd 1;
BA_ "SPN" SG_ 2364659454 TMSCompressorSpd 11575;
BA_ "SigType" SG_ 2364659454 TMSHVInputPwr 1;
BA_ "SPN" SG_ 2364659454 TMSHVInputPwr 11574;
BA_ "SigType" SG_ 2364659454 TMSSLIInputPwr 1;
BA_ "SPN" SG_ 2364659454 TMSSLIInputPwr 11573;
BA_ "SigType" SG_ 2364659198 Module32OperationalStatus 5;
BA_ "SPN" SG_ 2364659198 Module32OperationalStatus 14704;
BA_ "SigType" SG_ 2364659198 Module31OperationalStatus 5;
BA_ "SPN" SG_ 2364659198 Module31OperationalStatus 14703;
BA_ "SigType" SG_ 2364659198 Module30OperationalStatus 5;
BA_ "SPN" SG_ 2364659198 Module30OperationalStatus 14702;
BA_ "SigType" SG_ 2364659198 Module29OperationalStatus 5;
BA_ "SPN" SG_ 2364659198 Module29OperationalStatus 14701;
BA_ "SigType" SG_ 2364659198 Module28OperationalStatus 5;
BA_ "SPN" SG_ 2364659198 Module28OperationalStatus 14700;
BA_ "SigType" SG_ 2364659198 Module27OperationalStatus 5;
BA_ "SPN" SG_ 2364659198 Module27OperationalStatus 14699;
BA_ "SigType" SG_ 2364659198 Module26OperationalStatus 5;
BA_ "SPN" SG_ 2364659198 Module26OperationalStatus 14698;
BA_ "SigType" SG_ 2364659198 Module25OperationalStatus 5;
BA_ "SPN" SG_ 2364659198 Module25OperationalStatus 14697;
BA_ "SigType" SG_ 2364659198 Module24OperationalStatus 5;
BA_ "SPN" SG_ 2364659198 Module24OperationalStatus 14696;
BA_ "SigType" SG_ 2364659198 Module23OperationalStatus 5;
BA_ "SPN" SG_ 2364659198 Module23OperationalStatus 14695;
BA_ "SigType" SG_ 2364659198 Module22OperationalStatus 5;
BA_ "SPN" SG_ 2364659198 Module22OperationalStatus 14694;
BA_ "SigType" SG_ 2364659198 Module21OperationalStatus 5;
BA_ "SPN" SG_ 2364659198 Module21OperationalStatus 14693;
BA_ "SigType" SG_ 2364659198 Module20OperationalStatus 5;
BA_ "SPN" SG_ 2364659198 Module20OperationalStatus 14692;
BA_ "SigType" SG_ 2364659198 Module19OperationalStatus 5;
BA_ "SPN" SG_ 2364659198 Module19OperationalStatus 14691;
BA_ "SigType" SG_ 2364659198 Module18OperationalStatus 5;
BA_ "SPN" SG_ 2364659198 Module18OperationalStatus 14690;
BA_ "SigType" SG_ 2364659198 Module17OperationalStatus 5;
BA_ "SPN" SG_ 2364659198 Module17OperationalStatus 14689;
BA_ "SigType" SG_ 2364659198 Module16OperationalStatus 5;
BA_ "SPN" SG_ 2364659198 Module16OperationalStatus 11572;
BA_ "SigType" SG_ 2364659198 Module15OperationalStatus 5;
BA_ "SPN" SG_ 2364659198 Module15OperationalStatus 11571;
BA_ "SigType" SG_ 2364659198 Module14OperationalStatus 5;
BA_ "SPN" SG_ 2364659198 Module14OperationalStatus 11570;
BA_ "SigType" SG_ 2364659198 Module13OperationalStatus 5;
BA_ "SPN" SG_ 2364659198 Module13OperationalStatus 11569;
BA_ "SigType" SG_ 2364659198 Module12OperationalStatus 5;
BA_ "SPN" SG_ 2364659198 Module12OperationalStatus 11568;
BA_ "SigType" SG_ 2364659198 Module11OperationalStatus 5;
BA_ "SPN" SG_ 2364659198 Module11OperationalStatus 11567;
BA_ "SigType" SG_ 2364659198 Module10OperationalStatus 5;
BA_ "SPN" SG_ 2364659198 Module10OperationalStatus 11566;
BA_ "SigType" SG_ 2364659198 Module9OperationalStatus 5;
BA_ "SPN" SG_ 2364659198 Module9OperationalStatus 11565;
BA_ "SigType" SG_ 2364659198 Module8OperationalStatus 5;
BA_ "SPN" SG_ 2364659198 Module8OperationalStatus 11564;
BA_ "SigType" SG_ 2364659198 Module7OperationalStatus 5;
BA_ "SPN" SG_ 2364659198 Module7OperationalStatus 11563;
BA_ "SigType" SG_ 2364659198 Module6OperationalStatus 5;
BA_ "SPN" SG_ 2364659198 Module6OperationalStatus 11562;
BA_ "SigType" SG_ 2364659198 Module5OperationalStatus 5;
BA_ "SPN" SG_ 2364659198 Module5OperationalStatus 11561;
BA_ "SigType" SG_ 2364659198 Module4OperationalStatus 5;
BA_ "SPN" SG_ 2364659198 Module4OperationalStatus 11560;
BA_ "SigType" SG_ 2364659198 Module3OperationalStatus 5;
BA_ "SPN" SG_ 2364659198 Module3OperationalStatus 11559;
BA_ "SigType" SG_ 2364659198 Module2OperationalStatus 5;
BA_ "SPN" SG_ 2364659198 Module2OperationalStatus 11558;
BA_ "SigType" SG_ 2364659198 Module1OperationalStatus 5;
BA_ "SPN" SG_ 2364659198 Module1OperationalStatus 11557;
BA_ "SigType" SG_ 2364658942 MaxChargeVLmt 1;
BA_ "SPN" SG_ 2364658942 MaxChargeVLmt 11556;
BA_ "SPN" SG_ 2364658942 ChargeEnergyCapacity 11555;
BA_ "SPN" SG_ 2364658942 DisEnergyCapacity 11554;
BA_ "SigType" SG_ 2364658686 Status1CRC 12;
BA_ "SPN" SG_ 2364658686 Status1CRC 13024;
BA_ "SigType" SG_ 2364658686 Status1Counter 11;
BA_ "SPN" SG_ 2364658686 Status1Counter 13023;
BA_ "SPN" SG_ 2364658686 OperationalStatus 11553;
BA_ "SPN" SG_ 2364658686 HVBusConnectionStatus 11552;
BA_ "SigType" SG_ 2364658686 InternalChargerStatus 5;
BA_ "SPN" SG_ 2364658686 InternalChargerStatus 11551;
BA_ "SigType" SG_ 2364658686 CellBalancingActive 4;
BA_ "SPN" SG_ 2364658686 CellBalancingActive 11550;
BA_ "SigType" SG_ 2364658686 CellBalanceStatus 4;
BA_ "SPN" SG_ 2364658686 CellBalanceStatus 11549;
BA_ "SPN" SG_ 2364658686 StOfChargeStatus 11548;
BA_ "SigType" SG_ 2364658686 InertiaSwStatus 4;
BA_ "SPN" SG_ 2364658686 InertiaSwStatus 11547;
BA_ "SigType" SG_ 2364658686 HVILStatus 4;
BA_ "SPN" SG_ 2364658686 HVILStatus 11546;
BA_ "SPN" SG_ 2364658686 HVBusPassiveIsolTestStatus 11545;
BA_ "SPN" SG_ 2364658686 HVBusActiveIsolTestStatus 11544;
BA_ "SigType" SG_ 2364658686 CenterOfPackContactorSt 4;
BA_ "SPN" SG_ 2364658686 CenterOfPackContactorSt 11543;
BA_ "SigType" SG_ 2364658686 HVBusPreChargeRelaySt 4;
BA_ "SPN" SG_ 2364658686 HVBusPreChargeRelaySt 11542;
BA_ "SPN" SG_ 2364658686 HVBusDisconnectForewarning 11541;
BA_ "SigType" SG_ 2364658686 HVBusContactorSt11540 4;
BA_ "SPN" SG_ 2364658686 HVBusContactorSt11540 11540;
BA_ "SigType" SG_ 2364658686 HVBusContactorSt 4;
BA_ "SPN" SG_ 2364658686 HVBusContactorSt 11539;
BA_ "SigType" SG_ 2364658430 Temp 1;
BA_ "SPN" SG_ 2364658430 Temp 11538;
BA_ "SigType" SG_ 2364658430 ETemp 1;
BA_ "SPN" SG_ 2364658430 ETemp 11537;
BA_ "SigType" SG_ 2364658430 OutCoolantTemp 1;
BA_ "SPN" SG_ 2364658430 OutCoolantTemp 11536;
BA_ "SigType" SG_ 2364658430 InCoolantTemp 1;
BA_ "SPN" SG_ 2364658430 InCoolantTemp 11535;
BA_ "SigType" SG_ 2364658430 IgntV 1;
BA_ "SPN" SG_ 2364658430 IgntV 11534;
BA_ "SigType" SG_ 2364658430 BusV 1;
BA_ "SPN" SG_ 2364658430 BusV 11533;
BA_ "SigType" SG_ 2364658174 HighestCellStOfCharge 1;
BA_ "SPN" SG_ 2364658174 HighestCellStOfCharge 11532;
BA_ "SigType" SG_ 2364658174 LowestCellStOfCharge 1;
BA_ "SPN" SG_ 2364658174 LowestCellStOfCharge 11531;
BA_ "SigType" SG_ 2364658174 ChargeCurLmt 1;
BA_ "GenSigStartValue" SG_ 2364658174 ChargeCurLmt 32000;
BA_ "SPN" SG_ 2364658174 ChargeCurLmt 11530;
BA_ "SigType" SG_ 2364658174 DisCurLmt 1;
BA_ "SPN" SG_ 2364658174 DisCurLmt 11529;
BA_ "SigType" SG_ 2364657918 CellBalancingCount 1;
BA_ "SPN" SG_ 2364657918 CellBalancingCount 11528;
BA_ "SigType" SG_ 2364657918 ChargeCapacity 1;
BA_ "SPN" SG_ 2364657918 ChargeCapacity 11527;
BA_ "SigType" SG_ 2364657918 DisCapacity 1;
BA_ "SPN" SG_ 2364657918 DisCapacity 11526;
BA_ "SigType" SG_ 2364657662 CellTempDiffStatus 4;
BA_ "SPN" SG_ 2364657662 CellTempDiffStatus 11525;
BA_ "SigType" SG_ 2364657662 AvgCellTemp 1;
BA_ "SPN" SG_ 2364657662 AvgCellTemp 11524;
BA_ "SigType" SG_ 2364657662 LowestCellTemp 1;
BA_ "SPN" SG_ 2364657662 LowestCellTemp 11523;
BA_ "SigType" SG_ 2364657662 HighestCellTemp 1;
BA_ "SPN" SG_ 2364657662 HighestCellTemp 11522;
BA_ "SPN" SG_ 2364657406 CellVDiffStatus 11521;
BA_ "SigType" SG_ 2364657406 LowestCellV 1;
BA_ "SPN" SG_ 2364657406 LowestCellV 11520;
BA_ "SigType" SG_ 2364657406 HighestCellV 1;
BA_ "SPN" SG_ 2364657406 HighestCellV 11519;
BA_ "SigType" SG_ 2364657406 FastUpdateStOfCharge 1;
BA_ "SPN" SG_ 2364657406 FastUpdateStOfCharge 11518;
BA_ "SigType" SG_ 2364657150 Cur 1;
BA_ "SPN" SG_ 2364657150 Cur 11517;
BA_ "SigType" SG_ 2364657150 Lvl 1;
BA_ "SPN" SG_ 2364657150 Lvl 11516;
BA_ "SigType" SG_ 2364657150 AvailableChargePwr 1;
BA_ "SPN" SG_ 2364657150 AvailableChargePwr 11515;
BA_ "SigType" SG_ 2364657150 AvailableDisPwr 1;
BA_ "SPN" SG_ 2364657150 AvailableDisPwr 11514;
BA_ "SigType" SG_ 2364656894 ChargePLDueToAnUndefinedCause 4;
BA_ "SPN" SG_ 2364656894 ChargePLDueToAnUndefinedCause 11513;
BA_ "SigType" SG_ 2364656894 ChargePLDueToBatCur 4;
BA_ "SPN" SG_ 2364656894 ChargePLDueToBatCur 11512;
BA_ "SigType" SG_ 2364656894 ChargePLDueToBatOrCellV 4;
BA_ "SPN" SG_ 2364656894 ChargePLDueToBatOrCellV 11511;
BA_ "SigType" SG_ 2364656894 ChargePLDueToBatDiagCondition 4;
BA_ "SPN" SG_ 2364656894 ChargePLDueToBatDiagCondition 11510;
BA_ "SigType" SG_ 2364656894 ChargePLDueToBatTemp 4;
BA_ "SPN" SG_ 2364656894 ChargePLDueToBatTemp 11509;
BA_ "SigType" SG_ 2364656894 ChargePLDueToStOfCharge 4;
BA_ "SPN" SG_ 2364656894 ChargePLDueToStOfCharge 11508;
BA_ "SigType" SG_ 2364656894 DisPLDueToAnUndefinedCause 4;
BA_ "SPN" SG_ 2364656894 DisPLDueToAnUndefinedCause 11507;
BA_ "SigType" SG_ 2364656894 DisPLDueToBatCur 4;
BA_ "SPN" SG_ 2364656894 DisPLDueToBatCur 11506;
BA_ "SigType" SG_ 2364656894 DisPLDueToBatOrCellV 4;
BA_ "SPN" SG_ 2364656894 DisPLDueToBatOrCellV 11505;
BA_ "SigType" SG_ 2364656894 DisPLDueToBatDiagCondition 4;
BA_ "SPN" SG_ 2364656894 DisPLDueToBatDiagCondition 11504;
BA_ "SigType" SG_ 2364656894 DisPLDueToBatTemp 4;
BA_ "SPN" SG_ 2364656894 DisPLDueToBatTemp 11503;
BA_ "SigType" SG_ 2364656894 DisPLDueToStOfCharge 4;
BA_ "SPN" SG_ 2364656894 DisPLDueToStOfCharge 11502;
BA_ "SigType" SG_ 2364656638 ActualChargeRate 1;
BA_ "SPN" SG_ 2364656638 ActualChargeRate 13068;
BA_ "SigType" SG_ 2364656638 LvlNegToChassisGroundV 1;
BA_ "SPN" SG_ 2364656638 LvlNegToChassisGroundV 11479;
BA_ "SigType" SG_ 2364656638 BusVNegToChassisGroundV 1;
BA_ "SPN" SG_ 2364656638 BusVNegToChassisGroundV 11478;
BA_ "SigType" SG_ 2364656382 HVBusPassiveIsolTestResults 1;
BA_ "SPN" SG_ 2364656382 HVBusPassiveIsolTestResults 11477;
BA_ "SigType" SG_ 2364656382 HVBusActiveIsolTestResults 1;
BA_ "SPN" SG_ 2364656382 HVBusActiveIsolTestResults 11476;
BA_ "SigType" SG_ 2364656382 LowestCellStOfChargeCellNum 1;
BA_ "SPN" SG_ 2364656382 LowestCellStOfChargeCellNum 11475;
BA_ "SigType" SG_ 2364656382 LowestCellStOfChargeModuleNum 1;
BA_ "SPN" SG_ 2364656382 LowestCellStOfChargeModuleNum 11474;
BA_ "SigType" SG_ 2364656382 HighestCellStOfChargeCellNum 1;
BA_ "SPN" SG_ 2364656382 HighestCellStOfChargeCellNum 11473;
BA_ "SigType" SG_ 2364656382 HighestCellStOfChargeModuleNum 1;
BA_ "SPN" SG_ 2364656382 HighestCellStOfChargeModuleNum 11472;
BA_ "SigType" SG_ 2364656126 Data9CRC 12;
BA_ "SPN" SG_ 2364656126 Data9CRC 22985;
BA_ "SigType" SG_ 2364656126 Data9Counter 11;
BA_ "SPN" SG_ 2364656126 Data9Counter 22984;
BA_ "SigType" SG_ 2364656126 Data9EmbeddedIntegritySupport 5;
BA_ "SPN" SG_ 2364656126 Data9EmbeddedIntegritySupport 22983;
BA_ "SigType" SG_ 2364656126 HVESS4ThermalEventDetected 4;
BA_ "SPN" SG_ 2364656126 HVESS4ThermalEventDetected 21291;
BA_ "SigType" SG_ 2364656126 LowestCellTempCellNum 1;
BA_ "SPN" SG_ 2364656126 LowestCellTempCellNum 11471;
BA_ "SigType" SG_ 2364656126 LowestCellTempModuleNum 1;
BA_ "SPN" SG_ 2364656126 LowestCellTempModuleNum 11470;
BA_ "SigType" SG_ 2364656126 HighestCellTempCellNum 1;
BA_ "SPN" SG_ 2364656126 HighestCellTempCellNum 11469;
BA_ "SigType" SG_ 2364656126 HighestCellTempModuleNum 1;
BA_ "SPN" SG_ 2364656126 HighestCellTempModuleNum 11468;
BA_ "SigType" SG_ 2364655870 AvgCellV 1;
BA_ "SPN" SG_ 2364655870 AvgCellV 11467;
BA_ "SigType" SG_ 2364655870 LowestCellVCellNum 1;
BA_ "SPN" SG_ 2364655870 LowestCellVCellNum 11466;
BA_ "SigType" SG_ 2364655870 LowestCellVModuleNum 1;
BA_ "SPN" SG_ 2364655870 LowestCellVModuleNum 11465;
BA_ "SigType" SG_ 2364655870 HighestCellVCellNum 1;
BA_ "SPN" SG_ 2364655870 HighestCellVCellNum 11464;
BA_ "SigType" SG_ 2364655870 HighestCellVModuleNum 1;
BA_ "SPN" SG_ 2364655870 HighestCellVModuleNum 11463;
BA_ "SigType" SG_ 2364655614 TMSCoolantLvl 4;
BA_ "SPN" SG_ 2364655614 TMSCoolantLvl 12901;
BA_ "SPN" SG_ 2364655614 TMSMode 11462;
BA_ "SigType" SG_ 2364655614 TMSHVILStatus 4;
BA_ "SPN" SG_ 2364655614 TMSHVILStatus 12816;
BA_ "SigType" SG_ 2364655614 TMSHtrStatus 5;
BA_ "SPN" SG_ 2364655614 TMSHtrStatus 11461;
BA_ "SigType" SG_ 2364655614 TMSRelHumidty 1;
BA_ "SPN" SG_ 2364655614 TMSRelHumidty 11460;
BA_ "SigType" SG_ 2364655614 TMSCompressorSpd 1;
BA_ "SPN" SG_ 2364655614 TMSCompressorSpd 11459;
BA_ "SigType" SG_ 2364655614 TMSHVInputPwr 1;
BA_ "SPN" SG_ 2364655614 TMSHVInputPwr 11458;
BA_ "SigType" SG_ 2364655614 TMSSLIInputPwr 1;
BA_ "SPN" SG_ 2364655614 TMSSLIInputPwr 11457;
BA_ "SigType" SG_ 2364655358 Module32OperationalStatus 5;
BA_ "SPN" SG_ 2364655358 Module32OperationalStatus 14688;
BA_ "SigType" SG_ 2364655358 Module31OperationalStatus 5;
BA_ "SPN" SG_ 2364655358 Module31OperationalStatus 14687;
BA_ "SigType" SG_ 2364655358 Module30OperationalStatus 5;
BA_ "SPN" SG_ 2364655358 Module30OperationalStatus 14686;
BA_ "SigType" SG_ 2364655358 Module29OperationalStatus 5;
BA_ "SPN" SG_ 2364655358 Module29OperationalStatus 14685;
BA_ "SigType" SG_ 2364655358 Module28OperationalStatus 5;
BA_ "SPN" SG_ 2364655358 Module28OperationalStatus 14684;
BA_ "SigType" SG_ 2364655358 Module27OperationalStatus 5;
BA_ "SPN" SG_ 2364655358 Module27OperationalStatus 14683;
BA_ "SigType" SG_ 2364655358 Module26OperationalStatus 5;
BA_ "SPN" SG_ 2364655358 Module26OperationalStatus 14682;
BA_ "SigType" SG_ 2364655358 Module25OperationalStatus 5;
BA_ "SPN" SG_ 2364655358 Module25OperationalStatus 14681;
BA_ "SigType" SG_ 2364655358 Module24OperationalStatus 5;
BA_ "SPN" SG_ 2364655358 Module24OperationalStatus 14680;
BA_ "SigType" SG_ 2364655358 Module23OperationalStatus 5;
BA_ "SPN" SG_ 2364655358 Module23OperationalStatus 14679;
BA_ "SigType" SG_ 2364655358 Module22OperationalStatus 5;
BA_ "SPN" SG_ 2364655358 Module22OperationalStatus 14678;
BA_ "SigType" SG_ 2364655358 Module21OperationalStatus 5;
BA_ "SPN" SG_ 2364655358 Module21OperationalStatus 14677;
BA_ "SigType" SG_ 2364655358 Module20OperationalStatus 5;
BA_ "SPN" SG_ 2364655358 Module20OperationalStatus 14676;
BA_ "SigType" SG_ 2364655358 Module19OperationalStatus 5;
BA_ "SPN" SG_ 2364655358 Module19OperationalStatus 14675;
BA_ "SigType" SG_ 2364655358 Module18OperationalStatus 5;
BA_ "SPN" SG_ 2364655358 Module18OperationalStatus 14674;
BA_ "SigType" SG_ 2364655358 Module17OperationalStatus 5;
BA_ "SPN" SG_ 2364655358 Module17OperationalStatus 14673;
BA_ "SigType" SG_ 2364655358 Module16OperationalStatus 5;
BA_ "SPN" SG_ 2364655358 Module16OperationalStatus 11456;
BA_ "SigType" SG_ 2364655358 Module15OperationalStatus 5;
BA_ "SPN" SG_ 2364655358 Module15OperationalStatus 11455;
BA_ "SigType" SG_ 2364655358 Module14OperationalStatus 5;
BA_ "SPN" SG_ 2364655358 Module14OperationalStatus 11454;
BA_ "SigType" SG_ 2364655358 Module13OperationalStatus 5;
BA_ "SPN" SG_ 2364655358 Module13OperationalStatus 11453;
BA_ "SigType" SG_ 2364655358 Module12OperationalStatus 5;
BA_ "SPN" SG_ 2364655358 Module12OperationalStatus 11452;
BA_ "SigType" SG_ 2364655358 Module11OperationalStatus 5;
BA_ "SPN" SG_ 2364655358 Module11OperationalStatus 11451;
BA_ "SigType" SG_ 2364655358 Module10OperationalStatus 5;
BA_ "SPN" SG_ 2364655358 Module10OperationalStatus 11450;
BA_ "SigType" SG_ 2364655358 Module9OperationalStatus 5;
BA_ "SPN" SG_ 2364655358 Module9OperationalStatus 11449;
BA_ "SigType" SG_ 2364655358 Module8OperationalStatus 5;
BA_ "SPN" SG_ 2364655358 Module8OperationalStatus 11448;
BA_ "SigType" SG_ 2364655358 Module7OperationalStatus 5;
BA_ "SPN" SG_ 2364655358 Module7OperationalStatus 11447;
BA_ "SigType" SG_ 2364655358 Module6OperationalStatus 5;
BA_ "SPN" SG_ 2364655358 Module6OperationalStatus 11446;
BA_ "SigType" SG_ 2364655358 Module5OperationalStatus 5;
BA_ "SPN" SG_ 2364655358 Module5OperationalStatus 11445;
BA_ "SigType" SG_ 2364655358 Module4OperationalStatus 5;
BA_ "SPN" SG_ 2364655358 Module4OperationalStatus 11444;
BA_ "SigType" SG_ 2364655358 Module3OperationalStatus 5;
BA_ "SPN" SG_ 2364655358 Module3OperationalStatus 11443;
BA_ "SigType" SG_ 2364655358 Module2OperationalStatus 5;
BA_ "SPN" SG_ 2364655358 Module2OperationalStatus 11442;
BA_ "SigType" SG_ 2364655358 Module1OperationalStatus 5;
BA_ "SPN" SG_ 2364655358 Module1OperationalStatus 11441;
BA_ "SigType" SG_ 2364655102 MaxChargeVLmt 1;
BA_ "SPN" SG_ 2364655102 MaxChargeVLmt 11440;
BA_ "SPN" SG_ 2364655102 ChargeEnergyCapacity 11439;
BA_ "SPN" SG_ 2364655102 DisEnergyCapacity 11438;
BA_ "SigType" SG_ 2364654846 Status1CRC 12;
BA_ "SPN" SG_ 2364654846 Status1CRC 13022;
BA_ "SigType" SG_ 2364654846 Status1Counter 11;
BA_ "SPN" SG_ 2364654846 Status1Counter 13021;
BA_ "SPN" SG_ 2364654846 OperationalStatus 11437;
BA_ "SPN" SG_ 2364654846 HVBusConnectionStatus 11436;
BA_ "SigType" SG_ 2364654846 InternalChargerStatus 5;
BA_ "SPN" SG_ 2364654846 InternalChargerStatus 11435;
BA_ "SigType" SG_ 2364654846 CellBalancingActive 4;
BA_ "SPN" SG_ 2364654846 CellBalancingActive 11434;
BA_ "SigType" SG_ 2364654846 CellBalanceStatus 4;
BA_ "SPN" SG_ 2364654846 CellBalanceStatus 11433;
BA_ "SPN" SG_ 2364654846 StOfChargeStatus 11432;
BA_ "SigType" SG_ 2364654846 InertiaSwStatus 4;
BA_ "SPN" SG_ 2364654846 InertiaSwStatus 11431;
BA_ "SigType" SG_ 2364654846 HVILStatus 4;
BA_ "SPN" SG_ 2364654846 HVILStatus 11430;
BA_ "SPN" SG_ 2364654846 HVBusPassiveIsolTestStatus 11429;
BA_ "SPN" SG_ 2364654846 HVBusActiveIsolTestStatus 11428;
BA_ "SigType" SG_ 2364654846 CenterOfPackContactorSt 4;
BA_ "SPN" SG_ 2364654846 CenterOfPackContactorSt 11427;
BA_ "SigType" SG_ 2364654846 HVBusPreChargeRelaySt 4;
BA_ "SPN" SG_ 2364654846 HVBusPreChargeRelaySt 11426;
BA_ "SPN" SG_ 2364654846 HVBusDisconnectForewarning 11425;
BA_ "SigType" SG_ 2364654846 HVBusContactorSt11424 4;
BA_ "SPN" SG_ 2364654846 HVBusContactorSt11424 11424;
BA_ "SigType" SG_ 2364654846 HVBusContactorSt 4;
BA_ "SPN" SG_ 2364654846 HVBusContactorSt 11423;
BA_ "SigType" SG_ 2364654590 Temp 1;
BA_ "SPN" SG_ 2364654590 Temp 11422;
BA_ "SigType" SG_ 2364654590 ETemp 1;
BA_ "SPN" SG_ 2364654590 ETemp 11421;
BA_ "SigType" SG_ 2364654590 OutCoolantTemp 1;
BA_ "SPN" SG_ 2364654590 OutCoolantTemp 11420;
BA_ "SigType" SG_ 2364654590 InCoolantTemp 1;
BA_ "SPN" SG_ 2364654590 InCoolantTemp 11419;
BA_ "SigType" SG_ 2364654590 IgntV 1;
BA_ "SPN" SG_ 2364654590 IgntV 11418;
BA_ "SigType" SG_ 2364654590 BusV 1;
BA_ "SPN" SG_ 2364654590 BusV 11417;
BA_ "SigType" SG_ 2364654334 HighestCellStOfCharge 1;
BA_ "SPN" SG_ 2364654334 HighestCellStOfCharge 11416;
BA_ "SigType" SG_ 2364654334 LowestCellStOfCharge 1;
BA_ "SPN" SG_ 2364654334 LowestCellStOfCharge 11415;
BA_ "SigType" SG_ 2364654334 ChargeCurLmt 1;
BA_ "GenSigStartValue" SG_ 2364654334 ChargeCurLmt 32000;
BA_ "SPN" SG_ 2364654334 ChargeCurLmt 11414;
BA_ "SigType" SG_ 2364654334 DisCurLmt 1;
BA_ "SPN" SG_ 2364654334 DisCurLmt 11413;
BA_ "SigType" SG_ 2364654078 CellBalancingCount 1;
BA_ "SPN" SG_ 2364654078 CellBalancingCount 11412;
BA_ "SigType" SG_ 2364654078 ChargeCapacity 1;
BA_ "SPN" SG_ 2364654078 ChargeCapacity 11411;
BA_ "SigType" SG_ 2364654078 DisCapacity 1;
BA_ "SPN" SG_ 2364654078 DisCapacity 11410;
BA_ "SigType" SG_ 2364653822 CellTempDiffStatus 4;
BA_ "SPN" SG_ 2364653822 CellTempDiffStatus 11409;
BA_ "SigType" SG_ 2364653822 AvgCellTemp 1;
BA_ "SPN" SG_ 2364653822 AvgCellTemp 11408;
BA_ "SigType" SG_ 2364653822 LowestCellTemp 1;
BA_ "SPN" SG_ 2364653822 LowestCellTemp 11407;
BA_ "SigType" SG_ 2364653822 HighestCellTemp 1;
BA_ "SPN" SG_ 2364653822 HighestCellTemp 11406;
BA_ "SPN" SG_ 2364653566 CellVDiffStatus 11405;
BA_ "SigType" SG_ 2364653566 LowestCellV 1;
BA_ "SPN" SG_ 2364653566 LowestCellV 11404;
BA_ "SigType" SG_ 2364653566 HighestCellV 1;
BA_ "SPN" SG_ 2364653566 HighestCellV 11403;
BA_ "SigType" SG_ 2364653566 FastUpdateStOfCharge 1;
BA_ "SPN" SG_ 2364653566 FastUpdateStOfCharge 11402;
VAL_ 2364663806 Data9EmbeddedIntegritySupport 3 "CRC and Counter are not supported by the sender" 2 "Reserved" 1 "Protection is supported using J1939-76 SHM" 0 "Embedded CRC and Counter are supported by the sender" ;
VAL_ 2364663806 HVESS6ThermalEventDetected 0 "No Thermal Event Detected" 3 "Not available" 2 "Error" 1 "Thermal Event Detected" ;
VAL_ 2364663294 TMSCoolantLvl 3 "Not Available" 2 "Error" 1 "Coolant Level is sufficient" 0 "Coolant Level is not sufficient" ;
VAL_ 2364663294 TMSMode 15 "Not Available" 14 "Faulted" 13 "Reserved" 12 "Reserved" 11 "Reserved" 10 "Reserved" 9 "Reserved" 8 "Reserved" 7 "Reserved" 6 "Reserved" 5 "Maintaining" 4 "Drying" 3 "Heating" 2 "Cooling" 1 "Circulating" 0 "Off" ;
VAL_ 2364663294 TMSHVILStatus 3 "Not Available" 2 "Error" 1 "HVIL Open" 0 "HVIL Closed" ;
VAL_ 2364663294 TMSHtrStatus 3 "Not Available" 2 "Error" 1 "Heater On" 0 "Heater Off" ;
VAL_ 2364663038 Module32OperationalStatus 3 "Not Available" 2 "Error" 1 "Operational" 0 "Not Operational" ;
VAL_ 2364663038 Module31OperationalStatus 3 "Not Available" 2 "Error" 1 "Operational" 0 "Not Operational" ;
VAL_ 2364663038 Module30OperationalStatus 3 "Not Available" 2 "Error" 1 "Operational" 0 "Not Operational" ;
VAL_ 2364663038 Module29OperationalStatus 3 "Not Available" 2 "Error" 1 "Operational" 0 "Not Operational" ;
VAL_ 2364663038 Module28OperationalStatus 3 "Not Available" 2 "Error" 1 "Operational" 0 "Not Operational" ;
VAL_ 2364663038 Module27OperationalStatus 3 "Not Available" 2 "Error" 1 "Operational" 0 "Not Operational" ;
VAL_ 2364663038 Module26OperationalStatus 3 "Not Available" 2 "Error" 1 "Operational" 0 "Not Operational" ;
VAL_ 2364663038 Module25OperationalStatus 3 "Not Available" 2 "Error" 1 "Operational" 0 "Not Operational" ;
VAL_ 2364663038 Module24OperationalStatus 3 "Not Available" 2 "Error" 1 "Operational" 0 "Not Operational" ;
VAL_ 2364663038 Module23OperationalStatus 3 "Not Available" 2 "Error" 1 "Operational" 0 "Not Operational" ;
VAL_ 2364663038 Module22OperationalStatus 3 "Not Available" 2 "Error" 1 "Operational" 0 "Not Operational" ;
VAL_ 2364663038 Module21OperationalStatus 3 "Not Available" 2 "Error" 1 "Operational" 0 "Not Operational" ;
VAL_ 2364663038 Module20OperationalStatus 3 "Not Available" 2 "Error" 1 "Operational" 0 "Not Operational" ;
VAL_ 2364663038 Module19OperationalStatus 3 "Not Available" 2 "Error" 1 "Operational" 0 "Not Operational" ;
VAL_ 2364663038 Module18OperationalStatus 3 "Not Available" 2 "Error" 1 "Operational" 0 "Not Operational" ;
VAL_ 2364663038 Module17OperationalStatus 3 "Not Available" 2 "Error" 1 "Operational" 0 "Not Operational" ;
VAL_ 2364663038 Module16OperationalStatus 3 "Not Available" 2 "Error" 1 "Operational" 0 "Not Operational" ;
VAL_ 2364663038 Module15OperationalStatus 3 "Not Available" 2 "Error" 1 "Operational" 0 "Not Operational" ;
VAL_ 2364663038 Module14OperationalStatus 3 "Not Available" 2 "Error" 1 "Operational" 0 "Not Operational" ;
VAL_ 2364663038 Module13OperationalStatus 3 "Not Available" 2 "Error" 1 "Operational" 0 "Not Operational" ;
VAL_ 2364663038 Module12OperationalStatus 3 "Not Available" 2 "Error" 1 "Operational" 0 "Not Operational" ;
VAL_ 2364663038 Module11OperationalStatus 3 "Not Available" 2 "Error" 1 "Operational" 0 "Not Operational" ;
VAL_ 2364663038 Module10OperationalStatus 3 "Not Available" 2 "Error" 1 "Operational" 0 "Not Operational" ;
VAL_ 2364663038 Module9OperationalStatus 3 "Not Available" 2 "Error" 1 "Operational" 0 "Not Operational" ;
VAL_ 2364663038 Module8OperationalStatus 3 "Not Available" 2 "Error" 1 "Operational" 0 "Not Operational" ;
VAL_ 2364663038 Module7OperationalStatus 3 "Not Available" 2 "Error" 1 "Operational" 0 "Not Operational" ;
VAL_ 2364663038 Module6OperationalStatus 3 "Not Available" 2 "Error" 1 "Operational" 0 "Not Operational" ;
VAL_ 2364663038 Module5OperationalStatus 3 "Not Available" 2 "Error" 1 "Operational" 0 "Not Operational" ;
VAL_ 2364663038 Module4OperationalStatus 3 "Not Available" 2 "Error" 1 "Operational" 0 "Not Operational" ;
VAL_ 2364663038 Module3OperationalStatus 3 "Not Available" 2 "Error" 1 "Operational" 0 "Not Operational" ;
VAL_ 2364663038 Module2OperationalStatus 3 "Not Available" 2 "Error" 1 "Operational" 0 "Not Operational" ;
VAL_ 2364663038 Module1OperationalStatus 3 "Not Available" 2 "Error" 1 "Operational" 0 "Not Operational" ;
VAL_ 2364662526 OperationalStatus 15 "Not Available" 14 "Error" 13 "Reserved" 12 "Reserved" 11 "Reserved" 10 "Reserved" 9 "Reserved" 8 "Reserved" 7 "Reserved" 6 "Disabled by internal decision of HVES controller" 5 "Disabled by external command" 4 "Emergency Power-Down In Process" 3 "Normal Power-Down in Process" 2 "Operational." 1 "Initialization Complete" 0 "Initialization in process" ;
VAL_ 2364662526 HVBusConnectionStatus 15 "Not Available" 14 "Error" 13 "Reserved" 12 "Reserved" 11 "Reserved" 10 "Reserved" 9 "Reserved" 8 "Reserved" 7 "Reserved" 6 "Reserved" 5 "Reserved" 4 "Disconnected,  Precharge Failed" 3 "Disconnection in Process" 2 "Connection in Process" 1 "Connected" 0 "Disconnected,  One or more contactors are open" ;
VAL_ 2364662526 InternalChargerStatus 3 "Not Available" 2 "Error" 1 "Charging on" 0 "Charging off" ;
VAL_ 2364662526 CellBalancingActive 3 "Not Available" 2 "Error" 1 "Cell balancing is active" 0 "Cell balancing is not active" ;
VAL_ 2364662526 CellBalanceStatus 3 "Not Available" 2 "Error" 1 "Cells are unbalanced" 0 "Cells are balanced" ;
VAL_ 2364662526 StOfChargeStatus 15 "Not  Available" 14 "Error" 13 "Reserved" 12 "Reserved" 11 "Reserved" 10 "Reserved" 9 "Reserved" 8 "Reserved" 7 "Reserved" 6 "SOC is above its recommended upper limit" 5 "SOC is at its recommended upper limit" 4 "SOC is approaching its recommended upper limit" 3 "SOC is below its recommended lower limit" 2 "SOC is at its recommended lower limit" 1 "SOC is approaching its recommended lower limit" 0 "SOC level is acceptable" ;
VAL_ 2364662526 InertiaSwStatus 3 "Not Available" 2 "Error" 1 "Impact sensed" 0 "No impact sensed" ;
VAL_ 2364662526 HVILStatus 3 "Not Available" 2 "Error" 1 "HVIL Open" 0 "HVIL Closed" ;
VAL_ 2364662526 HVBusPassiveIsolTestStatus 15 "Not available" 14 "Error" 13 "Reserved" 12 "Reserved" 11 "Reserved" 10 "Reserved" 9 "Reserved" 8 "Reserved" 7 "Reserved" 6 "Reserved" 5 "Test complete,  isolation fault" 4 "Test complete,  isolation marginal" 3 "Test complete,  isolation acceptable" 2 "Test in process" 1 "Test requested but not yet in process" 0 "No test requested / No test in process" ;
VAL_ 2364662526 HVBusActiveIsolTestStatus 15 "Not available" 14 "Error" 13 "Reserved" 12 "Reserved" 11 "Reserved" 10 "Reserved" 9 "Reserved" 8 "Reserved" 7 "Reserved" 6 "Reserved" 5 "Test complete,  isolation fault" 4 "Test complete,  isolation marginal" 3 "Test complete,  isolation acceptable" 2 "Test in process" 1 "Test requested but not yet in process" 0 "No test requested / No test in process" ;
VAL_ 2364662526 CenterOfPackContactorSt 3 "Not Available" 2 "Error" 1 "Contactor Closed" 0 "Contactor Open" ;
VAL_ 2364662526 HVBusPreChargeRelaySt 3 "Not Available" 2 "Error" 1 "Relay Closed" 0 "Relay Open" ;
VAL_ 2364662526 HVBusDisconnectForewarning 15 "Not Available" 14 "Error" 13 "Disconnect imminent" 12 "Reserved" 11 "Reserved" 10 "Reserved" 9 "Reserved" 8 "Reserved" 7 "Disconnect imminent due to battery pack current approaching maximum acceptable level" 6 "Disconnect imminent due to cell voltage approaching maximum acceptable level" 5 "Disconnect imminent due to cell voltage approaching minimum acceptable level" 4 "Disconnect imminent due to module voltage approaching maximum acceptable level" 3 "Disconnect imminent due to module voltage approaching minimum acceptable level" 2 "Disconnect imminent due to battery pack voltage approaching maximum acceptable level" 1 "Disconnect imminent due to battery pack voltage approaching minimum acceptable level" 0 "Disconnect not pending" ;
VAL_ 2364662526 HVBusContactorSt11656 3 "Not Available" 2 "Error" 1 "Contactor Closed" 0 "Contactor Open" ;
VAL_ 2364662526 HVBusContactorSt 3 "Not Available" 2 "Error" 1 "Contactor Closed" 0 "Contactor Open" ;
VAL_ 2364661502 CellTempDiffStatus 3 "Not Available" 2 "Error" 1 "Cell-to-cell temperature differential exceeds acceptable limits" 0 "Cell-to-cell temperature differential is within acceptable limits" ;
VAL_ 2364661246 CellVDiffStatus 15 "Not Available" 14 "Error" 13 "Reserved" 12 "Reserved" 11 "Reserved" 10 "Reserved" 9 "Reserved" 8 "Reserved" 7 "Reserved" 6 "Reserved" 5 "Reserved" 4 "Exceeds limits and it is not known whether balancing can restore performance" 3 "Exceeds limits and external maintenance balancing cannot restore performance" 2 "Exceeds limits and external maintenance balancing is required" 1 "Exceeds limits and can be corrected via auto-balancing" 0 "Is within acceptable limits" ;
VAL_ 2364660734 ChargePLDueToAnUndefinedCause 3 "Not Available" 2 "Error" 1 "Power limited for this reason" 0 "No power limit for this reason" ;
VAL_ 2364660734 ChargePLDueToBatCur 3 "Not Available" 2 "Error" 1 "Power limited for this reason" 0 "No power limit for this reason" ;
VAL_ 2364660734 ChargePLDueToBatOrCellV 3 "Not Available" 2 "Error" 1 "Power limited for this reason" 0 "No power limit for this reason" ;
VAL_ 2364660734 ChargePLDueToBatDiagCondition 3 "Not Available" 2 "Error" 1 "Power limited for this reason" 0 "No power limit for this reason" ;
VAL_ 2364660734 ChargePLDueToBatTemp 3 "Not Available" 2 "Error" 1 "Power limited for this reason" 0 "No power limit for this reason" ;
VAL_ 2364660734 ChargePLDueToStOfCharge 3 "Not Available" 2 "Error" 1 "Power limited for this reason" 0 "No power limit for this reason" ;
VAL_ 2364660734 DisPLDueToAnUndefinedCause 3 "Not Available" 2 "Error" 1 "Power limited for this reason" 0 "No power limit for this reason" ;
VAL_ 2364660734 DisPLDueToBatCur 3 "Not Available" 2 "Error" 1 "Power limited for this reason" 0 "No power limit for this reason" ;
VAL_ 2364660734 DisPLDueToBatOrCellV 3 "Not Available" 2 "Error" 1 "Power limited for this reason" 0 "No power limit for this reason" ;
VAL_ 2364660734 DisPLDueToBatDiagCondition 3 "Not Available" 2 "Error" 1 "Power limited for this reason" 0 "No power limit for this reason" ;
VAL_ 2364660734 DisPLDueToBatTemp 3 "Not Available" 2 "Error" 1 "Power limited for this reason" 0 "No power limit for this reason" ;
VAL_ 2364660734 DisPLDueToStOfCharge 3 "Not Available" 2 "Error" 1 "Power limited for this reason" 0 "No power limit for this reason" ;
VAL_ 2364659966 Data9EmbeddedIntegritySupport 3 "CRC and Counter are not supported by the sender" 2 "Reserved" 1 "Protection is supported using J1939-76 SHM" 0 "Embedded CRC and Counter are supported by the sender" ;
VAL_ 2364659966 HVESS5ThermalEventDetected 3 "Not available" 2 "Error" 1 "Thermal Event Detected" 0 "No Thermal Event Detected" ;
VAL_ 2364659454 TMSCoolantLvl 3 "Not Available" 2 "Error" 1 "Coolant Level is sufficient" 0 "Coolant Level is not sufficient" ;
VAL_ 2364659454 TMSMode 15 "Not Available" 14 "Faulted" 13 "Reserved" 12 "Reserved" 11 "Reserved" 10 "Reserved" 9 "Reserved" 8 "Reserved" 7 "Reserved" 6 "Reserved" 5 "Maintaining" 4 "Drying" 3 "Heating" 2 "Cooling" 1 "Circulating" 0 "Off" ;
VAL_ 2364659454 TMSHVILStatus 3 "Not Available" 2 "Error" 1 "HVIL Open" 0 "HVIL Closed" ;
VAL_ 2364659454 TMSHtrStatus 3 "Not Available" 2 "Error" 1 "Heater On" 0 "Heater Off" ;
VAL_ 2364659198 Module32OperationalStatus 3 "Not Available" 2 "Error" 1 "Operational" 0 "Not Operational" ;
VAL_ 2364659198 Module31OperationalStatus 3 "Not Available" 2 "Error" 1 "Operational" 0 "Not Operational" ;
VAL_ 2364659198 Module30OperationalStatus 3 "Not Available" 2 "Error" 1 "Operational" 0 "Not Operational" ;
VAL_ 2364659198 Module29OperationalStatus 3 "Not Available" 2 "Error" 1 "Operational" 0 "Not Operational" ;
VAL_ 2364659198 Module28OperationalStatus 3 "Not Available" 2 "Error" 1 "Operational" 0 "Not Operational" ;
VAL_ 2364659198 Module27OperationalStatus 3 "Not Available" 2 "Error" 1 "Operational" 0 "Not Operational" ;
VAL_ 2364659198 Module26OperationalStatus 3 "Not Available" 2 "Error" 1 "Operational" 0 "Not Operational" ;
VAL_ 2364659198 Module25OperationalStatus 3 "Not Available" 2 "Error" 1 "Operational" 0 "Not Operational" ;
VAL_ 2364659198 Module24OperationalStatus 3 "Not Available" 2 "Error" 1 "Operational" 0 "Not Operational" ;
VAL_ 2364659198 Module23OperationalStatus 3 "Not Available" 2 "Error" 1 "Operational" 0 "Not Operational" ;
VAL_ 2364659198 Module22OperationalStatus 3 "Not Available" 2 "Error" 1 "Operational" 0 "Not Operational" ;
VAL_ 2364659198 Module21OperationalStatus 3 "Not Available" 2 "Error" 1 "Operational" 0 "Not Operational" ;
VAL_ 2364659198 Module20OperationalStatus 3 "Not Available" 2 "Error" 1 "Operational" 0 "Not Operational" ;
VAL_ 2364659198 Module19OperationalStatus 3 "Not Available" 2 "Error" 1 "Operational" 0 "Not Operational" ;
VAL_ 2364659198 Module18OperationalStatus 3 "Not Available" 2 "Error" 1 "Operational" 0 "Not Operational" ;
VAL_ 2364659198 Module17OperationalStatus 3 "Not Available" 2 "Error" 1 "Operational" 0 "Not Operational" ;
VAL_ 2364659198 Module16OperationalStatus 3 "Not Available" 2 "Error" 1 "Operational" 0 "Not Operational" ;
VAL_ 2364659198 Module15OperationalStatus 3 "Not Available" 2 "Error" 1 "Operational" 0 "Not Operational" ;
VAL_ 2364659198 Module14OperationalStatus 3 "Not Available" 2 "Error" 1 "Operational" 0 "Not Operational" ;
VAL_ 2364659198 Module13OperationalStatus 3 "Not Available" 2 "Error" 1 "Operational" 0 "Not Operational" ;
VAL_ 2364659198 Module12OperationalStatus 3 "Not Available" 2 "Error" 1 "Operational" 0 "Not Operational" ;
VAL_ 2364659198 Module11OperationalStatus 3 "Not Available" 2 "Error" 1 "Operational" 0 "Not Operational" ;
VAL_ 2364659198 Module10OperationalStatus 3 "Not Available" 2 "Error" 1 "Operational" 0 "Not Operational" ;
VAL_ 2364659198 Module9OperationalStatus 3 "Not Available" 2 "Error" 1 "Operational" 0 "Not Operational" ;
VAL_ 2364659198 Module8OperationalStatus 3 "Not Available" 2 "Error" 1 "Operational" 0 "Not Operational" ;
VAL_ 2364659198 Module7OperationalStatus 3 "Not Available" 2 "Error" 1 "Operational" 0 "Not Operational" ;
VAL_ 2364659198 Module6OperationalStatus 3 "Not Available" 2 "Error" 1 "Operational" 0 "Not Operational" ;
VAL_ 2364659198 Module5OperationalStatus 3 "Not Available" 2 "Error" 1 "Operational" 0 "Not Operational" ;
VAL_ 2364659198 Module4OperationalStatus 3 "Not Available" 2 "Error" 1 "Operational" 0 "Not Operational" ;
VAL_ 2364659198 Module3OperationalStatus 3 "Not Available" 2 "Error" 1 "Operational" 0 "Not Operational" ;
VAL_ 2364659198 Module2OperationalStatus 3 "Not Available" 2 "Error" 1 "Operational" 0 "Not Operational" ;
VAL_ 2364659198 Module1OperationalStatus 3 "Not Available" 2 "Error" 1 "Operational" 0 "Not Operational" ;
VAL_ 2364658686 OperationalStatus 15 "Not Available" 14 "Error" 13 "Reserved" 12 "Reserved" 11 "Reserved" 10 "Reserved" 9 "Reserved" 8 "Reserved" 7 "Reserved" 6 "Disabled by internal decision of HVES controller" 5 "Disabled by external command" 4 "Emergency Power-Down In Process" 3 "Normal Power-Down in Process" 2 "Operational." 1 "Initialization Complete" 0 "Initialization in process" ;
VAL_ 2364658686 HVBusConnectionStatus 15 "Not Available" 14 "Error" 13 "Reserved" 12 "Reserved" 11 "Reserved" 10 "Reserved" 9 "Reserved" 8 "Reserved" 7 "Reserved" 6 "Reserved" 5 "Reserved" 4 "Disconnected,  Precharge Failed" 3 "Disconnection in Process" 2 "Connection in Process" 1 "Connected" 0 "Disconnected,  One or more contactors are open" ;
VAL_ 2364658686 InternalChargerStatus 3 "Not Available" 2 "Error" 1 "Charging on" 0 "Charging off" ;
VAL_ 2364658686 CellBalancingActive 3 "Not Available" 2 "Error" 1 "Cell balancing is active" 0 "Cell balancing is not active" ;
VAL_ 2364658686 CellBalanceStatus 3 "Not Available" 2 "Error" 1 "Cells are unbalanced" 0 "Cells are balanced" ;
VAL_ 2364658686 StOfChargeStatus 15 "Not  Available" 14 "Error" 13 "Reserved" 12 "Reserved" 11 "Reserved" 10 "Reserved" 9 "Reserved" 8 "Reserved" 7 "Reserved" 6 "SOC is above its recommended upper limit" 5 "SOC is at its recommended upper limit" 4 "SOC is approaching its recommended upper limit" 3 "SOC is below its recommended lower limit" 2 "SOC is at its recommended lower limit" 1 "SOC is approaching its recommended lower limit" 0 "SOC level is acceptable" ;
VAL_ 2364658686 InertiaSwStatus 3 "Not Available" 2 "Error" 1 "Impact sensed" 0 "No impact sensed" ;
VAL_ 2364658686 HVILStatus 3 "Not Available" 2 "Error" 1 "HVIL Open" 0 "HVIL Closed" ;
VAL_ 2364658686 HVBusPassiveIsolTestStatus 15 "Not available" 14 "Error" 13 "Reserved" 12 "Reserved" 11 "Reserved" 10 "Reserved" 9 "Reserved" 8 "Reserved" 7 "Reserved" 6 "Reserved" 5 "Test complete,  isolation fault" 4 "Test complete,  isolation marginal" 3 "Test complete,  isolation acceptable" 2 "Test in process" 1 "Test requested but not yet in process" 0 "No test requested / No test in process" ;
VAL_ 2364658686 HVBusActiveIsolTestStatus 15 "Not available" 14 "Error" 13 "Reserved" 12 "Reserved" 11 "Reserved" 10 "Reserved" 9 "Reserved" 8 "Reserved" 7 "Reserved" 6 "Reserved" 5 "Test complete,  isolation fault" 4 "Test complete,  isolation marginal" 3 "Test complete,  isolation acceptable" 2 "Test in process" 1 "Test requested but not yet in process" 0 "No test requested / No test in process" ;
VAL_ 2364658686 CenterOfPackContactorSt 3 "Not Available" 2 "Error" 1 "Contactor Closed" 0 "Contactor Open" ;
VAL_ 2364658686 HVBusPreChargeRelaySt 3 "Not Available" 2 "Error" 1 "Relay Closed" 0 "Relay Open" ;
VAL_ 2364658686 HVBusDisconnectForewarning 15 "Not Available" 14 "Error" 13 "Disconnect imminent" 12 "Reserved" 11 "Reserved" 10 "Reserved" 9 "Reserved" 8 "Reserved" 7 "Disconnect imminent due to battery pack current approaching maximum acceptable level" 6 "Disconnect imminent due to cell voltage approaching maximum acceptable level" 5 "Disconnect imminent due to cell voltage approaching minimum acceptable level" 4 "Disconnect imminent due to module voltage approaching maximum acceptable level" 3 "Disconnect imminent due to module voltage approaching minimum acceptable level" 2 "Disconnect imminent due to battery pack voltage approaching maximum acceptable level" 1 "Disconnect imminent due to battery pack voltage approaching minimum acceptable level" 0 "Disconnect not pending" ;
VAL_ 2364658686 HVBusContactorSt11540 3 "Not Available" 2 "Error" 1 "Contactor Closed" 0 "Contactor Open" ;
VAL_ 2364658686 HVBusContactorSt 3 "Not Available" 2 "Error" 1 "Contactor Closed" 0 "Contactor Open" ;
VAL_ 2364657662 CellTempDiffStatus 3 "Not Available" 2 "Error" 1 "Cell-to-cell temperature differential exceeds acceptable limits" 0 "Cell-to-cell temperature differential is within acceptable limits" ;
VAL_ 2364657406 CellVDiffStatus 15 "Not Available" 14 "Error" 13 "Reserved" 12 "Reserved" 11 "Reserved" 10 "Reserved" 9 "Reserved" 8 "Reserved" 7 "Reserved" 6 "Reserved" 5 "Reserved" 4 "Exceeds limits and it is not known whether balancing can restore performance" 3 "Exceeds limits and external maintenance balancing cannot restore performance" 2 "Exceeds limits and external maintenance balancing is required" 1 "Exceeds limits and can be corrected via auto-balancing" 0 "Is within acceptable limits" ;
VAL_ 2364656894 ChargePLDueToAnUndefinedCause 3 "Not Available" 2 "Error" 1 "Power limited for this reason" 0 "No power limit for this reason" ;
VAL_ 2364656894 ChargePLDueToBatCur 3 "Not Available" 2 "Error" 1 "Power limited for this reason" 0 "No power limit for this reason" ;
VAL_ 2364656894 ChargePLDueToBatOrCellV 3 "Not Available" 2 "Error" 1 "Power limited for this reason" 0 "No power limit for this reason" ;
VAL_ 2364656894 ChargePLDueToBatDiagCondition 3 "Not Available" 2 "Error" 1 "Power limited for this reason" 0 "No power limit for this reason" ;
VAL_ 2364656894 ChargePLDueToBatTemp 3 "Not Available" 2 "Error" 1 "Power limited for this reason" 0 "No power limit for this reason" ;
VAL_ 2364656894 ChargePLDueToStOfCharge 3 "Not Available" 2 "Error" 1 "Power limited for this reason" 0 "No power limit for this reason" ;
VAL_ 2364656894 DisPLDueToAnUndefinedCause 3 "Not Available" 2 "Error" 1 "Power limited for this reason" 0 "No power limit for this reason" ;
VAL_ 2364656894 DisPLDueToBatCur 3 "Not Available" 2 "Error" 1 "Power limited for this reason" 0 "No power limit for this reason" ;
VAL_ 2364656894 DisPLDueToBatOrCellV 3 "Not Available" 2 "Error" 1 "Power limited for this reason" 0 "No power limit for this reason" ;
VAL_ 2364656894 DisPLDueToBatDiagCondition 3 "Not Available" 2 "Error" 1 "Power limited for this reason" 0 "No power limit for this reason" ;
VAL_ 2364656894 DisPLDueToBatTemp 3 "Not Available" 2 "Error" 1 "Power limited for this reason" 0 "No power limit for this reason" ;
VAL_ 2364656894 DisPLDueToStOfCharge 3 "Not Available" 2 "Error" 1 "Power limited for this reason" 0 "No power limit for this reason" ;
VAL_ 2364656126 Data9EmbeddedIntegritySupport 3 "CRC and Counter are not supported by the sender" 2 "Reserved" 1 "Protection is supported using J1939-76 SHM" 0 "Embedded CRC and Counter are supported by the sender" ;
VAL_ 2364656126 HVESS4ThermalEventDetected 3 "Not available" 2 "Error" 1 "Thermal Event Detected" 0 "No Thermal Event Detected" ;
VAL_ 2364655614 TMSCoolantLvl 3 "Not Available" 2 "Error" 1 "Coolant Level is sufficient" 0 "Coolant Level is not sufficient" ;
VAL_ 2364655614 TMSMode 15 "Not Available" 14 "Faulted" 13 "Reserved" 12 "Reserved" 11 "Reserved" 10 "Reserved" 9 "Reserved" 8 "Reserved" 7 "Reserved" 6 "Reserved" 5 "Maintaining" 4 "Drying" 3 "Heating" 2 "Cooling" 1 "Circulating" 0 "Off" ;
VAL_ 2364655614 TMSHVILStatus 3 "Not Available" 2 "Error" 1 "HVIL Open" 0 "HVIL Closed" ;
VAL_ 2364655614 TMSHtrStatus 3 "Not Available" 2 "Error" 1 "Heater On" 0 "Heater Off" ;
VAL_ 2364655358 Module32OperationalStatus 3 "Not Available" 2 "Error" 1 "Operational" 0 "Not Operational" ;
VAL_ 2364655358 Module31OperationalStatus 3 "Not Available" 2 "Error" 1 "Operational" 0 "Not Operational" ;
VAL_ 2364655358 Module30OperationalStatus 3 "Not Available" 2 "Error" 1 "Operational" 0 "Not Operational" ;
VAL_ 2364655358 Module29OperationalStatus 3 "Not Available" 2 "Error" 1 "Operational" 0 "Not Operational" ;
VAL_ 2364655358 Module28OperationalStatus 3 "Not Available" 2 "Error" 1 "Operational" 0 "Not Operational" ;
VAL_ 2364655358 Module27OperationalStatus 3 "Not Available" 2 "Error" 1 "Operational" 0 "Not Operational" ;
VAL_ 2364655358 Module26OperationalStatus 3 "Not Available" 2 "Error" 1 "Operational" 0 "Not Operational" ;
VAL_ 2364655358 Module25OperationalStatus 3 "Not Available" 2 "Error" 1 "Operational" 0 "Not Operational" ;
VAL_ 2364655358 Module24OperationalStatus 3 "Not Available" 2 "Error" 1 "Operational" 0 "Not Operational" ;
VAL_ 2364655358 Module23OperationalStatus 3 "Not Available" 2 "Error" 1 "Operational" 0 "Not Operational" ;
VAL_ 2364655358 Module22OperationalStatus 3 "Not Available" 2 "Error" 1 "Operational" 0 "Not Operational" ;
VAL_ 2364655358 Module21OperationalStatus 3 "Not Available" 2 "Error" 1 "Operational" 0 "Not Operational" ;
VAL_ 2364655358 Module20OperationalStatus 3 "Not Available" 2 "Error" 1 "Operational" 0 "Not Operational" ;
VAL_ 2364655358 Module19OperationalStatus 3 "Not Available" 2 "Error" 1 "Operational" 0 "Not Operational" ;
VAL_ 2364655358 Module18OperationalStatus 3 "Not Available" 2 "Error" 1 "Operational" 0 "Not Operational" ;
VAL_ 2364655358 Module17OperationalStatus 3 "Not Available" 2 "Error" 1 "Operational" 0 "Not Operational" ;
VAL_ 2364655358 Module16OperationalStatus 3 "Not Available" 2 "Error" 1 "Operational" 0 "Not Operational" ;
VAL_ 2364655358 Module15OperationalStatus 3 "Not Available" 2 "Error" 1 "Operational" 0 "Not Operational" ;
VAL_ 2364655358 Module14OperationalStatus 3 "Not Available" 2 "Error" 1 "Operational" 0 "Not Operational" ;
VAL_ 2364655358 Module13OperationalStatus 3 "Not Available" 2 "Error" 1 "Operational" 0 "Not Operational" ;
VAL_ 2364655358 Module12OperationalStatus 3 "Not Available" 2 "Error" 1 "Operational" 0 "Not Operational" ;
VAL_ 2364655358 Module11OperationalStatus 3 "Not Available" 2 "Error" 1 "Operational" 0 "Not Operational" ;
VAL_ 2364655358 Module10OperationalStatus 3 "Not Available" 2 "Error" 1 "Operational" 0 "Not Operational" ;
VAL_ 2364655358 Module9OperationalStatus 3 "Not Available" 2 "Error" 1 "Operational" 0 "Not Operational" ;
VAL_ 2364655358 Module8OperationalStatus 3 "Not Available" 2 "Error" 1 "Operational" 0 "Not Operational" ;
VAL_ 2364655358 Module7OperationalStatus 3 "Not Available" 2 "Error" 1 "Operational" 0 "Not Operational" ;
VAL_ 2364655358 Module6OperationalStatus 3 "Not Available" 2 "Error" 1 "Operational" 0 "Not Operational" ;
VAL_ 2364655358 Module5OperationalStatus 3 "Not Available" 2 "Error" 1 "Operational" 0 "Not Operational" ;
VAL_ 2364655358 Module4OperationalStatus 3 "Not Available" 2 "Error" 1 "Operational" 0 "Not Operational" ;
VAL_ 2364655358 Module3OperationalStatus 3 "Not Available" 2 "Error" 1 "Operational" 0 "Not Operational" ;
VAL_ 2364655358 Module2OperationalStatus 3 "Not Available" 2 "Error" 1 "Operational" 0 "Not Operational" ;
VAL_ 2364655358 Module1OperationalStatus 3 "Not Available" 2 "Error" 1 "Operational" 0 "Not Operational" ;
VAL_ 2364654846 OperationalStatus 15 "Not Available" 14 "Error" 13 "Reserved" 12 "Reserved" 11 "Reserved" 10 "Reserved" 9 "Reserved" 8 "Reserved" 7 "Reserved" 6 "Disabled by internal decision of HVES controller" 5 "Disabled by external command" 4 "Emergency Power-Down In Process" 3 "Normal Power-Down in Process" 2 "Operational." 1 "Initialization Complete" 0 "Initialization in process" ;
VAL_ 2364654846 HVBusConnectionStatus 15 "Not Available" 14 "Error" 13 "Reserved" 12 "Reserved" 11 "Reserved" 10 "Reserved" 9 "Reserved" 8 "Reserved" 7 "Reserved" 6 "Reserved" 5 "Reserved" 4 "Disconnected,  Precharge Failed" 3 "Disconnection in Process" 2 "Connection in Process" 1 "Connected" 0 "Disconnected,  One or more contactors are open" ;
VAL_ 2364654846 InternalChargerStatus 3 "Not Available" 2 "Error" 1 "Charging on" 0 "Charging off" ;
VAL_ 2364654846 CellBalancingActive 3 "Not Available" 2 "Error" 1 "Cell balancing is active" 0 "Cell balancing is not active" ;
VAL_ 2364654846 CellBalanceStatus 3 "Not Available" 2 "Error" 1 "Cells are unbalanced" 0 "Cells are balanced" ;
VAL_ 2364654846 StOfChargeStatus 15 "Not  Available" 14 "Error" 13 "Reserved" 12 "Reserved" 11 "Reserved" 10 "Reserved" 9 "Reserved" 8 "Reserved" 7 "Reserved" 6 "SOC is above its recommended upper limit" 5 "SOC is at its recommended upper limit" 4 "SOC is approaching its recommended upper limit" 3 "SOC is below its recommended lower limit" 2 "SOC is at its recommended lower limit" 1 "SOC is approaching its recommended lower limit" 0 "SOC level is acceptable" ;
VAL_ 2364654846 InertiaSwStatus 3 "Not Available" 2 "Error" 1 "Impact sensed" 0 "No impact sensed" ;
VAL_ 2364654846 HVILStatus 3 "Not Available" 2 "Error" 1 "HVIL Open" 0 "HVIL Closed" ;
VAL_ 2364654846 HVBusPassiveIsolTestStatus 15 "Not available" 14 "Error" 13 "Reserved" 12 "Reserved" 11 "Reserved" 10 "Reserved" 9 "Reserved" 8 "Reserved" 7 "Reserved" 6 "Reserved" 5 "Test complete,  isolation fault" 4 "Test complete,  isolation marginal" 3 "Test complete,  isolation acceptable" 2 "Test in process" 1 "Test requested but not yet in process" 0 "No test requested / No test in process" ;
VAL_ 2364654846 HVBusActiveIsolTestStatus 15 "Not available" 14 "Error" 13 "Reserved" 12 "Reserved" 11 "Reserved" 10 "Reserved" 9 "Reserved" 8 "Reserved" 7 "Reserved" 6 "Reserved" 5 "Test complete,  isolation fault" 4 "Test complete,  isolation marginal" 3 "Test complete,  isolation acceptable" 2 "Test in process" 1 "Test requested but not yet in process" 0 "No test requested / No test in process" ;
VAL_ 2364654846 CenterOfPackContactorSt 3 "Not Available" 2 "Error" 1 "Contactor Closed" 0 "Contactor Open" ;
VAL_ 2364654846 HVBusPreChargeRelaySt 3 "Not Available" 2 "Error" 1 "Relay Closed" 0 "Relay Open" ;
VAL_ 2364654846 HVBusDisconnectForewarning 15 "Not Available" 14 "Error" 13 "Disconnect imminent" 12 "Reserved" 11 "Reserved" 10 "Reserved" 9 "Reserved" 8 "Reserved" 7 "Disconnect imminent due to battery pack current approaching maximum acceptable level" 6 "Disconnect imminent due to cell voltage approaching maximum acceptable level" 5 "Disconnect imminent due to cell voltage approaching minimum acceptable level" 4 "Disconnect imminent due to module voltage approaching maximum acceptable level" 3 "Disconnect imminent due to module voltage approaching minimum acceptable level" 2 "Disconnect imminent due to battery pack voltage approaching maximum acceptable level" 1 "Disconnect imminent due to battery pack voltage approaching minimum acceptable level" 0 "Disconnect not pending" ;
VAL_ 2364654846 HVBusContactorSt11424 3 "Not Available" 2 "Error" 1 "Contactor Closed" 0 "Contactor Open" ;
VAL_ 2364654846 HVBusContactorSt 3 "Not Available" 2 "Error" 1 "Contactor Closed" 0 "Contactor Open" ;
VAL_ 2364653822 CellTempDiffStatus 3 "Not Available" 2 "Error" 1 "Cell-to-cell temperature differential exceeds acceptable limits" 0 "Cell-to-cell temperature differential is within acceptable limits" ;
VAL_ 2364653566 CellVDiffStatus 15 "Not Available" 14 "Error" 13 "Reserved" 12 "Reserved" 11 "Reserved" 10 "Reserved" 9 "Reserved" 8 "Reserved" 7 "Reserved" 6 "Reserved" 5 "Reserved" 4 "Exceeds limits and it is not known whether balancing can restore performance" 3 "Exceeds limits and external maintenance balancing cannot restore performance" 2 "Exceeds limits and external maintenance balancing is required" 1 "Exceeds limits and can be corrected via auto-balancing" 0 "Is within acceptable limits" ;
